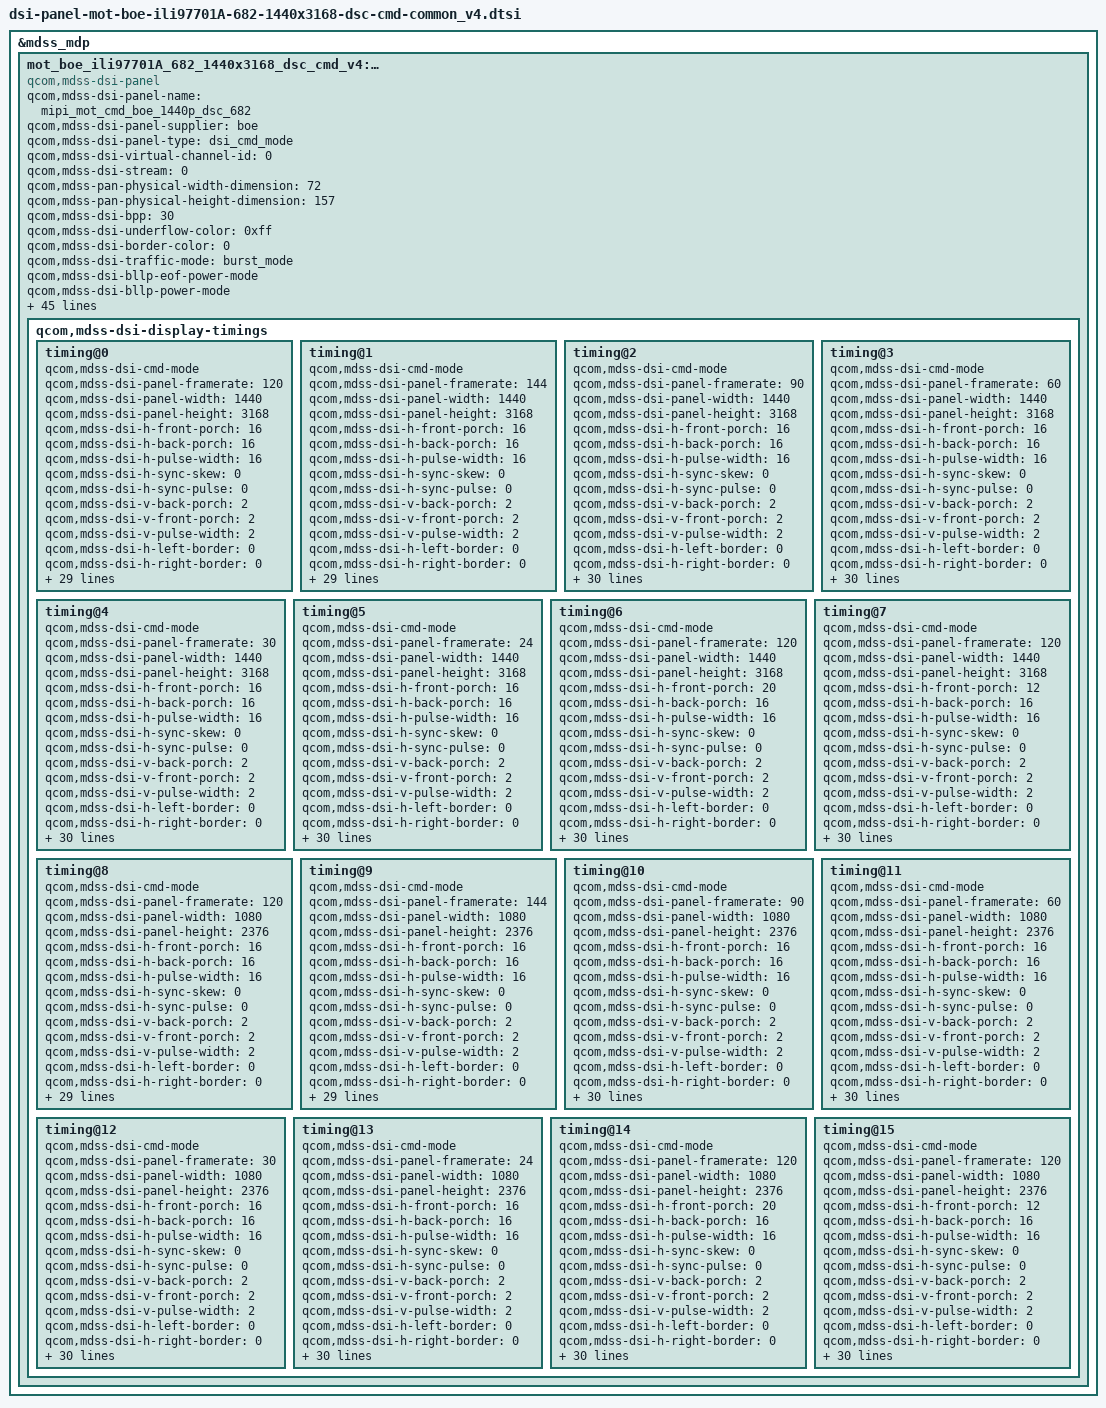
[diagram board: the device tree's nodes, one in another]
/* Copyright (c) 2025-2026, The Linux Foundation. All rights reserved.
 *
 * This program is free software; you can redistribute it and/or modify
 * it under the terms of the GNU General Public License version 2 and
 * only version 2 as published by the Free Software Foundation.
 *
 * This program is distributed in the hope that it will be useful,
 * but WITHOUT ANY WARRANTY; without even the implied warranty of
 * MERCHANTABILITY or FITNESS FOR A PARTICULAR PURPOSE.  See the
 * GNU General Public License for more details.
 */
&mdss_mdp {
mot_boe_ili97701A_682_1440x3168_dsc_cmd_v4: qcom,mdss_dsi_mot_boe_ili97701A_682_1440x3168_dsc_cmd_v4 {
compatible = "qcom,mdss-dsi-panel";
qcom,mdss-dsi-panel-name = "mipi_mot_cmd_boe_1440p_dsc_682";
qcom,mdss-dsi-panel-supplier = "boe";
qcom,mdss-dsi-panel-type = "dsi_cmd_mode";
qcom,mdss-dsi-virtual-channel-id = <0>;
qcom,mdss-dsi-stream = <0>;
qcom,mdss-pan-physical-width-dimension = <72>;
qcom,mdss-pan-physical-height-dimension = <157>;
qcom,mdss-dsi-bpp = <30>;
qcom,mdss-dsi-underflow-color = <0xff>;
qcom,mdss-dsi-border-color = <0>;

qcom,mdss-dsi-traffic-mode = "burst_mode";
qcom,mdss-dsi-bllp-eof-power-mode;
qcom,mdss-dsi-bllp-power-mode;
qcom,mdss-dsi-lane-0-state;
qcom,mdss-dsi-lane-1-state;
qcom,mdss-dsi-lane-2-state;
qcom,mdss-dsi-lane-3-state;

qcom,mdss-dsi-dma-trigger = "trigger_sw";
qcom,mdss-dsi-mdp-trigger = "none";
qcom,mdss-dsi-reset-sequence = <0 3>, <1 1>, <0 1>, <1 20>;
qcom,mdss-dsi-lp11-init;
qcom,mdss-dsi-tx-eot-append;
qcom,mdss-dsi-te-pin-select = <1>;
qcom,mdss-dsi-te-dcs-command = <1>;
qcom,mdss-dsi-te-using-te-pin;

//qcom,bklt-dcs-2bytes-enabled;
qcom,mdss-dsi-bl-min-level = <4>;
qcom,mdss-dsi-bl-max-level = <14056>;
qcom,mdss-dsi-bl-pmic-control-type = "bl_ctrl_dcs";

qcom,mdss-dsi-panel-hdr-enabled;
qcom,mdss-dsi-panel-hdr-color-primaries = <14500 15500 32000
	        17000 15500 30000 8000 3000>;
qcom,mdss-dsi-panel-peak-brightness = <4200000>;

qcom,mdss-dsi-panel-blackness-level = <3230>;

qcom,check_pcd;
qcom,pcd-reg-read-enabled;
qcom,pcd-reg-check-before-read;
qcom,mdss-dsi-panel-pcd-reg-read-length = <1>;
qcom,mdss-dsi-panel-pcd-reg-mask = <0xFF>;
qcom,mdss-dsi-panel-pcd-reg-command = [
		06 01 00 01 00 00 01 C5];
qcom,mdss-dsi-panel-pcd-reg-pass-min = <0x0>;
qcom,mdss-dsi-panel-pcd-reg-pass-max = <0x42>;
qcom,mdss-dsi-panel-pcd-reg-read-delay-ms = <0>; //150ms delay before read pcd reg per IC req
qcom,mdss-dsi-panel-pcd-reg-seq-interval = <30>; //30 seq interval per screen on times
qcom,mdss-dsi-panel-pcd-check-time-interval-in-minutes = <480>; //480 minutes check time interval for pcd reg read

qcom,mdss-dsi-hbm-fod;
qcom,mdss-dsi-hbm-fod-on-command = [
		39 00 00 40 00 00 04 FF 5A A5 00
		39 00 00 00 00 00 02 6E 03
		];

qcom,mdss-dsi-dc-off-command = [
			39 00 00 40 00 00 04 FF 5A A5 08
			39 00 00 40 00 00 02 98 02
			39 00 00 40 00 00 04 FF 5A A5 4F
			39 00 00 40 00 00 02 81 10
			39 00 00 40 00 00 02 88 78
			39 00 00 40 00 00 04 FF 5A A5 23
			39 00 00 40 00 00 02 A9 0E
			39 00 00 40 00 00 02 AA 11
			39 00 00 40 00 00 04 FF 5A A5 24
			39 00 00 40 00 00 02 9D 0E
			39 00 00 40 00 00 02 9E 11
			39 00 00 40 00 00 04 FF 5A A5 23
			39 00 00 40 00 00 02 80 50
			39 00 00 40 00 00 02 A6 FC
			39 00 00 40 00 00 02 A7 00
			39 00 00 40 00 00 04 FF 5A A5 53
			39 00 00 40 00 00 03 95 00 A0
			39 00 00 40 00 00 1f A2 10 10 10 10 48 10 10 10 4B 4B 10 10 10 10 48 10 10 10 4B 4B 10 10 10 10 48 10 10 10 4B 4B
			39 00 00 40 00 00 04 FF 5A A5 00
			39 00 00 40 00 00 02 00 00
			39 00 00 40 00 00 02 00 00
			39 00 00 40 00 00 04 FF 5A A5 53
			39 00 00 40 00 00 02 F0 01
			39 00 00 40 00 00 04 FF 5A A5 00
			39 00 00 40 00 00 02 00 00
			39 00 00 40 00 00 04 FF 5A A5 63
			39 00 00 40 00 00 11 F1 10 10 10 10 10 00 00 00 00 00 00 00 00 00 00 00
			39 00 00 40 00 00 11 F2 00 00 00 00 00 00 00 00 00 00 00 00 00 00 00 00
			39 00 00 40 00 00 11 F3 00 00 00 00 00 20 20 20 20 20 00 00 00 00 00 00
			39 00 00 40 00 00 11 F4 00 00 00 00 00 F0 F0 F0 F0 F0 00 00 00 00 00 00
			39 00 00 40 00 00 04 FF 5A A5 53
			39 00 00 40 00 00 02 F0 00
			39 00 00 40 00 00 04 FF 5A A5 00
			39 00 00 40 00 00 02 00 00
			39 00 00 40 00 00 02 00 00
			39 00 00 40 00 00 04 FF 5A A5 08
			39 00 00 40 00 00 02 98 A6
			39 00 00 40 00 00 04 FF 5A A5 00
			39 00 00 40 00 00 02 00 00
			39 00 00 40 00 00 04 FF 5A A5 4F
			39 00 00 40 00 00 02 8B 78
			39 00 00 40 00 00 04 FF 5A A5 51
			39 00 00 40 00 00 07 A1 44 44 79 7B 22 22
			39 00 00 40 00 00 07 A2 7E 7E 85 85 22 22
			39 00 00 40 00 00 04 FF 5A A5 52
			39 00 00 40 00 00 07 81 46 47 48 4B 00 00
			39 00 00 40 00 00 07 82 4E 4E 50 50 00 00
			39 00 00 40 00 00 04 FF 5A A5 00
			39 00 00 40 00 00 04 FF 5A A5 5A
			39 00 00 40 00 00 04 86 0A 1E 04
			39 00 00 40 00 00 04 8A 12 2E 0F
			39 00 00 40 00 00 04 8F 27 3E 23
			39 00 00 40 00 00 04 94 00 00 00
			39 00 00 40 00 00 04 95 26 24 16
			39 00 00 40 00 00 04 9B 00 00 00
			39 00 00 40 00 00 04 AE 10 2D 07
			39 00 00 40 00 00 04 B3 1C 21 22
			39 00 00 40 00 00 04 B9 24 1C 20
			39 00 00 40 00 00 04 BF 09 00 00
			39 00 00 40 00 00 04 FF 5A A5 5B
			39 00 00 40 00 00 04 DD 39 3A 42
			39 00 00 00 00 00 04 FF 5A A5 00
		];

qcom,mdss-dsi-dc-off-command-state = "dsi_hs_mode";
qcom,mdss-dsi-dc-on-command = [
			39 00 00 40 00 00 04 FF 5A A5 08
			39 00 00 40 00 00 02 98 02
			39 00 00 40 00 00 04 FF 5A A5 4F
			39 00 00 40 00 00 02 81 10
			39 00 00 40 00 00 02 88 78
			39 00 00 40 00 00 04 FF 5A A5 23
			39 00 00 40 00 00 02 A9 8E
			39 00 00 40 00 00 02 AA 11
			39 00 00 40 00 00 04 FF 5A A5 24
			39 00 00 40 00 00 02 9D 8E
			39 00 00 40 00 00 02 9E 11
			39 00 00 40 00 00 04 FF 5A A5 23
			39 00 00 40 00 00 02 80 90
			39 00 00 40 00 00 02 A6 FC
			39 00 00 40 00 00 02 A7 00
			39 00 00 40 00 00 04 FF 5A A5 53
			39 00 00 40 00 00 03 95 44 50
			39 00 00 40 00 00 1f A2 10 10 10 10 48 10 10 74 7B B4 10 10 10 10 48 10 10 74 7B B4 10 10 10 10 48 10 10 74 7B B4
			39 00 00 40 00 00 04 FF 5A A5 00
			39 00 00 40 00 00 02 00 00
			39 00 00 40 00 00 02 00 00
			39 00 00 40 00 00 04 FF 5A A5 53
			39 00 00 40 00 00 02 F0 01
			39 00 00 40 00 00 04 FF 5A A5 00
			39 00 00 40 00 00 02 00 00
			39 00 00 40 00 00 04 FF 5A A5 63
			39 00 00 40 00 00 11 F1 10 10 10 10 10 00 00 00 00 00 00 00 00 00 00 00
			39 00 00 40 00 00 11 F2 00 00 00 00 00 20 20 20 20 20 00 00 00 00 00 00
			39 00 00 40 00 00 11 F3 00 00 00 00 00 00 00 00 00 00 00 00 00 00 00 00
			39 00 00 40 00 00 11 F4 00 00 00 00 00 F0 F0 F0 F0 F0 00 00 00 00 00 00
			39 00 00 40 00 00 04 FF 5A A5 53
			39 00 00 40 00 00 02 F0 00
			39 00 00 40 00 00 04 FF 5A A5 00
			39 00 00 40 00 00 02 00 00
			39 00 00 40 00 00 02 00 00
			39 00 00 40 00 00 04 FF 5A A5 08
			39 00 00 40 00 00 02 98 A6
			39 00 00 40 00 00 04 FF 5A A5 00
			39 00 00 40 00 00 02 00 00
			39 00 00 40 00 00 04 FF 5A A5 4F
			39 00 00 40 00 00 02 8B 78
			39 00 00 40 00 00 04 FF 5A A5 51
			39 00 00 40 00 00 07 A1 44 44 79 79 22 22
			39 00 00 40 00 00 07 A2 78 78 78 78 22 22
			39 00 00 40 00 00 04 FF 5A A5 52
			39 00 00 40 00 00 07 81 46 47 49 48 00 00
			39 00 00 40 00 00 07 82 4A 4A 4B 4B 00 00
			39 00 00 40 00 00 04 FF 5A A5 00
			39 00 00 40 00 00 04 FF 5A A5 5A
			39 00 00 40 00 00 04 86 0A 1E 01
			39 00 00 40 00 00 04 8A 06 38 F4
			39 00 00 40 00 00 04 8F 17 30 F6
			39 00 00 40 00 00 04 94 FC 00 F6
			39 00 00 40 00 00 04 95 33 2A 0D
			39 00 00 40 00 00 04 9B 01 F8 FC
			39 00 00 40 00 00 04 AE 15 2D 07
			39 00 00 40 00 00 04 B3 22 21 22
			39 00 00 40 00 00 04 B9 3A 36 34
			39 00 00 40 00 00 04 BF 00 F8 FE
			39 00 00 40 00 00 04 FF 5A A5 5B
			39 00 00 40 00 00 04 DD 40 44 47
			39 00 00 00 00 00 04 FF 5A A5 00
		];
qcom,mdss-dsi-dc-on-command-state = "dsi_hs_mode";
//qcom,mdss-dsi-nt37705-dc-detect-fps;
//qcom,check_pcd;

qcom,mdss-dsi-display-timings {
	timing@0{
		qcom,mdss-dsi-cmd-mode;
		qcom,mdss-dsi-panel-framerate = <120>;
		qcom,mdss-dsi-panel-width = <1440>;
		qcom,mdss-dsi-panel-height = <3168>;
		qcom,mdss-dsi-h-front-porch = <16>;
		qcom,mdss-dsi-h-back-porch = <16>;
		qcom,mdss-dsi-h-pulse-width = <16>;
		qcom,mdss-dsi-h-sync-skew = <0>;
		qcom,mdss-dsi-h-sync-pulse = <0>;
		qcom,mdss-dsi-v-back-porch = <2>;
		qcom,mdss-dsi-v-front-porch = <2>;
		qcom,mdss-dsi-v-pulse-width = <2>;
		qcom,mdss-dsi-h-left-border = <0>;
		qcom,mdss-dsi-h-right-border = <0>;
		qcom,mdss-dsi-v-top-border = <0>;
		qcom,mdss-dsi-v-bottom-border = <0>;
	        qcom,mdss-dsi-panel-jitter = <0x20 0xa>;
	        qcom,mdss-dsi-timing-switch-command = [
	        	39 00 00 40 00 00 04 FF 5A A5 00 //120hz
			39 00 00 40 00 00 02 60 00
			39 00 00 40 00 00 02 53 20 //dimming disable
			39 00 00 40 00 00 04 FF 5A A5 2D
			39 00 00 40 00 00 02 83 00
			39 00 00 40 00 00 02 F2 00 //TE
			39 00 00 40 00 00 02 CD 01 //dimming disable
			39 00 00 40 00 00 04 FF 5A A5 24
			39 00 00 40 00 00 03 85 31 00 //dimming disable
			39 00 00 40 00 00 03 86 31 00 //dimming disable

			39 00 00 00 00 00 04 FF 5A A5 00

			39 00 00 40 00 00 04 FF 5A A5 00 //scale disable
			39 00 00 40 00 00 02 4B 00
			39 00 00 40 00 00 04 FF 5A A5 04
			39 00 00 40 00 00 02 CF 00
			39 00 00 40 00 00 02 D0 03
			39 00 00 40 00 00 02 D1 00
			39 00 00 40 00 00 02 D2 04
			39 00 00 40 00 00 02 D4 00
			39 00 00 40 00 00 02 D5 C0
			39 00 00 40 00 00 02 D6 00
			39 00 00 40 00 00 02 E0 04
			39 00 00 40 00 00 02 E1 38
			39 00 00 40 00 00 02 E2 09
			39 00 00 40 00 00 02 E3 48
			39 00 00 40 00 00 12 ED 00 00 04 C0 00 00 04 C0 00 33 00 00 00 00 00 00 00

			39 00 00 40 00 00 04 FF 5A A5 07 //10bit 3.75x
			39 00 00 40 00 00 02 8A 01
			39 00 00 40 00 00 03 8B A0 21
			39 00 00 40 00 00 0B 81 00 00 00 00 00 11 00 00 AB 30
                     	39 00 00 40 00 00 0B FE 80 0C 60 05 A0 00 16 02 D0 02
                     	39 00 00 40 00 00 0B FE D0 02 00 02 68 00 20 02 68 00
                     	39 00 00 40 00 00 0B FE 0A 00 0C 04 93 03 78 18 00 10
                     	39 00 00 40 00 00 0B FE F0 07 10 20 00 06 0F 0F 33 0E
                     	39 00 00 40 00 00 0B FE 1C 2A 38 46 54 62 69 70 77 79
                     	39 00 00 40 00 00 0B FE 7B 7D 7E 01 02 22 00 2A 40 2A
                     	39 00 00 40 00 00 0B FE BE 3A FC 3A FA 3A F8 3B 38 3B
                     	39 00 00 40 00 00 0B FE 78 3B B6 4B F6 4C 34 4C 74 5C
                     	39 00 00 40 00 00 0A FE 74 8C F4 00 00 00 00 00 00
			39 00 00 00 00 00 04 FF 5A A5 00
	        ];
		qcom,mdss-dsi-on-command = [
			39 00 00 40 00 00 04 FF 5A A5 07 //10bit 3.75x
			39 00 00 40 00 00 02 8A 01
			39 00 00 40 00 00 03 8B A0 21
			39 00 00 40 00 00 0B 81 00 00 00 00 00 11 00 00 AB 30
                     	39 00 00 40 00 00 0B FE 80 0C 60 05 A0 00 16 02 D0 02
                     	39 00 00 40 00 00 0B FE D0 02 00 02 68 00 20 02 68 00
                     	39 00 00 40 00 00 0B FE 0A 00 0C 04 93 03 78 18 00 10
                     	39 00 00 40 00 00 0B FE F0 07 10 20 00 06 0F 0F 33 0E
                     	39 00 00 40 00 00 0B FE 1C 2A 38 46 54 62 69 70 77 79
                     	39 00 00 40 00 00 0B FE 7B 7D 7E 01 02 22 00 2A 40 2A
                     	39 00 00 40 00 00 0B FE BE 3A FC 3A FA 3A F8 3B 38 3B
                     	39 00 00 40 00 00 0B FE 78 3B B6 4B F6 4C 34 4C 74 5C
                     	39 00 00 40 00 00 0A FE 74 8C F4 00 00 00 00 00 00

			39 00 00 40 00 00 04 FF 5A A5 07
			39 00 00 40 00 00 02 8A 01
			39 00 00 40 00 00 03 8B A0 21
			39 00 00 40 00 00 04 FF 5A A5 31
			39 00 00 40 00 00 02 D0 80
			39 00 00 40 00 00 04 FF 5A A5 08
			39 00 00 40 00 00 02 C8 62
			39 00 00 40 00 00 04 FF 5A A5 21
			39 00 00 40 00 00 02 A4 38
			39 00 00 40 00 00 04 FF 5A A5 23
			39 00 00 40 00 00 02 85 15
			39 00 00 40 00 00 04 FF 5A A5 00
			39 00 00 40 00 00 02 5E 01
			39 00 00 40 00 00 02 60 00
			39 00 00 40 00 00 02 61 0F
			39 00 00 40 00 00 02 6D 01
			39 00 00 40 00 00 02 35 00
			39 00 00 40 00 00 02 53 20
			39 00 00 40 00 00 03 51 00 00
			39 00 00 40 00 00 04 FF 5A A5 00

			39 00 00 40 00 00 04 FF 5A A5 03 //pcd
			39 00 00 40 00 00 02 BD 91
			39 00 00 40 00 00 04 FF 5A A5 00

			39 00 00 40 00 00 04 FF 5A A5 1E //lhbm
			39 00 00 40 00 00 02 C0 10
			39 00 00 40 00 00 04 C1 70 9C C9
			39 00 00 40 00 00 08 C2 FF FF FF 78 E5 7A F0
			39 00 00 40 00 00 27 C5 44 00 00 44 00 00 44 00 00 44 00 00 44 00 00 42 02 EB 21 23 90 10 08 00 00 00 00 00 00 00 00 00 00 00 00 00 00 00
			39 00 00 40 00 00 27 C7 55 FF FF 55 FF FF 54 10 FF 43 80 80 44 00 00 33 90 6B 32 0C AE 20 50 00 00 00 00 00 00 00 00 00 00 00 00 00 00 00
			39 00 00 40 00 00 09 C8 44 00 00 44 00 00 14 00
			39 00 00 40 00 00 02 C9 00
			39 00 00 40 00 00 1a CA EC EC ED ED EE EF F8 FF FC FC F2 FB FF FF FF FF FF FF FF FF FF FF FF FF FF
			39 00 00 40 00 00 1a CB F0 F0 F0 F1 F1 F2 FA FF FF FE EB F0 F2 FF FE FB FF F9 FF FF FF FF FF FF FF
			39 00 00 40 00 00 1a CC EC EC EC ED EE EF F9 FF FF FE E9 ED EF F1 F4 F5 F4 F4 FF FF FF FF FF FF FF
			39 00 00 40 00 00 04 FF 5A A5 24
			39 00 00 40 00 00 02 80 0E
			39 00 00 40 00 00 02 81 11
			39 00 00 40 00 00 02 84 1F
			39 00 00 40 00 00 04 FF 5A A5 00
			39 00 00 40 00 00 02 95 FF
			39 00 00 40 00 00 02 96 0B
			39 00 00 40 00 00 02 97 40
			39 00 00 40 00 00 02 98 02
			39 00 00 40 00 00 02 99 D0

			39 00 00 40 00 00 04 FF 5A A5 00 //120hz
			39 00 00 40 00 00 02 60 00
			39 00 00 40 00 00 02 53 20 //dimming disable
			39 00 00 40 00 00 04 FF 5A A5 2D
			39 00 00 40 00 00 02 83 00
			39 00 00 40 00 00 02 F2 00 //TE
			39 00 00 40 00 00 02 CD 01 //dimming disable
			39 00 00 40 00 00 04 FF 5A A5 24
			39 00 00 40 00 00 03 85 31 00 //dimming disable
			39 00 00 40 00 00 03 86 31 00 //dimming disable

			39 00 00 40 00 00 04 FF 5A A5 08 //esd check
			39 00 00 40 00 00 02 D2 01
			39 00 00 40 00 00 02 D3 00
			39 00 00 40 00 00 02 D4 00
			39 00 00 40 00 00 09 ED FF FF FF FF FF FF FF FF
			39 00 00 40 00 00 09 EE FF FF FF FF FF FF FF FF
			39 00 00 40 00 00 04 FF 5A A5 00

                     	39 00 00 40 00 00 04 FF 5A A5 2D //1hz transition frame
                     	39 00 00 40 00 00 02 97 03
                     	39 00 00 40 00 00 02 B1 03
                     	39 00 00 40 00 00 03 98 03 00
                     	39 00 00 40 00 00 03 99 05 00
                     	39 00 00 40 00 00 03 9A 0B 00
                     	39 00 00 40 00 00 03 9B 17 00
                     	39 00 00 40 00 00 03 A0 00 00
                     	39 00 00 40 00 00 03 A1 01 02

			39 00 00 40 00 00 04 FF 5A A5 08 //esd check fail fix
			39 00 00 40 00 00 02 F5 00
			39 00 00 40 00 00 02 F6 00
			39 00 00 40 00 00 02 F7 00

			39 00 00 40 00 00 04 FF 5A A5 2D //DBV DIMMING for low refreshrate
                     	39 00 00 40 00 00 02 CE 55

			39 00 00 40 00 00 04 FF 5A A5 00 //scale disable
			39 00 00 40 00 00 02 4B 00
			39 00 00 40 00 00 04 FF 5A A5 04
			39 00 00 40 00 00 02 CF 00
			39 00 00 40 00 00 02 D0 03
			39 00 00 40 00 00 02 D1 00
			39 00 00 40 00 00 02 D2 04
			39 00 00 40 00 00 02 D4 00
			39 00 00 40 00 00 02 D5 C0
			39 00 00 40 00 00 02 D6 00
			39 00 00 40 00 00 02 E0 04
			39 00 00 40 00 00 02 E1 38
			39 00 00 40 00 00 02 E2 09
			39 00 00 40 00 00 02 E3 48
			39 00 00 40 00 00 12 ED 00 00 04 C0 00 00 04 C0 00 33 00 00 00 00 00 00 00
			39 00 00 00 00 00 04 FF 5A A5 00

			05 00 00 00 78 00 01 11 //Delay 120ms
			05 00 00 00 14 00 01 29];	/* display on */
		qcom,mdss-dsi-off-command = [
			39 00 00 40 00 00 04 FF 5A A5 00
			05 00 00 00 14 00 01 28		/* display_off */
			05 00 00 00 BE 00 01 10];	/* enter sleep mode */

		qcom,mdss-dsi-on-command-state = "dsi_lp_mode";
		qcom,mdss-dsi-off-command-state = "dsi_lp_mode";
		qcom,mdss-dsi-timing-switch-command-state = "dsi_lp_mode";
		qcom,compression-mode = "dsc";
		/* Why QCOM doesn't use this, even it used 2 encoder
		 * as for that dsi_sw43404_amoled_cmd, for ex */
		/* qcom,mdss-dsc-encoders = <2>; */
		qcom,mdss-dsc-version = <0x11>;
		qcom,mdss-dsc-slice-height = <22>;
		qcom,mdss-dsc-slice-width = <720>;
		qcom,mdss-dsc-slice-per-pkt = <2>;
		qcom,mdss-dsc-bit-per-component = <10>;
		qcom,mdss-dsc-bit-per-pixel = <8>;
		qcom,mdss-dsc-block-prediction-enable;
		qcom,mdss-dsi-pcd-check-enable-command = [
			39 00 00 00 00 00 04 FF 5A A5 03
			];
		qcom,mdss-dsi-pcd-check-enable-command-state = "dsi_hs_mode";
		qcom,mdss-dsi-pcd-check-disable-command = [
			39 00 00 00 00 00 04 FF 5A A5 00
			];
		qcom,mdss-dsi-pcd-check-disable-command-state = "dsi_hs_mode";
	};
	timing@1{
		qcom,mdss-dsi-cmd-mode;
		qcom,mdss-dsi-panel-framerate = <144>;
		qcom,mdss-dsi-panel-width = <1440>;
		qcom,mdss-dsi-panel-height = <3168>;
		qcom,mdss-dsi-h-front-porch = <16>;
		qcom,mdss-dsi-h-back-porch = <16>;
		qcom,mdss-dsi-h-pulse-width = <16>;
		qcom,mdss-dsi-h-sync-skew = <0>;
		qcom,mdss-dsi-h-sync-pulse = <0>;
		qcom,mdss-dsi-v-back-porch = <2>;
		qcom,mdss-dsi-v-front-porch = <2>;
		qcom,mdss-dsi-v-pulse-width = <2>;
		qcom,mdss-dsi-h-left-border = <0>;
		qcom,mdss-dsi-h-right-border = <0>;
		qcom,mdss-dsi-v-top-border = <0>;
		qcom,mdss-dsi-v-bottom-border = <0>;
	        qcom,mdss-dsi-panel-jitter = <0x20 0xa>;
	        qcom,mdss-dsi-timing-switch-command = [
	        	39 00 00 40 00 00 04 FF 5A A5 00 //144hz
			39 00 00 40 00 00 02 60 01
			39 00 00 40 00 00 02 53 20 //dimming disable
			39 00 00 40 00 00 04 FF 5A A5 2D
			39 00 00 40 00 00 02 84 00
			39 00 00 40 00 00 02 CD 01 //dimming disable
			39 00 00 40 00 00 04 FF 5A A5 24
			39 00 00 40 00 00 03 85 31 00 //dimming disable
			39 00 00 40 00 00 03 86 31 00 //dimming disable
			39 00 00 00 00 00 04 FF 5A A5 00

			39 00 00 40 00 00 04 FF 5A A5 00 //scale disable
			39 00 00 40 00 00 02 4B 00
			39 00 00 40 00 00 04 FF 5A A5 04
			39 00 00 40 00 00 02 CF 00
			39 00 00 40 00 00 02 D0 03
			39 00 00 40 00 00 02 D1 00
			39 00 00 40 00 00 02 D2 04
			39 00 00 40 00 00 02 D4 00
			39 00 00 40 00 00 02 D5 C0
			39 00 00 40 00 00 02 D6 00
			39 00 00 40 00 00 02 E0 04
			39 00 00 40 00 00 02 E1 38
			39 00 00 40 00 00 02 E2 09
			39 00 00 40 00 00 02 E3 48
			39 00 00 40 00 00 12 ED 00 00 04 C0 00 00 04 C0 00 33 00 00 00 00 00 00 00

			39 00 00 40 00 00 04 FF 5A A5 07 //10bit 3.75x
			39 00 00 40 00 00 02 8A 01
			39 00 00 40 00 00 03 8B A0 21
			39 00 00 40 00 00 0B 81 00 00 00 00 00 11 00 00 AB 30
                     	39 00 00 40 00 00 0B FE 80 0C 60 05 A0 00 16 02 D0 02
                     	39 00 00 40 00 00 0B FE D0 02 00 02 68 00 20 02 68 00
                     	39 00 00 40 00 00 0B FE 0A 00 0C 04 93 03 78 18 00 10
                     	39 00 00 40 00 00 0B FE F0 07 10 20 00 06 0F 0F 33 0E
                     	39 00 00 40 00 00 0B FE 1C 2A 38 46 54 62 69 70 77 79
                     	39 00 00 40 00 00 0B FE 7B 7D 7E 01 02 22 00 2A 40 2A
                     	39 00 00 40 00 00 0B FE BE 3A FC 3A FA 3A F8 3B 38 3B
                     	39 00 00 40 00 00 0B FE 78 3B B6 4B F6 4C 34 4C 74 5C
                     	39 00 00 40 00 00 0A FE 74 8C F4 00 00 00 00 00 00
			39 00 00 00 00 00 04 FF 5A A5 00
	        ];
		qcom,mdss-dsi-on-command = [
			39 00 00 40 00 00 04 FF 5A A5 07 //10bit 3.75x
			39 00 00 40 00 00 02 8A 01
			39 00 00 40 00 00 03 8B A0 21
			39 00 00 40 00 00 0B 81 00 00 00 00 00 11 00 00 AB 30
                     	39 00 00 40 00 00 0B FE 80 0C 60 05 A0 00 16 02 D0 02
                     	39 00 00 40 00 00 0B FE D0 02 00 02 68 00 20 02 68 00
                     	39 00 00 40 00 00 0B FE 0A 00 0C 04 93 03 78 18 00 10
                     	39 00 00 40 00 00 0B FE F0 07 10 20 00 06 0F 0F 33 0E
                     	39 00 00 40 00 00 0B FE 1C 2A 38 46 54 62 69 70 77 79
                     	39 00 00 40 00 00 0B FE 7B 7D 7E 01 02 22 00 2A 40 2A
                     	39 00 00 40 00 00 0B FE BE 3A FC 3A FA 3A F8 3B 38 3B
                     	39 00 00 40 00 00 0B FE 78 3B B6 4B F6 4C 34 4C 74 5C
                     	39 00 00 40 00 00 0A FE 74 8C F4 00 00 00 00 00 00

			39 00 00 40 00 00 04 FF 5A A5 07
			39 00 00 40 00 00 02 8A 01
			39 00 00 40 00 00 03 8B A0 21
			39 00 00 40 00 00 04 FF 5A A5 31
			39 00 00 40 00 00 02 D0 80
			39 00 00 40 00 00 04 FF 5A A5 08
			39 00 00 40 00 00 02 C8 62
			39 00 00 40 00 00 04 FF 5A A5 21
			39 00 00 40 00 00 02 A4 38
			39 00 00 40 00 00 04 FF 5A A5 23
			39 00 00 40 00 00 02 85 15
			39 00 00 40 00 00 04 FF 5A A5 00
			39 00 00 40 00 00 02 5E 01
			39 00 00 40 00 00 02 60 00
			39 00 00 40 00 00 02 61 0F
			39 00 00 40 00 00 02 6D 01
			39 00 00 40 00 00 02 35 00
			39 00 00 40 00 00 02 53 20
			39 00 00 40 00 00 03 51 00 00
			39 00 00 40 00 00 04 FF 5A A5 00

			39 00 00 40 00 00 04 FF 5A A5 03 //pcd
			39 00 00 40 00 00 02 BD 91
			39 00 00 40 00 00 04 FF 5A A5 00

			39 00 00 40 00 00 04 FF 5A A5 1E //lhbm
			39 00 00 40 00 00 02 C0 10
			39 00 00 40 00 00 04 C1 70 9C C9
			39 00 00 40 00 00 08 C2 FF FF FF 78 E5 7A F0
			39 00 00 40 00 00 27 C5 44 00 00 44 00 00 44 00 00 44 00 00 44 00 00 42 02 EB 21 23 90 10 08 00 00 00 00 00 00 00 00 00 00 00 00 00 00 00
			39 00 00 40 00 00 27 C7 55 FF FF 55 FF FF 54 10 FF 43 80 80 44 00 00 33 90 6B 32 0C AE 20 50 00 00 00 00 00 00 00 00 00 00 00 00 00 00 00
			39 00 00 40 00 00 09 C8 44 00 00 44 00 00 14 00
			39 00 00 40 00 00 02 C9 00
			39 00 00 40 00 00 1a CA EC EC ED ED EE EF F8 FF FC FC F2 FB FF FF FF FF FF FF FF FF FF FF FF FF FF
			39 00 00 40 00 00 1a CB F0 F0 F0 F1 F1 F2 FA FF FF FE EB F0 F2 FF FE FB FF F9 FF FF FF FF FF FF FF
			39 00 00 40 00 00 1a CC EC EC EC ED EE EF F9 FF FF FE E9 ED EF F1 F4 F5 F4 F4 FF FF FF FF FF FF FF
			39 00 00 40 00 00 04 FF 5A A5 24
			39 00 00 40 00 00 02 80 0E
			39 00 00 40 00 00 02 81 11
			39 00 00 40 00 00 02 84 1F
			39 00 00 40 00 00 04 FF 5A A5 00
			39 00 00 40 00 00 02 95 FF
			39 00 00 40 00 00 02 96 0B
			39 00 00 40 00 00 02 97 40
			39 00 00 40 00 00 02 98 02
			39 00 00 40 00 00 02 99 D0

			39 00 00 40 00 00 04 FF 5A A5 00 //144hz
			39 00 00 40 00 00 02 60 01
			39 00 00 40 00 00 02 53 20 //dimming disable
			39 00 00 40 00 00 04 FF 5A A5 2D
			39 00 00 40 00 00 02 84 00
			39 00 00 40 00 00 02 CD 01 //dimming disable
			39 00 00 40 00 00 04 FF 5A A5 24
			39 00 00 40 00 00 03 85 31 00 //dimming disable
			39 00 00 40 00 00 03 86 31 00 //dimming disable

			39 00 00 40 00 00 04 FF 5A A5 08 //esd check
			39 00 00 40 00 00 02 D2 01
			39 00 00 40 00 00 02 D3 00
			39 00 00 40 00 00 02 D4 00
			39 00 00 40 00 00 09 ED FF FF FF FF FF FF FF FF
			39 00 00 40 00 00 09 EE FF FF FF FF FF FF FF FF
			39 00 00 40 00 00 04 FF 5A A5 00

                     	39 00 00 40 00 00 04 FF 5A A5 2D //1hz transition frame
                     	39 00 00 40 00 00 02 97 03
                     	39 00 00 40 00 00 02 B1 03
                     	39 00 00 40 00 00 03 98 03 00
                     	39 00 00 40 00 00 03 99 05 00
                     	39 00 00 40 00 00 03 9A 0B 00
                     	39 00 00 40 00 00 03 9B 17 00
                     	39 00 00 40 00 00 03 A0 00 00
                     	39 00 00 40 00 00 03 A1 01 02

			39 00 00 40 00 00 04 FF 5A A5 08 //esd check fail fix
			39 00 00 40 00 00 02 F5 00
			39 00 00 40 00 00 02 F6 00
			39 00 00 40 00 00 02 F7 00

			39 00 00 40 00 00 04 FF 5A A5 2D //DBV DIMMING for low refreshrate
                     	39 00 00 40 00 00 02 CE 55

			39 00 00 40 00 00 04 FF 5A A5 00 //scale disable
			39 00 00 40 00 00 02 4B 00
			39 00 00 40 00 00 04 FF 5A A5 04
			39 00 00 40 00 00 02 CF 00
			39 00 00 40 00 00 02 D0 03
			39 00 00 40 00 00 02 D1 00
			39 00 00 40 00 00 02 D2 04
			39 00 00 40 00 00 02 D4 00
			39 00 00 40 00 00 02 D5 C0
			39 00 00 40 00 00 02 D6 00
			39 00 00 40 00 00 02 E0 04
			39 00 00 40 00 00 02 E1 38
			39 00 00 40 00 00 02 E2 09
			39 00 00 40 00 00 02 E3 48
			39 00 00 40 00 00 12 ED 00 00 04 C0 00 00 04 C0 00 33 00 00 00 00 00 00 00
			39 00 00 00 00 00 04 FF 5A A5 00

			05 00 00 00 78 00 01 11 //Delay 120ms
			05 00 00 00 14 00 01 29];	/* display on */
		qcom,mdss-dsi-off-command = [
			39 00 00 40 00 00 04 FF 5A A5 00
			05 00 00 00 14 00 01 28		/* display_off */
			05 00 00 00 BE 00 01 10];	/* enter sleep mode */

		qcom,mdss-dsi-on-command-state = "dsi_lp_mode";
		qcom,mdss-dsi-off-command-state = "dsi_lp_mode";
		qcom,mdss-dsi-timing-switch-command-state = "dsi_lp_mode";
		qcom,compression-mode = "dsc";
		/* Why QCOM doesn't use this, even it used 2 encoder
		 * as for that dsi_sw43404_amoled_cmd, for ex */
		/* qcom,mdss-dsc-encoders = <2>; */
		qcom,mdss-dsc-version = <0x11>;
		qcom,mdss-dsc-slice-height = <22>;
		qcom,mdss-dsc-slice-width = <720>;
		qcom,mdss-dsc-slice-per-pkt = <2>;
		qcom,mdss-dsc-bit-per-component = <10>;
		qcom,mdss-dsc-bit-per-pixel = <8>;
		qcom,mdss-dsc-block-prediction-enable;
		qcom,mdss-dsi-pcd-check-enable-command = [
			39 00 00 00 00 00 04 FF 5A A5 03
			];
		qcom,mdss-dsi-pcd-check-enable-command-state = "dsi_hs_mode";
		qcom,mdss-dsi-pcd-check-disable-command = [
			39 00 00 00 00 00 04 FF 5A A5 00
			];
		qcom,mdss-dsi-pcd-check-disable-command-state = "dsi_hs_mode";
	};
	timing@2{
		qcom,mdss-dsi-cmd-mode;
		qcom,mdss-dsi-panel-framerate = <90>;
		qcom,mdss-dsi-panel-width = <1440>;
		qcom,mdss-dsi-panel-height = <3168>;
		qcom,mdss-dsi-h-front-porch = <16>;
		qcom,mdss-dsi-h-back-porch = <16>;
		qcom,mdss-dsi-h-pulse-width = <16>;
		qcom,mdss-dsi-h-sync-skew = <0>;
		qcom,mdss-dsi-h-sync-pulse = <0>;
		qcom,mdss-dsi-v-back-porch = <2>;
		qcom,mdss-dsi-v-front-porch = <2>;
		qcom,mdss-dsi-v-pulse-width = <2>;
		qcom,mdss-dsi-h-left-border = <0>;
		qcom,mdss-dsi-h-right-border = <0>;
		qcom,mdss-dsi-v-top-border = <0>;
		qcom,mdss-dsi-v-bottom-border = <0>;
	        qcom,mdss-dsi-panel-jitter = <0x20 0xa>;
	        qcom,mdss-mdp-transfer-time-us = <7933>;
	        qcom,mdss-dsi-timing-switch-command = [
	        	39 00 00 40 00 00 04 FF 5A A5 00 //90hz
			39 00 00 40 00 00 02 60 02
			39 00 00 40 00 00 02 53 20 //dimming disable
			39 00 00 40 00 00 04 FF 5A A5 2D
			39 00 00 40 00 00 02 85 00
			39 00 00 40 00 00 02 CD 01 //dimming disable
			39 00 00 40 00 00 04 FF 5A A5 24
			39 00 00 40 00 00 03 85 31 00 //dimming disable
			39 00 00 40 00 00 03 86 31 00 //dimming disable
			39 00 00 00 00 00 04 FF 5A A5 00

			39 00 00 40 00 00 04 FF 5A A5 00 //scale disable
			39 00 00 40 00 00 02 4B 00
			39 00 00 40 00 00 04 FF 5A A5 04
			39 00 00 40 00 00 02 CF 00
			39 00 00 40 00 00 02 D0 03
			39 00 00 40 00 00 02 D1 00
			39 00 00 40 00 00 02 D2 04
			39 00 00 40 00 00 02 D4 00
			39 00 00 40 00 00 02 D5 C0
			39 00 00 40 00 00 02 D6 00
			39 00 00 40 00 00 02 E0 04
			39 00 00 40 00 00 02 E1 38
			39 00 00 40 00 00 02 E2 09
			39 00 00 40 00 00 02 E3 48
			39 00 00 40 00 00 12 ED 00 00 04 C0 00 00 04 C0 00 33 00 00 00 00 00 00 00

			39 00 00 40 00 00 04 FF 5A A5 07 //10bit 3.75x
			39 00 00 40 00 00 02 8A 01
			39 00 00 40 00 00 03 8B A0 21
			39 00 00 40 00 00 0B 81 00 00 00 00 00 11 00 00 AB 30
                     	39 00 00 40 00 00 0B FE 80 0C 60 05 A0 00 16 02 D0 02
                     	39 00 00 40 00 00 0B FE D0 02 00 02 68 00 20 02 68 00
                     	39 00 00 40 00 00 0B FE 0A 00 0C 04 93 03 78 18 00 10
                     	39 00 00 40 00 00 0B FE F0 07 10 20 00 06 0F 0F 33 0E
                     	39 00 00 40 00 00 0B FE 1C 2A 38 46 54 62 69 70 77 79
                     	39 00 00 40 00 00 0B FE 7B 7D 7E 01 02 22 00 2A 40 2A
                     	39 00 00 40 00 00 0B FE BE 3A FC 3A FA 3A F8 3B 38 3B
                     	39 00 00 40 00 00 0B FE 78 3B B6 4B F6 4C 34 4C 74 5C
                     	39 00 00 40 00 00 0A FE 74 8C F4 00 00 00 00 00 00
			39 00 00 00 00 00 04 FF 5A A5 00
	        ];
		qcom,mdss-dsi-on-command = [
			39 00 00 40 00 00 04 FF 5A A5 07 //10bit 3.75x
			39 00 00 40 00 00 02 8A 01
			39 00 00 40 00 00 03 8B A0 21
			39 00 00 40 00 00 0B 81 00 00 00 00 00 11 00 00 AB 30
                     	39 00 00 40 00 00 0B FE 80 0C 60 05 A0 00 16 02 D0 02
                     	39 00 00 40 00 00 0B FE D0 02 00 02 68 00 20 02 68 00
                     	39 00 00 40 00 00 0B FE 0A 00 0C 04 93 03 78 18 00 10
                     	39 00 00 40 00 00 0B FE F0 07 10 20 00 06 0F 0F 33 0E
                     	39 00 00 40 00 00 0B FE 1C 2A 38 46 54 62 69 70 77 79
                     	39 00 00 40 00 00 0B FE 7B 7D 7E 01 02 22 00 2A 40 2A
                     	39 00 00 40 00 00 0B FE BE 3A FC 3A FA 3A F8 3B 38 3B
                     	39 00 00 40 00 00 0B FE 78 3B B6 4B F6 4C 34 4C 74 5C
                     	39 00 00 40 00 00 0A FE 74 8C F4 00 00 00 00 00 00

			39 00 00 40 00 00 04 FF 5A A5 07
			39 00 00 40 00 00 02 8A 01
			39 00 00 40 00 00 03 8B A0 21
			39 00 00 40 00 00 04 FF 5A A5 31
			39 00 00 40 00 00 02 D0 80
			39 00 00 40 00 00 04 FF 5A A5 08
			39 00 00 40 00 00 02 C8 62
			39 00 00 40 00 00 04 FF 5A A5 21
			39 00 00 40 00 00 02 A4 38
			39 00 00 40 00 00 04 FF 5A A5 23
			39 00 00 40 00 00 02 85 15
			39 00 00 40 00 00 04 FF 5A A5 00
			39 00 00 40 00 00 02 5E 01
			39 00 00 40 00 00 02 60 00
			39 00 00 40 00 00 02 61 0F
			39 00 00 40 00 00 02 6D 01
			39 00 00 40 00 00 02 35 00
			39 00 00 40 00 00 02 53 20
			39 00 00 40 00 00 03 51 00 00
			39 00 00 40 00 00 04 FF 5A A5 00

			39 00 00 40 00 00 04 FF 5A A5 03 //pcd
			39 00 00 40 00 00 02 BD 91
			39 00 00 40 00 00 04 FF 5A A5 00

			39 00 00 40 00 00 04 FF 5A A5 1E //lhbm
			39 00 00 40 00 00 02 C0 10
			39 00 00 40 00 00 04 C1 70 9C C9
			39 00 00 40 00 00 08 C2 FF FF FF 78 E5 7A F0
			39 00 00 40 00 00 27 C5 44 00 00 44 00 00 44 00 00 44 00 00 44 00 00 42 02 EB 21 23 90 10 08 00 00 00 00 00 00 00 00 00 00 00 00 00 00 00
			39 00 00 40 00 00 27 C7 55 FF FF 55 FF FF 54 10 FF 43 80 80 44 00 00 33 90 6B 32 0C AE 20 50 00 00 00 00 00 00 00 00 00 00 00 00 00 00 00
			39 00 00 40 00 00 09 C8 44 00 00 44 00 00 14 00
			39 00 00 40 00 00 02 C9 00
			39 00 00 40 00 00 1a CA EC EC ED ED EE EF F8 FF FC FC F2 FB FF FF FF FF FF FF FF FF FF FF FF FF FF
			39 00 00 40 00 00 1a CB F0 F0 F0 F1 F1 F2 FA FF FF FE EB F0 F2 FF FE FB FF F9 FF FF FF FF FF FF FF
			39 00 00 40 00 00 1a CC EC EC EC ED EE EF F9 FF FF FE E9 ED EF F1 F4 F5 F4 F4 FF FF FF FF FF FF FF
			39 00 00 40 00 00 04 FF 5A A5 24
			39 00 00 40 00 00 02 80 0E
			39 00 00 40 00 00 02 81 11
			39 00 00 40 00 00 02 84 1F
			39 00 00 40 00 00 04 FF 5A A5 00
			39 00 00 40 00 00 02 95 FF
			39 00 00 40 00 00 02 96 0B
			39 00 00 40 00 00 02 97 40
			39 00 00 40 00 00 02 98 02
			39 00 00 40 00 00 02 99 D0

			39 00 00 40 00 00 04 FF 5A A5 00 //90hz
			39 00 00 40 00 00 02 60 02
			39 00 00 40 00 00 02 53 20 //dimming disable
			39 00 00 40 00 00 04 FF 5A A5 2D
			39 00 00 40 00 00 02 85 00
			39 00 00 40 00 00 02 CD 01 //dimming disable
			39 00 00 40 00 00 04 FF 5A A5 24
			39 00 00 40 00 00 03 85 31 00 //dimming disable
			39 00 00 40 00 00 03 86 31 00 //dimming disable

			39 00 00 40 00 00 04 FF 5A A5 08 //esd check
			39 00 00 40 00 00 02 D2 01
			39 00 00 40 00 00 02 D3 00
			39 00 00 40 00 00 02 D4 00
			39 00 00 40 00 00 09 ED FF FF FF FF FF FF FF FF
			39 00 00 40 00 00 09 EE FF FF FF FF FF FF FF FF
			39 00 00 40 00 00 04 FF 5A A5 00

                     	39 00 00 40 00 00 04 FF 5A A5 2D //1hz transition frame
                     	39 00 00 40 00 00 02 97 03
                     	39 00 00 40 00 00 02 B1 03
                     	39 00 00 40 00 00 03 98 03 00
                     	39 00 00 40 00 00 03 99 05 00
                     	39 00 00 40 00 00 03 9A 0B 00
                     	39 00 00 40 00 00 03 9B 17 00
                     	39 00 00 40 00 00 03 A0 00 00
                     	39 00 00 40 00 00 03 A1 01 02

			39 00 00 40 00 00 04 FF 5A A5 08 //esd check fail fix
			39 00 00 40 00 00 02 F5 00
			39 00 00 40 00 00 02 F6 00
			39 00 00 40 00 00 02 F7 00

			39 00 00 40 00 00 04 FF 5A A5 2D //DBV DIMMING for low refreshrate
                     	39 00 00 40 00 00 02 CE 55

			39 00 00 40 00 00 04 FF 5A A5 00 //scale disable
			39 00 00 40 00 00 02 4B 00
			39 00 00 40 00 00 04 FF 5A A5 04
			39 00 00 40 00 00 02 CF 00
			39 00 00 40 00 00 02 D0 03
			39 00 00 40 00 00 02 D1 00
			39 00 00 40 00 00 02 D2 04
			39 00 00 40 00 00 02 D4 00
			39 00 00 40 00 00 02 D5 C0
			39 00 00 40 00 00 02 D6 00
			39 00 00 40 00 00 02 E0 04
			39 00 00 40 00 00 02 E1 38
			39 00 00 40 00 00 02 E2 09
			39 00 00 40 00 00 02 E3 48
			39 00 00 40 00 00 12 ED 00 00 04 C0 00 00 04 C0 00 33 00 00 00 00 00 00 00
			39 00 00 00 00 00 04 FF 5A A5 00

			05 00 00 00 78 00 01 11 //Delay 120ms
			05 00 00 00 14 00 01 29];	/* display on */
		qcom,mdss-dsi-off-command = [
			39 00 00 40 00 00 04 FF 5A A5 00
			05 00 00 00 14 00 01 28		/* display_off */
			05 00 00 00 BE 00 01 10];	/* enter sleep mode */

		qcom,mdss-dsi-on-command-state = "dsi_lp_mode";
		qcom,mdss-dsi-off-command-state = "dsi_lp_mode";
		qcom,mdss-dsi-timing-switch-command-state = "dsi_lp_mode";
		qcom,compression-mode = "dsc";
		/* Why QCOM doesn't use this, even it used 2 encoder
		 * as for that dsi_sw43404_amoled_cmd, for ex */
		/* qcom,mdss-dsc-encoders = <2>; */
		qcom,mdss-dsc-version = <0x11>;
		qcom,mdss-dsc-slice-height = <22>;
		qcom,mdss-dsc-slice-width = <720>;
		qcom,mdss-dsc-slice-per-pkt = <2>;
		qcom,mdss-dsc-bit-per-component = <10>;
		qcom,mdss-dsc-bit-per-pixel = <8>;
		qcom,mdss-dsc-block-prediction-enable;
		qcom,mdss-dsi-pcd-check-enable-command = [
			39 00 00 00 00 00 04 FF 5A A5 03
			];
		qcom,mdss-dsi-pcd-check-enable-command-state = "dsi_hs_mode";
		qcom,mdss-dsi-pcd-check-disable-command = [
			39 00 00 00 00 00 04 FF 5A A5 00
			];
		qcom,mdss-dsi-pcd-check-disable-command-state = "dsi_hs_mode";
	};
	timing@3{
		qcom,mdss-dsi-cmd-mode;
		qcom,mdss-dsi-panel-framerate = <60>;
		qcom,mdss-dsi-panel-width = <1440>;
		qcom,mdss-dsi-panel-height = <3168>;
		qcom,mdss-dsi-h-front-porch = <16>;
		qcom,mdss-dsi-h-back-porch = <16>;
		qcom,mdss-dsi-h-pulse-width = <16>;
		qcom,mdss-dsi-h-sync-skew = <0>;
		qcom,mdss-dsi-h-sync-pulse = <0>;
		qcom,mdss-dsi-v-back-porch = <2>;
		qcom,mdss-dsi-v-front-porch = <2>;
		qcom,mdss-dsi-v-pulse-width = <2>;
		qcom,mdss-dsi-h-left-border = <0>;
		qcom,mdss-dsi-h-right-border = <0>;
		qcom,mdss-dsi-v-top-border = <0>;
		qcom,mdss-dsi-v-bottom-border = <0>;
	        qcom,mdss-dsi-panel-jitter = <0x20 0xa>;
	        qcom,mdss-mdp-transfer-time-us = <7933>;
	        qcom,mdss-dsi-timing-switch-command = [
	        	39 00 00 40 00 00 04 FF 5A A5 00 //60hz
			39 00 00 40 00 00 02 60 00
			39 00 00 40 00 00 02 53 20 //dimming disable
			39 00 00 40 00 00 04 FF 5A A5 2D
			39 00 00 40 00 00 02 83 01
			39 00 00 40 00 00 02 F2 01 //TE
			39 00 00 40 00 00 02 CD 01 //dimming disable
			39 00 00 40 00 00 04 FF 5A A5 24
			39 00 00 40 00 00 03 85 31 00 //dimming disable
			39 00 00 40 00 00 03 86 31 00 //dimming disable
			39 00 00 00 00 00 04 FF 5A A5 00

			39 00 00 40 00 00 04 FF 5A A5 00 //scale disable
			39 00 00 40 00 00 02 4B 00
			39 00 00 40 00 00 04 FF 5A A5 04
			39 00 00 40 00 00 02 CF 00
			39 00 00 40 00 00 02 D0 03
			39 00 00 40 00 00 02 D1 00
			39 00 00 40 00 00 02 D2 04
			39 00 00 40 00 00 02 D4 00
			39 00 00 40 00 00 02 D5 C0
			39 00 00 40 00 00 02 D6 00
			39 00 00 40 00 00 02 E0 04
			39 00 00 40 00 00 02 E1 38
			39 00 00 40 00 00 02 E2 09
			39 00 00 40 00 00 02 E3 48
			39 00 00 40 00 00 12 ED 00 00 04 C0 00 00 04 C0 00 33 00 00 00 00 00 00 00

			39 00 00 40 00 00 04 FF 5A A5 07 //10bit 3.75x
			39 00 00 40 00 00 02 8A 01
			39 00 00 40 00 00 03 8B A0 21
			39 00 00 40 00 00 0B 81 00 00 00 00 00 11 00 00 AB 30
                     	39 00 00 40 00 00 0B FE 80 0C 60 05 A0 00 16 02 D0 02
                     	39 00 00 40 00 00 0B FE D0 02 00 02 68 00 20 02 68 00
                     	39 00 00 40 00 00 0B FE 0A 00 0C 04 93 03 78 18 00 10
                     	39 00 00 40 00 00 0B FE F0 07 10 20 00 06 0F 0F 33 0E
                     	39 00 00 40 00 00 0B FE 1C 2A 38 46 54 62 69 70 77 79
                     	39 00 00 40 00 00 0B FE 7B 7D 7E 01 02 22 00 2A 40 2A
                     	39 00 00 40 00 00 0B FE BE 3A FC 3A FA 3A F8 3B 38 3B
                     	39 00 00 40 00 00 0B FE 78 3B B6 4B F6 4C 34 4C 74 5C
                     	39 00 00 40 00 00 0A FE 74 8C F4 00 00 00 00 00 00
			39 00 00 00 00 00 04 FF 5A A5 00
	        ];
		qcom,mdss-dsi-on-command = [
			39 00 00 40 00 00 04 FF 5A A5 07 //10bit 3.75x
			39 00 00 40 00 00 02 8A 01
			39 00 00 40 00 00 03 8B A0 21
			39 00 00 40 00 00 0B 81 00 00 00 00 00 11 00 00 AB 30
                     	39 00 00 40 00 00 0B FE 80 0C 60 05 A0 00 16 02 D0 02
                     	39 00 00 40 00 00 0B FE D0 02 00 02 68 00 20 02 68 00
                     	39 00 00 40 00 00 0B FE 0A 00 0C 04 93 03 78 18 00 10
                     	39 00 00 40 00 00 0B FE F0 07 10 20 00 06 0F 0F 33 0E
                     	39 00 00 40 00 00 0B FE 1C 2A 38 46 54 62 69 70 77 79
                     	39 00 00 40 00 00 0B FE 7B 7D 7E 01 02 22 00 2A 40 2A
                     	39 00 00 40 00 00 0B FE BE 3A FC 3A FA 3A F8 3B 38 3B
                     	39 00 00 40 00 00 0B FE 78 3B B6 4B F6 4C 34 4C 74 5C
                     	39 00 00 40 00 00 0A FE 74 8C F4 00 00 00 00 00 00

			39 00 00 40 00 00 04 FF 5A A5 07
			39 00 00 40 00 00 02 8A 01
			39 00 00 40 00 00 03 8B A0 21
			39 00 00 40 00 00 04 FF 5A A5 31
			39 00 00 40 00 00 02 D0 80
			39 00 00 40 00 00 04 FF 5A A5 08
			39 00 00 40 00 00 02 C8 62
			39 00 00 40 00 00 04 FF 5A A5 21
			39 00 00 40 00 00 02 A4 38
			39 00 00 40 00 00 04 FF 5A A5 23
			39 00 00 40 00 00 02 85 15
			39 00 00 40 00 00 04 FF 5A A5 00
			39 00 00 40 00 00 02 5E 01
			39 00 00 40 00 00 02 60 00
			39 00 00 40 00 00 02 61 0F
			39 00 00 40 00 00 02 6D 01
			39 00 00 40 00 00 02 35 00
			39 00 00 40 00 00 02 53 20
			39 00 00 40 00 00 03 51 00 00
			39 00 00 40 00 00 04 FF 5A A5 00

			39 00 00 40 00 00 04 FF 5A A5 03 //pcd
			39 00 00 40 00 00 02 BD 91
			39 00 00 40 00 00 04 FF 5A A5 00

			39 00 00 40 00 00 04 FF 5A A5 1E //lhbm
			39 00 00 40 00 00 02 C0 10
			39 00 00 40 00 00 04 C1 70 9C C9
			39 00 00 40 00 00 08 C2 FF FF FF 78 E5 7A F0
			39 00 00 40 00 00 27 C5 44 00 00 44 00 00 44 00 00 44 00 00 44 00 00 42 02 EB 21 23 90 10 08 00 00 00 00 00 00 00 00 00 00 00 00 00 00 00
			39 00 00 40 00 00 27 C7 55 FF FF 55 FF FF 54 10 FF 43 80 80 44 00 00 33 90 6B 32 0C AE 20 50 00 00 00 00 00 00 00 00 00 00 00 00 00 00 00
			39 00 00 40 00 00 09 C8 44 00 00 44 00 00 14 00
			39 00 00 40 00 00 02 C9 00
			39 00 00 40 00 00 1a CA EC EC ED ED EE EF F8 FF FC FC F2 FB FF FF FF FF FF FF FF FF FF FF FF FF FF
			39 00 00 40 00 00 1a CB F0 F0 F0 F1 F1 F2 FA FF FF FE EB F0 F2 FF FE FB FF F9 FF FF FF FF FF FF FF
			39 00 00 40 00 00 1a CC EC EC EC ED EE EF F9 FF FF FE E9 ED EF F1 F4 F5 F4 F4 FF FF FF FF FF FF FF
			39 00 00 40 00 00 04 FF 5A A5 24
			39 00 00 40 00 00 02 80 0E
			39 00 00 40 00 00 02 81 11
			39 00 00 40 00 00 02 84 1F
			39 00 00 40 00 00 04 FF 5A A5 00
			39 00 00 40 00 00 02 95 FF
			39 00 00 40 00 00 02 96 0B
			39 00 00 40 00 00 02 97 40
			39 00 00 40 00 00 02 98 02
			39 00 00 40 00 00 02 99 D0

			39 00 00 40 00 00 04 FF 5A A5 00 //60hz
			39 00 00 40 00 00 02 60 00
			39 00 00 40 00 00 02 53 20 //dimming disable
			39 00 00 40 00 00 04 FF 5A A5 2D
			39 00 00 40 00 00 02 83 01
			39 00 00 40 00 00 02 F2 01 //TE
			39 00 00 40 00 00 02 CD 01 //dimming disable
			39 00 00 40 00 00 04 FF 5A A5 24
			39 00 00 40 00 00 03 85 31 00 //dimming disable
			39 00 00 40 00 00 03 86 31 00 //dimming disable

			39 00 00 40 00 00 04 FF 5A A5 08 //esd check
			39 00 00 40 00 00 02 D2 01
			39 00 00 40 00 00 02 D3 00
			39 00 00 40 00 00 02 D4 00
			39 00 00 40 00 00 09 ED FF FF FF FF FF FF FF FF
			39 00 00 40 00 00 09 EE FF FF FF FF FF FF FF FF
			39 00 00 40 00 00 04 FF 5A A5 00

                     	39 00 00 40 00 00 04 FF 5A A5 2D //1hz transition frame
                     	39 00 00 40 00 00 02 97 03
                     	39 00 00 40 00 00 02 B1 03
                     	39 00 00 40 00 00 03 98 03 00
                     	39 00 00 40 00 00 03 99 05 00
                     	39 00 00 40 00 00 03 9A 0B 00
                     	39 00 00 40 00 00 03 9B 17 00
                     	39 00 00 40 00 00 03 A0 00 00
                     	39 00 00 40 00 00 03 A1 01 02

			39 00 00 40 00 00 04 FF 5A A5 08 //esd check fail fix
			39 00 00 40 00 00 02 F5 00
			39 00 00 40 00 00 02 F6 00
			39 00 00 40 00 00 02 F7 00

			39 00 00 40 00 00 04 FF 5A A5 2D //DBV DIMMING for low refreshrate
                     	39 00 00 40 00 00 02 CE 55

			39 00 00 40 00 00 04 FF 5A A5 00 //scale disable
			39 00 00 40 00 00 02 4B 00
			39 00 00 40 00 00 04 FF 5A A5 04
			39 00 00 40 00 00 02 CF 00
			39 00 00 40 00 00 02 D0 03
			39 00 00 40 00 00 02 D1 00
			39 00 00 40 00 00 02 D2 04
			39 00 00 40 00 00 02 D4 00
			39 00 00 40 00 00 02 D5 C0
			39 00 00 40 00 00 02 D6 00
			39 00 00 40 00 00 02 E0 04
			39 00 00 40 00 00 02 E1 38
			39 00 00 40 00 00 02 E2 09
			39 00 00 40 00 00 02 E3 48
			39 00 00 40 00 00 12 ED 00 00 04 C0 00 00 04 C0 00 33 00 00 00 00 00 00 00
			39 00 00 00 00 00 04 FF 5A A5 00

			05 00 00 00 78 00 01 11 //Delay 120ms
			05 00 00 00 14 00 01 29];	/* display on */
		qcom,mdss-dsi-off-command = [
			39 00 00 40 00 00 04 FF 5A A5 00
			05 00 00 00 14 00 01 28		/* display_off */
			05 00 00 00 BE 00 01 10];	/* enter sleep mode */

		qcom,mdss-dsi-on-command-state = "dsi_lp_mode";
		qcom,mdss-dsi-off-command-state = "dsi_lp_mode";
		qcom,mdss-dsi-timing-switch-command-state = "dsi_lp_mode";
		qcom,compression-mode = "dsc";
		/* Why QCOM doesn't use this, even it used 2 encoder
		 * as for that dsi_sw43404_amoled_cmd, for ex */
		/* qcom,mdss-dsc-encoders = <2>; */
		qcom,mdss-dsc-version = <0x11>;
		qcom,mdss-dsc-slice-height = <22>;
		qcom,mdss-dsc-slice-width = <720>;
		qcom,mdss-dsc-slice-per-pkt = <2>;
		qcom,mdss-dsc-bit-per-component = <10>;
		qcom,mdss-dsc-bit-per-pixel = <8>;
		qcom,mdss-dsc-block-prediction-enable;
		qcom,mdss-dsi-pcd-check-enable-command = [
			39 00 00 00 00 00 04 FF 5A A5 03
			];
		qcom,mdss-dsi-pcd-check-enable-command-state = "dsi_hs_mode";
		qcom,mdss-dsi-pcd-check-disable-command = [
			39 00 00 00 00 00 04 FF 5A A5 00
			];
		qcom,mdss-dsi-pcd-check-disable-command-state = "dsi_hs_mode";
	};
	timing@4{
		qcom,mdss-dsi-cmd-mode;
		qcom,mdss-dsi-panel-framerate = <30>;
		qcom,mdss-dsi-panel-width = <1440>;
		qcom,mdss-dsi-panel-height = <3168>;
		qcom,mdss-dsi-h-front-porch = <16>;
		qcom,mdss-dsi-h-back-porch = <16>;
		qcom,mdss-dsi-h-pulse-width = <16>;
		qcom,mdss-dsi-h-sync-skew = <0>;
		qcom,mdss-dsi-h-sync-pulse = <0>;
		qcom,mdss-dsi-v-back-porch = <2>;
		qcom,mdss-dsi-v-front-porch = <2>;
		qcom,mdss-dsi-v-pulse-width = <2>;
		qcom,mdss-dsi-h-left-border = <0>;
		qcom,mdss-dsi-h-right-border = <0>;
		qcom,mdss-dsi-v-top-border = <0>;
		qcom,mdss-dsi-v-bottom-border = <0>;
	        qcom,mdss-dsi-panel-jitter = <0x20 0xa>;
	        qcom,mdss-mdp-transfer-time-us = <7933>;
	        qcom,mdss-dsi-timing-switch-command = [
	        	39 00 00 40 00 00 04 FF 5A A5 00 //30hz
			39 00 00 40 00 00 02 60 00
			39 00 00 40 00 00 02 53 28 //dimming enable
			39 00 00 40 00 00 04 FF 5A A5 2D
			39 00 00 40 00 00 02 83 03
			39 00 00 40 00 00 02 F2 03 //TE
			39 00 00 40 00 00 02 CD 21 //dimming enable
			39 00 00 40 00 00 04 FF 5A A5 24
			39 00 00 40 00 00 03 85 31 80 //dimming enable
			39 00 00 40 00 00 03 86 31 80 //dimming enable
			39 00 00 00 00 00 04 FF 5A A5 00

			39 00 00 40 00 00 04 FF 5A A5 00 //scale disable
			39 00 00 40 00 00 02 4B 00
			39 00 00 40 00 00 04 FF 5A A5 04
			39 00 00 40 00 00 02 CF 00
			39 00 00 40 00 00 02 D0 03
			39 00 00 40 00 00 02 D1 00
			39 00 00 40 00 00 02 D2 04
			39 00 00 40 00 00 02 D4 00
			39 00 00 40 00 00 02 D5 C0
			39 00 00 40 00 00 02 D6 00
			39 00 00 40 00 00 02 E0 04
			39 00 00 40 00 00 02 E1 38
			39 00 00 40 00 00 02 E2 09
			39 00 00 40 00 00 02 E3 48
			39 00 00 40 00 00 12 ED 00 00 04 C0 00 00 04 C0 00 33 00 00 00 00 00 00 00

			39 00 00 40 00 00 04 FF 5A A5 07 //10bit 3.75x
			39 00 00 40 00 00 02 8A 01
			39 00 00 40 00 00 03 8B A0 21
			39 00 00 40 00 00 0B 81 00 00 00 00 00 11 00 00 AB 30
                     	39 00 00 40 00 00 0B FE 80 0C 60 05 A0 00 16 02 D0 02
                     	39 00 00 40 00 00 0B FE D0 02 00 02 68 00 20 02 68 00
                     	39 00 00 40 00 00 0B FE 0A 00 0C 04 93 03 78 18 00 10
                     	39 00 00 40 00 00 0B FE F0 07 10 20 00 06 0F 0F 33 0E
                     	39 00 00 40 00 00 0B FE 1C 2A 38 46 54 62 69 70 77 79
                     	39 00 00 40 00 00 0B FE 7B 7D 7E 01 02 22 00 2A 40 2A
                     	39 00 00 40 00 00 0B FE BE 3A FC 3A FA 3A F8 3B 38 3B
                     	39 00 00 40 00 00 0B FE 78 3B B6 4B F6 4C 34 4C 74 5C
                     	39 00 00 40 00 00 0A FE 74 8C F4 00 00 00 00 00 00
			39 00 00 00 00 00 04 FF 5A A5 00
	        ];
		qcom,mdss-dsi-on-command = [
			39 00 00 40 00 00 04 FF 5A A5 07 //10bit 3.75x
			39 00 00 40 00 00 02 8A 01
			39 00 00 40 00 00 03 8B A0 21
			39 00 00 40 00 00 0B 81 00 00 00 00 00 11 00 00 AB 30
                     	39 00 00 40 00 00 0B FE 80 0C 60 05 A0 00 16 02 D0 02
                     	39 00 00 40 00 00 0B FE D0 02 00 02 68 00 20 02 68 00
                     	39 00 00 40 00 00 0B FE 0A 00 0C 04 93 03 78 18 00 10
                     	39 00 00 40 00 00 0B FE F0 07 10 20 00 06 0F 0F 33 0E
                     	39 00 00 40 00 00 0B FE 1C 2A 38 46 54 62 69 70 77 79
                     	39 00 00 40 00 00 0B FE 7B 7D 7E 01 02 22 00 2A 40 2A
                     	39 00 00 40 00 00 0B FE BE 3A FC 3A FA 3A F8 3B 38 3B
                     	39 00 00 40 00 00 0B FE 78 3B B6 4B F6 4C 34 4C 74 5C
                     	39 00 00 40 00 00 0A FE 74 8C F4 00 00 00 00 00 00

			39 00 00 40 00 00 04 FF 5A A5 07
			39 00 00 40 00 00 02 8A 01
			39 00 00 40 00 00 03 8B A0 21
			39 00 00 40 00 00 04 FF 5A A5 31
			39 00 00 40 00 00 02 D0 80
			39 00 00 40 00 00 04 FF 5A A5 08
			39 00 00 40 00 00 02 C8 62
			39 00 00 40 00 00 04 FF 5A A5 21
			39 00 00 40 00 00 02 A4 38
			39 00 00 40 00 00 04 FF 5A A5 23
			39 00 00 40 00 00 02 85 15
			39 00 00 40 00 00 04 FF 5A A5 00
			39 00 00 40 00 00 02 5E 01
			39 00 00 40 00 00 02 60 00
			39 00 00 40 00 00 02 61 0F
			39 00 00 40 00 00 02 6D 01
			39 00 00 40 00 00 02 35 00
			39 00 00 40 00 00 02 53 20
			39 00 00 40 00 00 03 51 00 00
			39 00 00 40 00 00 04 FF 5A A5 00

			39 00 00 40 00 00 04 FF 5A A5 03 //pcd
			39 00 00 40 00 00 02 BD 91
			39 00 00 40 00 00 04 FF 5A A5 00

			39 00 00 40 00 00 04 FF 5A A5 1E //lhbm
			39 00 00 40 00 00 02 C0 10
			39 00 00 40 00 00 04 C1 70 9C C9
			39 00 00 40 00 00 08 C2 FF FF FF 78 E5 7A F0
			39 00 00 40 00 00 27 C5 44 00 00 44 00 00 44 00 00 44 00 00 44 00 00 42 02 EB 21 23 90 10 08 00 00 00 00 00 00 00 00 00 00 00 00 00 00 00
			39 00 00 40 00 00 27 C7 55 FF FF 55 FF FF 54 10 FF 43 80 80 44 00 00 33 90 6B 32 0C AE 20 50 00 00 00 00 00 00 00 00 00 00 00 00 00 00 00
			39 00 00 40 00 00 09 C8 44 00 00 44 00 00 14 00
			39 00 00 40 00 00 02 C9 00
			39 00 00 40 00 00 1a CA EC EC ED ED EE EF F8 FF FC FC F2 FB FF FF FF FF FF FF FF FF FF FF FF FF FF
			39 00 00 40 00 00 1a CB F0 F0 F0 F1 F1 F2 FA FF FF FE EB F0 F2 FF FE FB FF F9 FF FF FF FF FF FF FF
			39 00 00 40 00 00 1a CC EC EC EC ED EE EF F9 FF FF FE E9 ED EF F1 F4 F5 F4 F4 FF FF FF FF FF FF FF
			39 00 00 40 00 00 04 FF 5A A5 24
			39 00 00 40 00 00 02 80 0E
			39 00 00 40 00 00 02 81 11
			39 00 00 40 00 00 02 84 1F
			39 00 00 40 00 00 04 FF 5A A5 00
			39 00 00 40 00 00 02 95 FF
			39 00 00 40 00 00 02 96 0B
			39 00 00 40 00 00 02 97 40
			39 00 00 40 00 00 02 98 02
			39 00 00 40 00 00 02 99 D0

			39 00 00 40 00 00 04 FF 5A A5 00 //30hz
			39 00 00 40 00 00 02 60 00
			39 00 00 40 00 00 02 53 28 //dimming enable
			39 00 00 40 00 00 04 FF 5A A5 2D
			39 00 00 40 00 00 02 83 03
			39 00 00 40 00 00 02 F2 03 //TE
			39 00 00 40 00 00 02 CD 21 //dimming enable
			39 00 00 40 00 00 04 FF 5A A5 24
			39 00 00 40 00 00 03 85 31 80 //dimming enable
			39 00 00 40 00 00 03 86 31 80 //dimming enable

			39 00 00 40 00 00 04 FF 5A A5 08 //esd check
			39 00 00 40 00 00 02 D2 01
			39 00 00 40 00 00 02 D3 00
			39 00 00 40 00 00 02 D4 00
			39 00 00 40 00 00 09 ED FF FF FF FF FF FF FF FF
			39 00 00 40 00 00 09 EE FF FF FF FF FF FF FF FF
			39 00 00 40 00 00 04 FF 5A A5 00

                     	39 00 00 40 00 00 04 FF 5A A5 2D //1hz transition frame
                     	39 00 00 40 00 00 02 97 03
                     	39 00 00 40 00 00 02 B1 03
                     	39 00 00 40 00 00 03 98 03 00
                     	39 00 00 40 00 00 03 99 05 00
                     	39 00 00 40 00 00 03 9A 0B 00
                     	39 00 00 40 00 00 03 9B 17 00
                     	39 00 00 40 00 00 03 A0 00 00
                     	39 00 00 40 00 00 03 A1 01 02

			39 00 00 40 00 00 04 FF 5A A5 08 //esd check fail fix
			39 00 00 40 00 00 02 F5 00
			39 00 00 40 00 00 02 F6 00
			39 00 00 40 00 00 02 F7 00

			39 00 00 40 00 00 04 FF 5A A5 2D //DBV DIMMING for low refreshrate
                     	39 00 00 40 00 00 02 CE 55

			39 00 00 40 00 00 04 FF 5A A5 00 //scale disable
			39 00 00 40 00 00 02 4B 00
			39 00 00 40 00 00 04 FF 5A A5 04
			39 00 00 40 00 00 02 CF 00
			39 00 00 40 00 00 02 D0 03
			39 00 00 40 00 00 02 D1 00
			39 00 00 40 00 00 02 D2 04
			39 00 00 40 00 00 02 D4 00
			39 00 00 40 00 00 02 D5 C0
			39 00 00 40 00 00 02 D6 00
			39 00 00 40 00 00 02 E0 04
			39 00 00 40 00 00 02 E1 38
			39 00 00 40 00 00 02 E2 09
			39 00 00 40 00 00 02 E3 48
			39 00 00 40 00 00 12 ED 00 00 04 C0 00 00 04 C0 00 33 00 00 00 00 00 00 00
			39 00 00 00 00 00 04 FF 5A A5 00

			05 00 00 00 78 00 01 11 //Delay 120ms
			05 00 00 00 14 00 01 29];	/* display on */
		qcom,mdss-dsi-off-command = [
			39 00 00 40 00 00 04 FF 5A A5 00
			05 00 00 00 14 00 01 28		/* display_off */
			05 00 00 00 BE 00 01 10];	/* enter sleep mode */

		qcom,mdss-dsi-on-command-state = "dsi_lp_mode";
		qcom,mdss-dsi-off-command-state = "dsi_lp_mode";
		qcom,mdss-dsi-timing-switch-command-state = "dsi_lp_mode";
		qcom,compression-mode = "dsc";
		/* Why QCOM doesn't use this, even it used 2 encoder
		 * as for that dsi_sw43404_amoled_cmd, for ex */
		/* qcom,mdss-dsc-encoders = <2>; */
		qcom,mdss-dsc-version = <0x11>;
		qcom,mdss-dsc-slice-height = <22>;
		qcom,mdss-dsc-slice-width = <720>;
		qcom,mdss-dsc-slice-per-pkt = <2>;
		qcom,mdss-dsc-bit-per-component = <10>;
		qcom,mdss-dsc-bit-per-pixel = <8>;
		qcom,mdss-dsc-block-prediction-enable;
		qcom,mdss-dsi-pcd-check-enable-command = [
			39 00 00 00 00 00 04 FF 5A A5 03
			];
		qcom,mdss-dsi-pcd-check-enable-command-state = "dsi_hs_mode";
		qcom,mdss-dsi-pcd-check-disable-command = [
			39 00 00 00 00 00 04 FF 5A A5 00
			];
		qcom,mdss-dsi-pcd-check-disable-command-state = "dsi_hs_mode";
	};
	timing@5{
		qcom,mdss-dsi-cmd-mode;
		qcom,mdss-dsi-panel-framerate = <24>;
		qcom,mdss-dsi-panel-width = <1440>;
		qcom,mdss-dsi-panel-height = <3168>;
		qcom,mdss-dsi-h-front-porch = <16>;
		qcom,mdss-dsi-h-back-porch = <16>;
		qcom,mdss-dsi-h-pulse-width = <16>;
		qcom,mdss-dsi-h-sync-skew = <0>;
		qcom,mdss-dsi-h-sync-pulse = <0>;
		qcom,mdss-dsi-v-back-porch = <2>;
		qcom,mdss-dsi-v-front-porch = <2>;
		qcom,mdss-dsi-v-pulse-width = <2>;
		qcom,mdss-dsi-h-left-border = <0>;
		qcom,mdss-dsi-h-right-border = <0>;
		qcom,mdss-dsi-v-top-border = <0>;
		qcom,mdss-dsi-v-bottom-border = <0>;
	        qcom,mdss-dsi-panel-jitter = <0x20 0xa>;
	        qcom,mdss-mdp-transfer-time-us = <7933>;
	        qcom,mdss-dsi-timing-switch-command = [
	        	39 00 00 40 00 00 04 FF 5A A5 00 //24hz
			39 00 00 40 00 00 02 60 00
			39 00 00 40 00 00 02 53 28 //dimming enable
			39 00 00 40 00 00 04 FF 5A A5 2D
			39 00 00 40 00 00 02 83 04
			39 00 00 40 00 00 02 F2 04 //TE
			39 00 00 40 00 00 02 CD 21 //dimming enable
			39 00 00 40 00 00 04 FF 5A A5 24
			39 00 00 40 00 00 03 85 31 80 //dimming enable
			39 00 00 40 00 00 03 86 31 80 //dimming enable
			39 00 00 00 00 00 04 FF 5A A5 00

			39 00 00 40 00 00 04 FF 5A A5 00 //scale disable
			39 00 00 40 00 00 02 4B 00
			39 00 00 40 00 00 04 FF 5A A5 04
			39 00 00 40 00 00 02 CF 00
			39 00 00 40 00 00 02 D0 03
			39 00 00 40 00 00 02 D1 00
			39 00 00 40 00 00 02 D2 04
			39 00 00 40 00 00 02 D4 00
			39 00 00 40 00 00 02 D5 C0
			39 00 00 40 00 00 02 D6 00
			39 00 00 40 00 00 02 E0 04
			39 00 00 40 00 00 02 E1 38
			39 00 00 40 00 00 02 E2 09
			39 00 00 40 00 00 02 E3 48
			39 00 00 40 00 00 12 ED 00 00 04 C0 00 00 04 C0 00 33 00 00 00 00 00 00 00

			39 00 00 40 00 00 04 FF 5A A5 07 //10bit 3.75x
			39 00 00 40 00 00 02 8A 01
			39 00 00 40 00 00 03 8B A0 21
			39 00 00 40 00 00 0B 81 00 00 00 00 00 11 00 00 AB 30
                     	39 00 00 40 00 00 0B FE 80 0C 60 05 A0 00 16 02 D0 02
                     	39 00 00 40 00 00 0B FE D0 02 00 02 68 00 20 02 68 00
                     	39 00 00 40 00 00 0B FE 0A 00 0C 04 93 03 78 18 00 10
                     	39 00 00 40 00 00 0B FE F0 07 10 20 00 06 0F 0F 33 0E
                     	39 00 00 40 00 00 0B FE 1C 2A 38 46 54 62 69 70 77 79
                     	39 00 00 40 00 00 0B FE 7B 7D 7E 01 02 22 00 2A 40 2A
                     	39 00 00 40 00 00 0B FE BE 3A FC 3A FA 3A F8 3B 38 3B
                     	39 00 00 40 00 00 0B FE 78 3B B6 4B F6 4C 34 4C 74 5C
                     	39 00 00 40 00 00 0A FE 74 8C F4 00 00 00 00 00 00
			39 00 00 00 00 00 04 FF 5A A5 00
	        ];
		qcom,mdss-dsi-on-command = [
			39 00 00 40 00 00 04 FF 5A A5 07 //10bit 3.75x
			39 00 00 40 00 00 02 8A 01
			39 00 00 40 00 00 03 8B A0 21
			39 00 00 40 00 00 0B 81 00 00 00 00 00 11 00 00 AB 30
                     	39 00 00 40 00 00 0B FE 80 0C 60 05 A0 00 16 02 D0 02
                     	39 00 00 40 00 00 0B FE D0 02 00 02 68 00 20 02 68 00
                     	39 00 00 40 00 00 0B FE 0A 00 0C 04 93 03 78 18 00 10
                     	39 00 00 40 00 00 0B FE F0 07 10 20 00 06 0F 0F 33 0E
                     	39 00 00 40 00 00 0B FE 1C 2A 38 46 54 62 69 70 77 79
                     	39 00 00 40 00 00 0B FE 7B 7D 7E 01 02 22 00 2A 40 2A
                     	39 00 00 40 00 00 0B FE BE 3A FC 3A FA 3A F8 3B 38 3B
                     	39 00 00 40 00 00 0B FE 78 3B B6 4B F6 4C 34 4C 74 5C
                     	39 00 00 40 00 00 0A FE 74 8C F4 00 00 00 00 00 00

			39 00 00 40 00 00 04 FF 5A A5 07
			39 00 00 40 00 00 02 8A 01
			39 00 00 40 00 00 03 8B A0 21
			39 00 00 40 00 00 04 FF 5A A5 31
			39 00 00 40 00 00 02 D0 80
			39 00 00 40 00 00 04 FF 5A A5 08
			39 00 00 40 00 00 02 C8 62
			39 00 00 40 00 00 04 FF 5A A5 21
			39 00 00 40 00 00 02 A4 38
			39 00 00 40 00 00 04 FF 5A A5 23
			39 00 00 40 00 00 02 85 15
			39 00 00 40 00 00 04 FF 5A A5 00
			39 00 00 40 00 00 02 5E 01
			39 00 00 40 00 00 02 60 00
			39 00 00 40 00 00 02 61 0F
			39 00 00 40 00 00 02 6D 01
			39 00 00 40 00 00 02 35 00
			39 00 00 40 00 00 02 53 20
			39 00 00 40 00 00 03 51 00 00
			39 00 00 40 00 00 04 FF 5A A5 00

			39 00 00 40 00 00 04 FF 5A A5 03 //pcd
			39 00 00 40 00 00 02 BD 91
			39 00 00 40 00 00 04 FF 5A A5 00

			39 00 00 40 00 00 04 FF 5A A5 1E //lhbm
			39 00 00 40 00 00 02 C0 10
			39 00 00 40 00 00 04 C1 70 9C C9
			39 00 00 40 00 00 08 C2 FF FF FF 78 E5 7A F0
			39 00 00 40 00 00 27 C5 44 00 00 44 00 00 44 00 00 44 00 00 44 00 00 42 02 EB 21 23 90 10 08 00 00 00 00 00 00 00 00 00 00 00 00 00 00 00
			39 00 00 40 00 00 27 C7 55 FF FF 55 FF FF 54 10 FF 43 80 80 44 00 00 33 90 6B 32 0C AE 20 50 00 00 00 00 00 00 00 00 00 00 00 00 00 00 00
			39 00 00 40 00 00 09 C8 44 00 00 44 00 00 14 00
			39 00 00 40 00 00 02 C9 00
			39 00 00 40 00 00 1a CA EC EC ED ED EE EF F8 FF FC FC F2 FB FF FF FF FF FF FF FF FF FF FF FF FF FF
			39 00 00 40 00 00 1a CB F0 F0 F0 F1 F1 F2 FA FF FF FE EB F0 F2 FF FE FB FF F9 FF FF FF FF FF FF FF
			39 00 00 40 00 00 1a CC EC EC EC ED EE EF F9 FF FF FE E9 ED EF F1 F4 F5 F4 F4 FF FF FF FF FF FF FF
			39 00 00 40 00 00 04 FF 5A A5 24
			39 00 00 40 00 00 02 80 0E
			39 00 00 40 00 00 02 81 11
			39 00 00 40 00 00 02 84 1F
			39 00 00 40 00 00 04 FF 5A A5 00
			39 00 00 40 00 00 02 95 FF
			39 00 00 40 00 00 02 96 0B
			39 00 00 40 00 00 02 97 40
			39 00 00 40 00 00 02 98 02
			39 00 00 40 00 00 02 99 D0

			39 00 00 40 00 00 04 FF 5A A5 00 //24hz
			39 00 00 40 00 00 02 60 00
			39 00 00 40 00 00 02 53 28 //dimming enable
			39 00 00 40 00 00 04 FF 5A A5 2D
			39 00 00 40 00 00 02 83 04
			39 00 00 40 00 00 02 F2 04 //TE
			39 00 00 40 00 00 02 CD 21 //dimming enable
			39 00 00 40 00 00 04 FF 5A A5 24
			39 00 00 40 00 00 03 85 31 80 //dimming enable
			39 00 00 40 00 00 03 86 31 80 //dimming enable

			39 00 00 40 00 00 04 FF 5A A5 08 //esd check
			39 00 00 40 00 00 02 D2 01
			39 00 00 40 00 00 02 D3 00
			39 00 00 40 00 00 02 D4 00
			39 00 00 40 00 00 09 ED FF FF FF FF FF FF FF FF
			39 00 00 40 00 00 09 EE FF FF FF FF FF FF FF FF
			39 00 00 40 00 00 04 FF 5A A5 00

                     	39 00 00 40 00 00 04 FF 5A A5 2D //1hz transition frame
                     	39 00 00 40 00 00 02 97 03
                     	39 00 00 40 00 00 02 B1 03
                     	39 00 00 40 00 00 03 98 03 00
                     	39 00 00 40 00 00 03 99 05 00
                     	39 00 00 40 00 00 03 9A 0B 00
                     	39 00 00 40 00 00 03 9B 17 00
                     	39 00 00 40 00 00 03 A0 00 00
                     	39 00 00 40 00 00 03 A1 01 02

			39 00 00 40 00 00 04 FF 5A A5 08 //esd check fail fix
			39 00 00 40 00 00 02 F5 00
			39 00 00 40 00 00 02 F6 00
			39 00 00 40 00 00 02 F7 00

			39 00 00 40 00 00 04 FF 5A A5 2D //DBV DIMMING for low refreshrate
                     	39 00 00 40 00 00 02 CE 55

			39 00 00 40 00 00 04 FF 5A A5 00 //scale disable
			39 00 00 40 00 00 02 4B 00
			39 00 00 40 00 00 04 FF 5A A5 04
			39 00 00 40 00 00 02 CF 00
			39 00 00 40 00 00 02 D0 03
			39 00 00 40 00 00 02 D1 00
			39 00 00 40 00 00 02 D2 04
			39 00 00 40 00 00 02 D4 00
			39 00 00 40 00 00 02 D5 C0
			39 00 00 40 00 00 02 D6 00
			39 00 00 40 00 00 02 E0 04
			39 00 00 40 00 00 02 E1 38
			39 00 00 40 00 00 02 E2 09
			39 00 00 40 00 00 02 E3 48
			39 00 00 40 00 00 12 ED 00 00 04 C0 00 00 04 C0 00 33 00 00 00 00 00 00 00
			39 00 00 00 00 00 04 FF 5A A5 00

			05 00 00 00 78 00 01 11 //Delay 120ms
			05 00 00 00 14 00 01 29];	/* display on */
		qcom,mdss-dsi-off-command = [
			39 00 00 40 00 00 04 FF 5A A5 00
			05 00 00 00 14 00 01 28		/* display_off */
			05 00 00 00 BE 00 01 10];	/* enter sleep mode */

		qcom,mdss-dsi-on-command-state = "dsi_lp_mode";
		qcom,mdss-dsi-off-command-state = "dsi_lp_mode";
		qcom,mdss-dsi-timing-switch-command-state = "dsi_lp_mode";
		qcom,compression-mode = "dsc";
		/* Why QCOM doesn't use this, even it used 2 encoder
		 * as for that dsi_sw43404_amoled_cmd, for ex */
		/* qcom,mdss-dsc-encoders = <2>; */
		qcom,mdss-dsc-version = <0x11>;
		qcom,mdss-dsc-slice-height = <22>;
		qcom,mdss-dsc-slice-width = <720>;
		qcom,mdss-dsc-slice-per-pkt = <2>;
		qcom,mdss-dsc-bit-per-component = <10>;
		qcom,mdss-dsc-bit-per-pixel = <8>;
		qcom,mdss-dsc-block-prediction-enable;
		qcom,mdss-dsi-pcd-check-enable-command = [
			39 00 00 00 00 00 04 FF 5A A5 03
			];
		qcom,mdss-dsi-pcd-check-enable-command-state = "dsi_hs_mode";
		qcom,mdss-dsi-pcd-check-disable-command = [
			39 00 00 00 00 00 04 FF 5A A5 00
			];
		qcom,mdss-dsi-pcd-check-disable-command-state = "dsi_hs_mode";
	};
	timing@6{
		qcom,mdss-dsi-cmd-mode;
		qcom,mdss-dsi-panel-framerate = <120>; //actually 10hz
		qcom,mdss-dsi-panel-width = <1440>;
		qcom,mdss-dsi-panel-height = <3168>;
		qcom,mdss-dsi-h-front-porch = <20>;
		qcom,mdss-dsi-h-back-porch = <16>;
		qcom,mdss-dsi-h-pulse-width = <16>;
		qcom,mdss-dsi-h-sync-skew = <0>;
		qcom,mdss-dsi-h-sync-pulse = <0>;
		qcom,mdss-dsi-v-back-porch = <2>;
		qcom,mdss-dsi-v-front-porch = <2>;
		qcom,mdss-dsi-v-pulse-width = <2>;
		qcom,mdss-dsi-h-left-border = <0>;
		qcom,mdss-dsi-h-right-border = <0>;
		qcom,mdss-dsi-v-top-border = <0>;
		qcom,mdss-dsi-v-bottom-border = <0>;
	        qcom,mdss-dsi-panel-jitter = <0x20 0xa>;
	        qcom,mdss-mdp-transfer-time-us = <7933>;
	        qcom,mdss-dsi-timing-switch-command = [
	        	39 00 00 40 00 00 04 FF 5A A5 00 //10hz
			39 00 00 40 00 00 02 60 00
			39 00 00 40 00 00 02 53 20 //dimming disable
			39 00 00 40 00 00 04 FF 5A A5 2D
			39 00 00 40 00 00 02 83 0B
			39 00 00 40 00 00 02 F2 00 //TE
			39 00 00 40 00 00 02 CD 01 //dimming disable
			39 00 00 40 00 00 04 FF 5A A5 24
			39 00 00 40 00 00 03 85 31 00 //dimming disable
			39 00 00 40 00 00 03 86 31 00 //dimming disable
			39 00 00 00 00 00 04 FF 5A A5 00

			39 00 00 40 00 00 04 FF 5A A5 00 //scale disable
			39 00 00 40 00 00 02 4B 00
			39 00 00 40 00 00 04 FF 5A A5 04
			39 00 00 40 00 00 02 CF 00
			39 00 00 40 00 00 02 D0 03
			39 00 00 40 00 00 02 D1 00
			39 00 00 40 00 00 02 D2 04
			39 00 00 40 00 00 02 D4 00
			39 00 00 40 00 00 02 D5 C0
			39 00 00 40 00 00 02 D6 00
			39 00 00 40 00 00 02 E0 04
			39 00 00 40 00 00 02 E1 38
			39 00 00 40 00 00 02 E2 09
			39 00 00 40 00 00 02 E3 48
			39 00 00 40 00 00 12 ED 00 00 04 C0 00 00 04 C0 00 33 00 00 00 00 00 00 00

			39 00 00 40 00 00 04 FF 5A A5 07 //10bit 3.75x
			39 00 00 40 00 00 02 8A 01
			39 00 00 40 00 00 03 8B A0 21
			39 00 00 40 00 00 0B 81 00 00 00 00 00 11 00 00 AB 30
                     	39 00 00 40 00 00 0B FE 80 0C 60 05 A0 00 16 02 D0 02
                     	39 00 00 40 00 00 0B FE D0 02 00 02 68 00 20 02 68 00
                     	39 00 00 40 00 00 0B FE 0A 00 0C 04 93 03 78 18 00 10
                     	39 00 00 40 00 00 0B FE F0 07 10 20 00 06 0F 0F 33 0E
                     	39 00 00 40 00 00 0B FE 1C 2A 38 46 54 62 69 70 77 79
                     	39 00 00 40 00 00 0B FE 7B 7D 7E 01 02 22 00 2A 40 2A
                     	39 00 00 40 00 00 0B FE BE 3A FC 3A FA 3A F8 3B 38 3B
                     	39 00 00 40 00 00 0B FE 78 3B B6 4B F6 4C 34 4C 74 5C
                     	39 00 00 40 00 00 0A FE 74 8C F4 00 00 00 00 00 00
			39 00 00 00 00 00 04 FF 5A A5 00
	        ];
		qcom,mdss-dsi-on-command = [
			39 00 00 40 00 00 04 FF 5A A5 07 //10bit 3.75x
			39 00 00 40 00 00 02 8A 01
			39 00 00 40 00 00 03 8B A0 21
			39 00 00 40 00 00 0B 81 00 00 00 00 00 11 00 00 AB 30
                     	39 00 00 40 00 00 0B FE 80 0C 60 05 A0 00 16 02 D0 02
                     	39 00 00 40 00 00 0B FE D0 02 00 02 68 00 20 02 68 00
                     	39 00 00 40 00 00 0B FE 0A 00 0C 04 93 03 78 18 00 10
                     	39 00 00 40 00 00 0B FE F0 07 10 20 00 06 0F 0F 33 0E
                     	39 00 00 40 00 00 0B FE 1C 2A 38 46 54 62 69 70 77 79
                     	39 00 00 40 00 00 0B FE 7B 7D 7E 01 02 22 00 2A 40 2A
                     	39 00 00 40 00 00 0B FE BE 3A FC 3A FA 3A F8 3B 38 3B
                     	39 00 00 40 00 00 0B FE 78 3B B6 4B F6 4C 34 4C 74 5C
                     	39 00 00 40 00 00 0A FE 74 8C F4 00 00 00 00 00 00

			39 00 00 40 00 00 04 FF 5A A5 07
			39 00 00 40 00 00 02 8A 01
			39 00 00 40 00 00 03 8B A0 21
			39 00 00 40 00 00 04 FF 5A A5 31
			39 00 00 40 00 00 02 D0 80
			39 00 00 40 00 00 04 FF 5A A5 08
			39 00 00 40 00 00 02 C8 62
			39 00 00 40 00 00 04 FF 5A A5 21
			39 00 00 40 00 00 02 A4 38
			39 00 00 40 00 00 04 FF 5A A5 23
			39 00 00 40 00 00 02 85 15
			39 00 00 40 00 00 04 FF 5A A5 00
			39 00 00 40 00 00 02 5E 01
			39 00 00 40 00 00 02 60 00
			39 00 00 40 00 00 02 61 0F
			39 00 00 40 00 00 02 6D 01
			39 00 00 40 00 00 02 35 00
			39 00 00 40 00 00 02 53 20
			39 00 00 40 00 00 03 51 00 00
			39 00 00 40 00 00 04 FF 5A A5 00

			39 00 00 40 00 00 04 FF 5A A5 03 //pcd
			39 00 00 40 00 00 02 BD 91
			39 00 00 40 00 00 04 FF 5A A5 00

			39 00 00 40 00 00 04 FF 5A A5 1E //lhbm
			39 00 00 40 00 00 02 C0 10
			39 00 00 40 00 00 04 C1 70 9C C9
			39 00 00 40 00 00 08 C2 FF FF FF 78 E5 7A F0
			39 00 00 40 00 00 27 C5 44 00 00 44 00 00 44 00 00 44 00 00 44 00 00 42 02 EB 21 23 90 10 08 00 00 00 00 00 00 00 00 00 00 00 00 00 00 00
			39 00 00 40 00 00 27 C7 55 FF FF 55 FF FF 54 10 FF 43 80 80 44 00 00 33 90 6B 32 0C AE 20 50 00 00 00 00 00 00 00 00 00 00 00 00 00 00 00
			39 00 00 40 00 00 09 C8 44 00 00 44 00 00 14 00
			39 00 00 40 00 00 02 C9 00
			39 00 00 40 00 00 1a CA EC EC ED ED EE EF F8 FF FC FC F2 FB FF FF FF FF FF FF FF FF FF FF FF FF FF
			39 00 00 40 00 00 1a CB F0 F0 F0 F1 F1 F2 FA FF FF FE EB F0 F2 FF FE FB FF F9 FF FF FF FF FF FF FF
			39 00 00 40 00 00 1a CC EC EC EC ED EE EF F9 FF FF FE E9 ED EF F1 F4 F5 F4 F4 FF FF FF FF FF FF FF
			39 00 00 40 00 00 04 FF 5A A5 24
			39 00 00 40 00 00 02 80 0E
			39 00 00 40 00 00 02 81 11
			39 00 00 40 00 00 02 84 1F
			39 00 00 40 00 00 04 FF 5A A5 00
			39 00 00 40 00 00 02 95 FF
			39 00 00 40 00 00 02 96 0B
			39 00 00 40 00 00 02 97 40
			39 00 00 40 00 00 02 98 02
			39 00 00 40 00 00 02 99 D0

			39 00 00 40 00 00 04 FF 5A A5 00 //10hz
			39 00 00 40 00 00 02 60 00
			39 00 00 40 00 00 02 53 20 //dimming disable
			39 00 00 40 00 00 04 FF 5A A5 2D
			39 00 00 40 00 00 02 83 0B
			39 00 00 40 00 00 02 F2 00 //TE
			39 00 00 40 00 00 02 CD 01 //dimming disable
			39 00 00 40 00 00 04 FF 5A A5 24
			39 00 00 40 00 00 03 85 31 00 //dimming disable
			39 00 00 40 00 00 03 86 31 00 //dimming disable

			39 00 00 40 00 00 04 FF 5A A5 08 //esd check
			39 00 00 40 00 00 02 D2 01
			39 00 00 40 00 00 02 D3 00
			39 00 00 40 00 00 02 D4 00
			39 00 00 40 00 00 09 ED FF FF FF FF FF FF FF FF
			39 00 00 40 00 00 09 EE FF FF FF FF FF FF FF FF
			39 00 00 40 00 00 04 FF 5A A5 00

                     	39 00 00 40 00 00 04 FF 5A A5 2D //1hz transition frame
                     	39 00 00 40 00 00 02 97 03
                     	39 00 00 40 00 00 02 B1 03
                     	39 00 00 40 00 00 03 98 03 00
                     	39 00 00 40 00 00 03 99 05 00
                     	39 00 00 40 00 00 03 9A 0B 00
                     	39 00 00 40 00 00 03 9B 17 00
                     	39 00 00 40 00 00 03 A0 00 00
                     	39 00 00 40 00 00 03 A1 01 02

			39 00 00 40 00 00 04 FF 5A A5 08 //esd check fail fix
			39 00 00 40 00 00 02 F5 00
			39 00 00 40 00 00 02 F6 00
			39 00 00 40 00 00 02 F7 00

			39 00 00 40 00 00 04 FF 5A A5 2D //DBV DIMMING for low refreshrate
                     	39 00 00 40 00 00 02 CE 55

			39 00 00 40 00 00 04 FF 5A A5 00 //scale disable
			39 00 00 40 00 00 02 4B 00
			39 00 00 40 00 00 04 FF 5A A5 04
			39 00 00 40 00 00 02 CF 00
			39 00 00 40 00 00 02 D0 03
			39 00 00 40 00 00 02 D1 00
			39 00 00 40 00 00 02 D2 04
			39 00 00 40 00 00 02 D4 00
			39 00 00 40 00 00 02 D5 C0
			39 00 00 40 00 00 02 D6 00
			39 00 00 40 00 00 02 E0 04
			39 00 00 40 00 00 02 E1 38
			39 00 00 40 00 00 02 E2 09
			39 00 00 40 00 00 02 E3 48
			39 00 00 40 00 00 12 ED 00 00 04 C0 00 00 04 C0 00 33 00 00 00 00 00 00 00
			39 00 00 00 00 00 04 FF 5A A5 00

			05 00 00 00 78 00 01 11 //Delay 120ms
			05 00 00 00 14 00 01 29];	/* display on */
		qcom,mdss-dsi-off-command = [
			39 00 00 40 00 00 04 FF 5A A5 00
			05 00 00 00 14 00 01 28		/* display_off */
			05 00 00 00 BE 00 01 10];	/* enter sleep mode */

		qcom,mdss-dsi-on-command-state = "dsi_lp_mode";
		qcom,mdss-dsi-off-command-state = "dsi_lp_mode";
		qcom,mdss-dsi-timing-switch-command-state = "dsi_lp_mode";
		qcom,compression-mode = "dsc";
		/* Why QCOM doesn't use this, even it used 2 encoder
		 * as for that dsi_sw43404_amoled_cmd, for ex */
		/* qcom,mdss-dsc-encoders = <2>; */
		qcom,mdss-dsc-version = <0x11>;
		qcom,mdss-dsc-slice-height = <22>;
		qcom,mdss-dsc-slice-width = <720>;
		qcom,mdss-dsc-slice-per-pkt = <2>;
		qcom,mdss-dsc-bit-per-component = <10>;
		qcom,mdss-dsc-bit-per-pixel = <8>;
		qcom,mdss-dsc-block-prediction-enable;
		qcom,mdss-dsi-pcd-check-enable-command = [
			39 00 00 00 00 00 04 FF 5A A5 03
			];
		qcom,mdss-dsi-pcd-check-enable-command-state = "dsi_hs_mode";
		qcom,mdss-dsi-pcd-check-disable-command = [
			39 00 00 00 00 00 04 FF 5A A5 00
			];
		qcom,mdss-dsi-pcd-check-disable-command-state = "dsi_hs_mode";
	};
	timing@7{
		qcom,mdss-dsi-cmd-mode;
		qcom,mdss-dsi-panel-framerate = <120>; //actually 1hz
		qcom,mdss-dsi-panel-width = <1440>;
		qcom,mdss-dsi-panel-height = <3168>;
		qcom,mdss-dsi-h-front-porch = <12>;
		qcom,mdss-dsi-h-back-porch = <16>;
		qcom,mdss-dsi-h-pulse-width = <16>;
		qcom,mdss-dsi-h-sync-skew = <0>;
		qcom,mdss-dsi-h-sync-pulse = <0>;
		qcom,mdss-dsi-v-back-porch = <2>;
		qcom,mdss-dsi-v-front-porch = <2>;
		qcom,mdss-dsi-v-pulse-width = <2>;
		qcom,mdss-dsi-h-left-border = <0>;
		qcom,mdss-dsi-h-right-border = <0>;
		qcom,mdss-dsi-v-top-border = <0>;
		qcom,mdss-dsi-v-bottom-border = <0>;
	        qcom,mdss-dsi-panel-jitter = <0x20 0xa>;
	        qcom,mdss-mdp-transfer-time-us = <7933>;
	        qcom,mdss-dsi-timing-switch-command = [
	        	39 00 00 40 00 00 04 FF 5A A5 00 //1hz
			39 00 00 40 00 00 02 60 00
			39 00 00 40 00 00 02 53 20 //dimming disable
			39 00 00 40 00 00 04 FF 5A A5 2D
			39 00 00 40 00 00 02 83 77
			39 00 00 40 00 00 02 F2 00 //TE
			39 00 00 40 00 00 02 CD 01 //dimming disable
			39 00 00 40 00 00 04 FF 5A A5 24
			39 00 00 40 00 00 03 85 31 00 //dimming disable
			39 00 00 40 00 00 03 86 31 00 //dimming disable
			39 00 00 00 00 00 04 FF 5A A5 00

			39 00 00 40 00 00 04 FF 5A A5 00 //scale disable
			39 00 00 40 00 00 02 4B 00
			39 00 00 40 00 00 04 FF 5A A5 04
			39 00 00 40 00 00 02 CF 00
			39 00 00 40 00 00 02 D0 03
			39 00 00 40 00 00 02 D1 00
			39 00 00 40 00 00 02 D2 04
			39 00 00 40 00 00 02 D4 00
			39 00 00 40 00 00 02 D5 C0
			39 00 00 40 00 00 02 D6 00
			39 00 00 40 00 00 02 E0 04
			39 00 00 40 00 00 02 E1 38
			39 00 00 40 00 00 02 E2 09
			39 00 00 40 00 00 02 E3 48
			39 00 00 40 00 00 12 ED 00 00 04 C0 00 00 04 C0 00 33 00 00 00 00 00 00 00

			39 00 00 40 00 00 04 FF 5A A5 07 //10bit 3.75x
			39 00 00 40 00 00 02 8A 01
			39 00 00 40 00 00 03 8B A0 21
			39 00 00 40 00 00 0B 81 00 00 00 00 00 11 00 00 AB 30
                     	39 00 00 40 00 00 0B FE 80 0C 60 05 A0 00 16 02 D0 02
                     	39 00 00 40 00 00 0B FE D0 02 00 02 68 00 20 02 68 00
                     	39 00 00 40 00 00 0B FE 0A 00 0C 04 93 03 78 18 00 10
                     	39 00 00 40 00 00 0B FE F0 07 10 20 00 06 0F 0F 33 0E
                     	39 00 00 40 00 00 0B FE 1C 2A 38 46 54 62 69 70 77 79
                     	39 00 00 40 00 00 0B FE 7B 7D 7E 01 02 22 00 2A 40 2A
                     	39 00 00 40 00 00 0B FE BE 3A FC 3A FA 3A F8 3B 38 3B
                     	39 00 00 40 00 00 0B FE 78 3B B6 4B F6 4C 34 4C 74 5C
                     	39 00 00 40 00 00 0A FE 74 8C F4 00 00 00 00 00 00
			39 00 00 00 00 00 04 FF 5A A5 00
	        ];
		qcom,mdss-dsi-on-command = [
			39 00 00 40 00 00 04 FF 5A A5 07 //10bit 3.75x
			39 00 00 40 00 00 02 8A 01
			39 00 00 40 00 00 03 8B A0 21
			39 00 00 40 00 00 0B 81 00 00 00 00 00 11 00 00 AB 30
                     	39 00 00 40 00 00 0B FE 80 0C 60 05 A0 00 16 02 D0 02
                     	39 00 00 40 00 00 0B FE D0 02 00 02 68 00 20 02 68 00
                     	39 00 00 40 00 00 0B FE 0A 00 0C 04 93 03 78 18 00 10
                     	39 00 00 40 00 00 0B FE F0 07 10 20 00 06 0F 0F 33 0E
                     	39 00 00 40 00 00 0B FE 1C 2A 38 46 54 62 69 70 77 79
                     	39 00 00 40 00 00 0B FE 7B 7D 7E 01 02 22 00 2A 40 2A
                     	39 00 00 40 00 00 0B FE BE 3A FC 3A FA 3A F8 3B 38 3B
                     	39 00 00 40 00 00 0B FE 78 3B B6 4B F6 4C 34 4C 74 5C
                     	39 00 00 40 00 00 0A FE 74 8C F4 00 00 00 00 00 00

			39 00 00 40 00 00 04 FF 5A A5 07
			39 00 00 40 00 00 02 8A 01
			39 00 00 40 00 00 03 8B A0 21
			39 00 00 40 00 00 04 FF 5A A5 31
			39 00 00 40 00 00 02 D0 80
			39 00 00 40 00 00 04 FF 5A A5 08
			39 00 00 40 00 00 02 C8 62
			39 00 00 40 00 00 04 FF 5A A5 21
			39 00 00 40 00 00 02 A4 38
			39 00 00 40 00 00 04 FF 5A A5 23
			39 00 00 40 00 00 02 85 15
			39 00 00 40 00 00 04 FF 5A A5 00
			39 00 00 40 00 00 02 5E 01
			39 00 00 40 00 00 02 60 00
			39 00 00 40 00 00 02 61 0F
			39 00 00 40 00 00 02 6D 01
			39 00 00 40 00 00 02 35 00
			39 00 00 40 00 00 02 53 20
			39 00 00 40 00 00 03 51 00 00
			39 00 00 40 00 00 04 FF 5A A5 00

			39 00 00 40 00 00 04 FF 5A A5 03 //pcd
			39 00 00 40 00 00 02 BD 91
			39 00 00 40 00 00 04 FF 5A A5 00

			39 00 00 40 00 00 04 FF 5A A5 1E //lhbm
			39 00 00 40 00 00 02 C0 10
			39 00 00 40 00 00 04 C1 70 9C C9
			39 00 00 40 00 00 08 C2 FF FF FF 78 E5 7A F0
			39 00 00 40 00 00 27 C5 44 00 00 44 00 00 44 00 00 44 00 00 44 00 00 42 02 EB 21 23 90 10 08 00 00 00 00 00 00 00 00 00 00 00 00 00 00 00
			39 00 00 40 00 00 27 C7 55 FF FF 55 FF FF 54 10 FF 43 80 80 44 00 00 33 90 6B 32 0C AE 20 50 00 00 00 00 00 00 00 00 00 00 00 00 00 00 00
			39 00 00 40 00 00 09 C8 44 00 00 44 00 00 14 00
			39 00 00 40 00 00 02 C9 00
			39 00 00 40 00 00 1a CA EC EC ED ED EE EF F8 FF FC FC F2 FB FF FF FF FF FF FF FF FF FF FF FF FF FF
			39 00 00 40 00 00 1a CB F0 F0 F0 F1 F1 F2 FA FF FF FE EB F0 F2 FF FE FB FF F9 FF FF FF FF FF FF FF
			39 00 00 40 00 00 1a CC EC EC EC ED EE EF F9 FF FF FE E9 ED EF F1 F4 F5 F4 F4 FF FF FF FF FF FF FF
			39 00 00 40 00 00 04 FF 5A A5 24
			39 00 00 40 00 00 02 80 0E
			39 00 00 40 00 00 02 81 11
			39 00 00 40 00 00 02 84 1F
			39 00 00 40 00 00 04 FF 5A A5 00
			39 00 00 40 00 00 02 95 FF
			39 00 00 40 00 00 02 96 0B
			39 00 00 40 00 00 02 97 40
			39 00 00 40 00 00 02 98 02
			39 00 00 40 00 00 02 99 D0

			39 00 00 40 00 00 04 FF 5A A5 00 //1hz
			39 00 00 40 00 00 02 60 00
			39 00 00 40 00 00 02 53 20 //dimming disable
			39 00 00 40 00 00 04 FF 5A A5 2D
			39 00 00 40 00 00 02 83 77
			39 00 00 40 00 00 02 F2 00 //TE
			39 00 00 40 00 00 02 CD 01 //dimming disable
			39 00 00 40 00 00 04 FF 5A A5 24
			39 00 00 40 00 00 03 85 31 00 //dimming disable
			39 00 00 40 00 00 03 86 31 00 //dimming disable

			39 00 00 40 00 00 04 FF 5A A5 08 //esd check
			39 00 00 40 00 00 02 D2 01
			39 00 00 40 00 00 02 D3 00
			39 00 00 40 00 00 02 D4 00
			39 00 00 40 00 00 09 ED FF FF FF FF FF FF FF FF
			39 00 00 40 00 00 09 EE FF FF FF FF FF FF FF FF
			39 00 00 40 00 00 04 FF 5A A5 00

                     	39 00 00 40 00 00 04 FF 5A A5 2D //1hz transition frame
                     	39 00 00 40 00 00 02 97 03
                     	39 00 00 40 00 00 02 B1 03
                     	39 00 00 40 00 00 03 98 03 00
                     	39 00 00 40 00 00 03 99 05 00
                     	39 00 00 40 00 00 03 9A 0B 00
                     	39 00 00 40 00 00 03 9B 17 00
                     	39 00 00 40 00 00 03 A0 00 00
                     	39 00 00 40 00 00 03 A1 01 02

			39 00 00 40 00 00 04 FF 5A A5 08 //esd check fail fix
			39 00 00 40 00 00 02 F5 00
			39 00 00 40 00 00 02 F6 00
			39 00 00 40 00 00 02 F7 00

			39 00 00 40 00 00 04 FF 5A A5 2D //DBV DIMMING for low refreshrate
                     	39 00 00 40 00 00 02 CE 55

			39 00 00 40 00 00 04 FF 5A A5 00 //scale disable
			39 00 00 40 00 00 02 4B 00
			39 00 00 40 00 00 04 FF 5A A5 04
			39 00 00 40 00 00 02 CF 00
			39 00 00 40 00 00 02 D0 03
			39 00 00 40 00 00 02 D1 00
			39 00 00 40 00 00 02 D2 04
			39 00 00 40 00 00 02 D4 00
			39 00 00 40 00 00 02 D5 C0
			39 00 00 40 00 00 02 D6 00
			39 00 00 40 00 00 02 E0 04
			39 00 00 40 00 00 02 E1 38
			39 00 00 40 00 00 02 E2 09
			39 00 00 40 00 00 02 E3 48
			39 00 00 40 00 00 12 ED 00 00 04 C0 00 00 04 C0 00 33 00 00 00 00 00 00 00
			39 00 00 00 00 00 04 FF 5A A5 00

			05 00 00 00 78 00 01 11 //Delay 120ms
			05 00 00 00 14 00 01 29];	/* display on */
		qcom,mdss-dsi-off-command = [
			39 00 00 40 00 00 04 FF 5A A5 00
			05 00 00 00 14 00 01 28		/* display_off */
			05 00 00 00 BE 00 01 10];	/* enter sleep mode */

		qcom,mdss-dsi-on-command-state = "dsi_lp_mode";
		qcom,mdss-dsi-off-command-state = "dsi_lp_mode";
		qcom,mdss-dsi-timing-switch-command-state = "dsi_lp_mode";
		qcom,compression-mode = "dsc";
		/* Why QCOM doesn't use this, even it used 2 encoder
		 * as for that dsi_sw43404_amoled_cmd, for ex */
		/* qcom,mdss-dsc-encoders = <2>; */
		qcom,mdss-dsc-version = <0x11>;
		qcom,mdss-dsc-slice-height = <22>;
		qcom,mdss-dsc-slice-width = <720>;
		qcom,mdss-dsc-slice-per-pkt = <2>;
		qcom,mdss-dsc-bit-per-component = <10>;
		qcom,mdss-dsc-bit-per-pixel = <8>;
		qcom,mdss-dsc-block-prediction-enable;
		qcom,mdss-dsi-pcd-check-enable-command = [
			39 00 00 00 00 00 04 FF 5A A5 03
			];
		qcom,mdss-dsi-pcd-check-enable-command-state = "dsi_hs_mode";
		qcom,mdss-dsi-pcd-check-disable-command = [
			39 00 00 00 00 00 04 FF 5A A5 00
			];
		qcom,mdss-dsi-pcd-check-disable-command-state = "dsi_hs_mode";
	};
	timing@8{
		qcom,mdss-dsi-cmd-mode;
		qcom,mdss-dsi-panel-framerate = <120>;
		qcom,mdss-dsi-panel-width = <1080>;
		qcom,mdss-dsi-panel-height = <2376>;
		qcom,mdss-dsi-h-front-porch = <16>;
		qcom,mdss-dsi-h-back-porch = <16>;
		qcom,mdss-dsi-h-pulse-width = <16>;
		qcom,mdss-dsi-h-sync-skew = <0>;
		qcom,mdss-dsi-h-sync-pulse = <0>;
		qcom,mdss-dsi-v-back-porch = <2>;
		qcom,mdss-dsi-v-front-porch = <2>;
		qcom,mdss-dsi-v-pulse-width = <2>;
		qcom,mdss-dsi-h-left-border = <0>;
		qcom,mdss-dsi-h-right-border = <0>;
		qcom,mdss-dsi-v-top-border = <0>;
		qcom,mdss-dsi-v-bottom-border = <0>;
	        qcom,mdss-dsi-panel-jitter = <0x20 0xa>;
	        qcom,mdss-dsi-timing-switch-command = [
	        	39 00 00 40 00 00 04 FF 5A A5 00 //120hz
			39 00 00 40 00 00 02 60 00
			39 00 00 40 00 00 02 53 20 //dimming disable
			39 00 00 40 00 00 04 FF 5A A5 2D
			39 00 00 40 00 00 02 83 00
			39 00 00 40 00 00 02 F2 00 //TE
			39 00 00 40 00 00 02 CD 01 //dimming disable
			39 00 00 40 00 00 04 FF 5A A5 24
			39 00 00 40 00 00 03 85 31 00 //dimming disable
			39 00 00 40 00 00 03 86 31 00 //dimming disable
			39 00 00 00 00 00 04 FF 5A A5 00

			39 00 00 40 00 00 04 FF 5A A5 00 //scale enable
			39 00 00 40 00 00 02 4B 01
			39 00 00 40 00 00 04 FF 5A A5 04
			39 00 00 40 00 00 02 CF 00
			39 00 00 40 00 00 02 D0 03
			39 00 00 40 00 00 02 D1 00
			39 00 00 40 00 00 02 D2 04
			39 00 00 40 00 00 02 D4 00
			39 00 00 40 00 00 02 D5 C0
			39 00 00 40 00 00 02 D6 00
			39 00 00 40 00 00 02 E0 04
			39 00 00 40 00 00 02 E1 38
			39 00 00 40 00 00 02 E2 09
			39 00 00 40 00 00 02 E3 48
			39 00 00 40 00 00 12 ED 00 00 04 C0 00 00 04 C0 00 33 00 00 00 00 00 00 00

			39 00 00 40 00 00 04 FF 5A A5 07 //10bit 3.75x
			39 00 00 40 00 00 02 8A 01
			39 00 00 40 00 00 03 8B A0 21
			39 00 00 40 00 00 0B 81 00 00 00 00 00 11 00 00 AB 30
                     	39 00 00 40 00 00 0B FE 80 09 48 04 38 00 12 02 1C 02
                     	39 00 00 40 00 00 0B FE 1C 02 00 02 0E 00 20 01 B6 00
                     	39 00 00 40 00 00 0B FE 07 00 0C 05 A6 05 A7 18 00 10
                     	39 00 00 40 00 00 0B FE F0 07 10 20 00 06 0F 0F 33 0E
                     	39 00 00 40 00 00 0B FE 1C 2A 38 46 54 62 69 70 77 79
                     	39 00 00 40 00 00 0B FE 7B 7D 7E 01 02 22 00 2A 40 2A
                     	39 00 00 40 00 00 0B FE BE 3A FC 3A FA 3A F8 3B 38 3B
                     	39 00 00 40 00 00 0B FE 78 3B B6 4B F6 4C 34 4C 74 5C
                     	39 00 00 40 00 00 0A FE 74 8C F4 00 00 00 00 00 00
			39 00 00 00 00 00 04 FF 5A A5 00
	        ];
		qcom,mdss-dsi-on-command = [
			39 00 00 40 00 00 04 FF 5A A5 07 //10bit 3.75x
			39 00 00 40 00 00 02 8A 01
			39 00 00 40 00 00 03 8B A0 21
			39 00 00 40 00 00 0B 81 00 00 00 00 00 11 00 00 AB 30
                     	39 00 00 40 00 00 0B FE 80 09 48 04 38 00 12 02 1C 02
                     	39 00 00 40 00 00 0B FE 1C 02 00 02 0E 00 20 01 B6 00
                     	39 00 00 40 00 00 0B FE 07 00 0C 05 A6 05 A7 18 00 10
                     	39 00 00 40 00 00 0B FE F0 07 10 20 00 06 0F 0F 33 0E
                     	39 00 00 40 00 00 0B FE 1C 2A 38 46 54 62 69 70 77 79
                     	39 00 00 40 00 00 0B FE 7B 7D 7E 01 02 22 00 2A 40 2A
                     	39 00 00 40 00 00 0B FE BE 3A FC 3A FA 3A F8 3B 38 3B
                     	39 00 00 40 00 00 0B FE 78 3B B6 4B F6 4C 34 4C 74 5C
                     	39 00 00 40 00 00 0A FE 74 8C F4 00 00 00 00 00 00

			39 00 00 40 00 00 04 FF 5A A5 07
			39 00 00 40 00 00 02 8A 01
			39 00 00 40 00 00 03 8B A0 21
			39 00 00 40 00 00 04 FF 5A A5 31
			39 00 00 40 00 00 02 D0 80
			39 00 00 40 00 00 04 FF 5A A5 08
			39 00 00 40 00 00 02 C8 62
			39 00 00 40 00 00 04 FF 5A A5 21
			39 00 00 40 00 00 02 A4 38
			39 00 00 40 00 00 04 FF 5A A5 23
			39 00 00 40 00 00 02 85 15
			39 00 00 40 00 00 04 FF 5A A5 00
			39 00 00 40 00 00 02 5E 01
			39 00 00 40 00 00 02 60 00
			39 00 00 40 00 00 02 61 0F
			39 00 00 40 00 00 02 6D 01
			39 00 00 40 00 00 02 35 00
			39 00 00 40 00 00 02 53 20
			39 00 00 40 00 00 03 51 00 00
			39 00 00 40 00 00 04 FF 5A A5 00

			39 00 00 40 00 00 04 FF 5A A5 03 //pcd
			39 00 00 40 00 00 02 BD 91
			39 00 00 40 00 00 04 FF 5A A5 00

			39 00 00 40 00 00 04 FF 5A A5 1E //lhbm
			39 00 00 40 00 00 02 C0 10
			39 00 00 40 00 00 04 C1 70 9C C9
			39 00 00 40 00 00 08 C2 FF FF FF 78 E5 7A F0
			39 00 00 40 00 00 27 C5 44 00 00 44 00 00 44 00 00 44 00 00 44 00 00 42 02 EB 21 23 90 10 08 00 00 00 00 00 00 00 00 00 00 00 00 00 00 00
			39 00 00 40 00 00 27 C7 55 FF FF 55 FF FF 54 10 FF 43 80 80 44 00 00 33 90 6B 32 0C AE 20 50 00 00 00 00 00 00 00 00 00 00 00 00 00 00 00
			39 00 00 40 00 00 09 C8 44 00 00 44 00 00 14 00
			39 00 00 40 00 00 02 C9 00
			39 00 00 40 00 00 1a CA EC EC ED ED EE EF F8 FF FC FC F2 FB FF FF FF FF FF FF FF FF FF FF FF FF FF
			39 00 00 40 00 00 1a CB F0 F0 F0 F1 F1 F2 FA FF FF FE EB F0 F2 FF FE FB FF F9 FF FF FF FF FF FF FF
			39 00 00 40 00 00 1a CC EC EC EC ED EE EF F9 FF FF FE E9 ED EF F1 F4 F5 F4 F4 FF FF FF FF FF FF FF
			39 00 00 40 00 00 04 FF 5A A5 24
			39 00 00 40 00 00 02 80 0E
			39 00 00 40 00 00 02 81 11
			39 00 00 40 00 00 02 84 1F
			39 00 00 40 00 00 04 FF 5A A5 00
			39 00 00 40 00 00 02 95 FF
			39 00 00 40 00 00 02 96 0B
			39 00 00 40 00 00 02 97 40
			39 00 00 40 00 00 02 98 02
			39 00 00 40 00 00 02 99 D0

			39 00 00 40 00 00 04 FF 5A A5 00 //120hz
			39 00 00 40 00 00 02 60 00
			39 00 00 40 00 00 02 53 20 //dimming disable
			39 00 00 40 00 00 04 FF 5A A5 2D
			39 00 00 40 00 00 02 83 00
			39 00 00 40 00 00 02 F2 00 //TE
			39 00 00 40 00 00 02 CD 01 //dimming disable
			39 00 00 40 00 00 04 FF 5A A5 24
			39 00 00 40 00 00 03 85 31 00 //dimming disable
			39 00 00 40 00 00 03 86 31 00 //dimming disable

			39 00 00 40 00 00 04 FF 5A A5 08 //esd check
			39 00 00 40 00 00 02 D2 01
			39 00 00 40 00 00 02 D3 00
			39 00 00 40 00 00 02 D4 00
			39 00 00 40 00 00 09 ED FF FF FF FF FF FF FF FF
			39 00 00 40 00 00 09 EE FF FF FF FF FF FF FF FF
			39 00 00 40 00 00 04 FF 5A A5 00

			39 00 00 40 00 00 04 FF 5A A5 2D //1hz transition frame
                     	39 00 00 40 00 00 02 97 03
                     	39 00 00 40 00 00 02 B1 03
                     	39 00 00 40 00 00 03 98 03 00
                     	39 00 00 40 00 00 03 99 05 00
                     	39 00 00 40 00 00 03 9A 0B 00
                     	39 00 00 40 00 00 03 9B 17 00
                     	39 00 00 40 00 00 03 A0 00 00
                     	39 00 00 40 00 00 03 A1 01 02

			39 00 00 40 00 00 04 FF 5A A5 08 //esd check fail fix
			39 00 00 40 00 00 02 F5 00
			39 00 00 40 00 00 02 F6 00
			39 00 00 40 00 00 02 F7 00

			39 00 00 40 00 00 04 FF 5A A5 2D //DBV DIMMING for low refreshrate
                     	39 00 00 40 00 00 02 CE 55

			39 00 00 40 00 00 04 FF 5A A5 00 //scale enable
			39 00 00 40 00 00 02 4B 01
			39 00 00 40 00 00 04 FF 5A A5 04
			39 00 00 40 00 00 02 CF 00
			39 00 00 40 00 00 02 D0 03
			39 00 00 40 00 00 02 D1 00
			39 00 00 40 00 00 02 D2 04
			39 00 00 40 00 00 02 D4 00
			39 00 00 40 00 00 02 D5 C0
			39 00 00 40 00 00 02 D6 00
			39 00 00 40 00 00 02 E0 04
			39 00 00 40 00 00 02 E1 38
			39 00 00 40 00 00 02 E2 09
			39 00 00 40 00 00 02 E3 48
			39 00 00 40 00 00 12 ED 00 00 04 C0 00 00 04 C0 00 33 00 00 00 00 00 00 00
			39 00 00 00 00 00 04 FF 5A A5 00

			05 00 00 00 78 00 01 11 //Delay 120ms
			05 00 00 00 14 00 01 29];	/* display on */
		qcom,mdss-dsi-off-command = [
			39 00 00 40 00 00 04 FF 5A A5 00
			05 00 00 00 14 00 01 28		/* display_off */
			05 00 00 00 78 00 01 10];	/* enter sleep mode */

		qcom,mdss-dsi-on-command-state = "dsi_lp_mode";
		qcom,mdss-dsi-off-command-state = "dsi_lp_mode";
		qcom,mdss-dsi-timing-switch-command-state = "dsi_lp_mode";
		qcom,compression-mode = "dsc";
		/* Why QCOM doesn't use this, even it used 2 encoder
		 * as for that dsi_sw43404_amoled_cmd, for ex */
		/* qcom,mdss-dsc-encoders = <2>; */
		qcom,mdss-dsc-version = <0x11>;
		qcom,mdss-dsc-slice-height = <18>;
		qcom,mdss-dsc-slice-width = <540>;
		qcom,mdss-dsc-slice-per-pkt = <2>;
		qcom,mdss-dsc-bit-per-component = <10>;
		qcom,mdss-dsc-bit-per-pixel = <8>;
		qcom,mdss-dsc-block-prediction-enable;
		qcom,mdss-dsi-pcd-check-enable-command = [
			39 00 00 00 00 00 04 FF 5A A5 03
			];
		qcom,mdss-dsi-pcd-check-enable-command-state = "dsi_hs_mode";
		qcom,mdss-dsi-pcd-check-disable-command = [
			39 00 00 00 00 00 04 FF 5A A5 00
			];
		qcom,mdss-dsi-pcd-check-disable-command-state = "dsi_hs_mode";
	};
	timing@9{
		qcom,mdss-dsi-cmd-mode;
		qcom,mdss-dsi-panel-framerate = <144>;
		qcom,mdss-dsi-panel-width = <1080>;
		qcom,mdss-dsi-panel-height = <2376>;
		qcom,mdss-dsi-h-front-porch = <16>;
		qcom,mdss-dsi-h-back-porch = <16>;
		qcom,mdss-dsi-h-pulse-width = <16>;
		qcom,mdss-dsi-h-sync-skew = <0>;
		qcom,mdss-dsi-h-sync-pulse = <0>;
		qcom,mdss-dsi-v-back-porch = <2>;
		qcom,mdss-dsi-v-front-porch = <2>;
		qcom,mdss-dsi-v-pulse-width = <2>;
		qcom,mdss-dsi-h-left-border = <0>;
		qcom,mdss-dsi-h-right-border = <0>;
		qcom,mdss-dsi-v-top-border = <0>;
		qcom,mdss-dsi-v-bottom-border = <0>;
	        qcom,mdss-dsi-panel-jitter = <0x20 0xa>;
	        qcom,mdss-dsi-timing-switch-command = [
	        	39 00 00 40 00 00 04 FF 5A A5 00 //144hz
			39 00 00 40 00 00 02 60 01
			39 00 00 40 00 00 02 53 20 //dimming disable
			39 00 00 40 00 00 04 FF 5A A5 2D
			39 00 00 40 00 00 02 84 00
			39 00 00 40 00 00 02 CD 01 //dimming disable
			39 00 00 40 00 00 04 FF 5A A5 24
			39 00 00 40 00 00 03 85 31 00 //dimming disable
			39 00 00 40 00 00 03 86 31 00 //dimming disable
			39 00 00 00 00 00 04 FF 5A A5 00

			39 00 00 40 00 00 04 FF 5A A5 00 //scale enable
			39 00 00 40 00 00 02 4B 01
			39 00 00 40 00 00 04 FF 5A A5 04
			39 00 00 40 00 00 02 CF 00
			39 00 00 40 00 00 02 D0 03
			39 00 00 40 00 00 02 D1 00
			39 00 00 40 00 00 02 D2 04
			39 00 00 40 00 00 02 D4 00
			39 00 00 40 00 00 02 D5 C0
			39 00 00 40 00 00 02 D6 00
			39 00 00 40 00 00 02 E0 04
			39 00 00 40 00 00 02 E1 38
			39 00 00 40 00 00 02 E2 09
			39 00 00 40 00 00 02 E3 48
			39 00 00 40 00 00 12 ED 00 00 04 C0 00 00 04 C0 00 33 00 00 00 00 00 00 00

			39 00 00 40 00 00 04 FF 5A A5 07 //10bit 3.75x
			39 00 00 40 00 00 02 8A 01
			39 00 00 40 00 00 03 8B A0 21
			39 00 00 40 00 00 0B 81 00 00 00 00 00 11 00 00 AB 30
                     	39 00 00 40 00 00 0B FE 80 09 48 04 38 00 12 02 1C 02
                     	39 00 00 40 00 00 0B FE 1C 02 00 02 0E 00 20 01 B6 00
                     	39 00 00 40 00 00 0B FE 07 00 0C 05 A6 05 A7 18 00 10
                     	39 00 00 40 00 00 0B FE F0 07 10 20 00 06 0F 0F 33 0E
                     	39 00 00 40 00 00 0B FE 1C 2A 38 46 54 62 69 70 77 79
                     	39 00 00 40 00 00 0B FE 7B 7D 7E 01 02 22 00 2A 40 2A
                     	39 00 00 40 00 00 0B FE BE 3A FC 3A FA 3A F8 3B 38 3B
                     	39 00 00 40 00 00 0B FE 78 3B B6 4B F6 4C 34 4C 74 5C
                     	39 00 00 40 00 00 0A FE 74 8C F4 00 00 00 00 00 00
			39 00 00 00 00 00 04 FF 5A A5 00
	        ];
		qcom,mdss-dsi-on-command = [
			39 00 00 40 00 00 04 FF 5A A5 07 //10bit 3.75x
			39 00 00 40 00 00 02 8A 01
			39 00 00 40 00 00 03 8B A0 21
			39 00 00 40 00 00 0B 81 00 00 00 00 00 11 00 00 AB 30
                     	39 00 00 40 00 00 0B FE 80 09 48 04 38 00 12 02 1C 02
                     	39 00 00 40 00 00 0B FE 1C 02 00 02 0E 00 20 01 B6 00
                     	39 00 00 40 00 00 0B FE 07 00 0C 05 A6 05 A7 18 00 10
                     	39 00 00 40 00 00 0B FE F0 07 10 20 00 06 0F 0F 33 0E
                     	39 00 00 40 00 00 0B FE 1C 2A 38 46 54 62 69 70 77 79
                     	39 00 00 40 00 00 0B FE 7B 7D 7E 01 02 22 00 2A 40 2A
                     	39 00 00 40 00 00 0B FE BE 3A FC 3A FA 3A F8 3B 38 3B
                     	39 00 00 40 00 00 0B FE 78 3B B6 4B F6 4C 34 4C 74 5C
                     	39 00 00 40 00 00 0A FE 74 8C F4 00 00 00 00 00 00

			39 00 00 40 00 00 04 FF 5A A5 07
			39 00 00 40 00 00 02 8A 01
			39 00 00 40 00 00 03 8B A0 21
			39 00 00 40 00 00 04 FF 5A A5 31
			39 00 00 40 00 00 02 D0 80
			39 00 00 40 00 00 04 FF 5A A5 08
			39 00 00 40 00 00 02 C8 62
			39 00 00 40 00 00 04 FF 5A A5 21
			39 00 00 40 00 00 02 A4 38
			39 00 00 40 00 00 04 FF 5A A5 23
			39 00 00 40 00 00 02 85 15
			39 00 00 40 00 00 04 FF 5A A5 00
			39 00 00 40 00 00 02 5E 01
			39 00 00 40 00 00 02 60 00
			39 00 00 40 00 00 02 61 0F
			39 00 00 40 00 00 02 6D 01
			39 00 00 40 00 00 02 35 00
			39 00 00 40 00 00 02 53 20
			39 00 00 40 00 00 03 51 00 00
			39 00 00 40 00 00 04 FF 5A A5 00

			39 00 00 40 00 00 04 FF 5A A5 03 //pcd
			39 00 00 40 00 00 02 BD 91
			39 00 00 40 00 00 04 FF 5A A5 00

			39 00 00 40 00 00 04 FF 5A A5 1E //lhbm
			39 00 00 40 00 00 02 C0 10
			39 00 00 40 00 00 04 C1 70 9C C9
			39 00 00 40 00 00 08 C2 FF FF FF 78 E5 7A F0
			39 00 00 40 00 00 27 C5 44 00 00 44 00 00 44 00 00 44 00 00 44 00 00 42 02 EB 21 23 90 10 08 00 00 00 00 00 00 00 00 00 00 00 00 00 00 00
			39 00 00 40 00 00 27 C7 55 FF FF 55 FF FF 54 10 FF 43 80 80 44 00 00 33 90 6B 32 0C AE 20 50 00 00 00 00 00 00 00 00 00 00 00 00 00 00 00
			39 00 00 40 00 00 09 C8 44 00 00 44 00 00 14 00
			39 00 00 40 00 00 02 C9 00
			39 00 00 40 00 00 1a CA EC EC ED ED EE EF F8 FF FC FC F2 FB FF FF FF FF FF FF FF FF FF FF FF FF FF
			39 00 00 40 00 00 1a CB F0 F0 F0 F1 F1 F2 FA FF FF FE EB F0 F2 FF FE FB FF F9 FF FF FF FF FF FF FF
			39 00 00 40 00 00 1a CC EC EC EC ED EE EF F9 FF FF FE E9 ED EF F1 F4 F5 F4 F4 FF FF FF FF FF FF FF
			39 00 00 40 00 00 04 FF 5A A5 24
			39 00 00 40 00 00 02 80 0E
			39 00 00 40 00 00 02 81 11
			39 00 00 40 00 00 02 84 1F
			39 00 00 40 00 00 04 FF 5A A5 00
			39 00 00 40 00 00 02 95 FF
			39 00 00 40 00 00 02 96 0B
			39 00 00 40 00 00 02 97 40
			39 00 00 40 00 00 02 98 02
			39 00 00 40 00 00 02 99 D0

			39 00 00 40 00 00 04 FF 5A A5 00 //144hz
			39 00 00 40 00 00 02 60 01
			39 00 00 40 00 00 02 53 20 //dimming disable
			39 00 00 40 00 00 04 FF 5A A5 2D
			39 00 00 40 00 00 02 84 00
			39 00 00 40 00 00 02 CD 01 //dimming disable
			39 00 00 40 00 00 04 FF 5A A5 24
			39 00 00 40 00 00 03 85 31 00 //dimming disable
			39 00 00 40 00 00 03 86 31 00 //dimming disable

			39 00 00 40 00 00 04 FF 5A A5 08 //esd check
			39 00 00 40 00 00 02 D2 01
			39 00 00 40 00 00 02 D3 00
			39 00 00 40 00 00 02 D4 00
			39 00 00 40 00 00 09 ED FF FF FF FF FF FF FF FF
			39 00 00 40 00 00 09 EE FF FF FF FF FF FF FF FF
			39 00 00 40 00 00 04 FF 5A A5 00

			39 00 00 40 00 00 04 FF 5A A5 2D //1hz transition frame
                     	39 00 00 40 00 00 02 97 03
                     	39 00 00 40 00 00 02 B1 03
                     	39 00 00 40 00 00 03 98 03 00
                     	39 00 00 40 00 00 03 99 05 00
                     	39 00 00 40 00 00 03 9A 0B 00
                     	39 00 00 40 00 00 03 9B 17 00
                     	39 00 00 40 00 00 03 A0 00 00
                     	39 00 00 40 00 00 03 A1 01 02

			39 00 00 40 00 00 04 FF 5A A5 08 //esd check fail fix
			39 00 00 40 00 00 02 F5 00
			39 00 00 40 00 00 02 F6 00
			39 00 00 40 00 00 02 F7 00

			39 00 00 40 00 00 04 FF 5A A5 2D //DBV DIMMING for low refreshrate
                     	39 00 00 40 00 00 02 CE 55

			39 00 00 40 00 00 04 FF 5A A5 00 //scale enable
			39 00 00 40 00 00 02 4B 01
			39 00 00 40 00 00 04 FF 5A A5 04
			39 00 00 40 00 00 02 CF 00
			39 00 00 40 00 00 02 D0 03
			39 00 00 40 00 00 02 D1 00
			39 00 00 40 00 00 02 D2 04
			39 00 00 40 00 00 02 D4 00
			39 00 00 40 00 00 02 D5 C0
			39 00 00 40 00 00 02 D6 00
			39 00 00 40 00 00 02 E0 04
			39 00 00 40 00 00 02 E1 38
			39 00 00 40 00 00 02 E2 09
			39 00 00 40 00 00 02 E3 48
			39 00 00 40 00 00 12 ED 00 00 04 C0 00 00 04 C0 00 33 00 00 00 00 00 00 00
			39 00 00 00 00 00 04 FF 5A A5 00

			05 00 00 00 78 00 01 11 //Delay 120ms
			05 00 00 00 14 00 01 29];	/* display on */
		qcom,mdss-dsi-off-command = [
			39 00 00 40 00 00 04 FF 5A A5 00
			05 00 00 00 14 00 01 28		/* display_off */
			05 00 00 00 78 00 01 10];	/* enter sleep mode */

		qcom,mdss-dsi-on-command-state = "dsi_lp_mode";
		qcom,mdss-dsi-off-command-state = "dsi_lp_mode";
		qcom,mdss-dsi-timing-switch-command-state = "dsi_lp_mode";
		qcom,compression-mode = "dsc";
		/* Why QCOM doesn't use this, even it used 2 encoder
		 * as for that dsi_sw43404_amoled_cmd, for ex */
		/* qcom,mdss-dsc-encoders = <2>; */
		qcom,mdss-dsc-version = <0x11>;
		qcom,mdss-dsc-slice-height = <18>;
		qcom,mdss-dsc-slice-width = <540>;
		qcom,mdss-dsc-slice-per-pkt = <2>;
		qcom,mdss-dsc-bit-per-component = <10>;
		qcom,mdss-dsc-bit-per-pixel = <8>;
		qcom,mdss-dsc-block-prediction-enable;
		qcom,mdss-dsi-pcd-check-enable-command = [
			39 00 00 00 00 00 04 FF 5A A5 03
			];
		qcom,mdss-dsi-pcd-check-enable-command-state = "dsi_hs_mode";
		qcom,mdss-dsi-pcd-check-disable-command = [
			39 00 00 00 00 00 04 FF 5A A5 00
			];
		qcom,mdss-dsi-pcd-check-disable-command-state = "dsi_hs_mode";
	};
	timing@10{
		qcom,mdss-dsi-cmd-mode;
		qcom,mdss-dsi-panel-framerate = <90>;
		qcom,mdss-dsi-panel-width = <1080>;
		qcom,mdss-dsi-panel-height = <2376>;
		qcom,mdss-dsi-h-front-porch = <16>;
		qcom,mdss-dsi-h-back-porch = <16>;
		qcom,mdss-dsi-h-pulse-width = <16>;
		qcom,mdss-dsi-h-sync-skew = <0>;
		qcom,mdss-dsi-h-sync-pulse = <0>;
		qcom,mdss-dsi-v-back-porch = <2>;
		qcom,mdss-dsi-v-front-porch = <2>;
		qcom,mdss-dsi-v-pulse-width = <2>;
		qcom,mdss-dsi-h-left-border = <0>;
		qcom,mdss-dsi-h-right-border = <0>;
		qcom,mdss-dsi-v-top-border = <0>;
		qcom,mdss-dsi-v-bottom-border = <0>;
	        qcom,mdss-dsi-panel-jitter = <0x20 0xa>;
	        qcom,mdss-mdp-transfer-time-us = <7933>;
	        qcom,mdss-dsi-timing-switch-command = [
	        	39 00 00 40 00 00 04 FF 5A A5 00 //90hz
			39 00 00 40 00 00 02 60 02
			39 00 00 40 00 00 02 53 20 //dimming disable
			39 00 00 40 00 00 04 FF 5A A5 2D
			39 00 00 40 00 00 02 85 00
			39 00 00 40 00 00 02 CD 01 //dimming disable
			39 00 00 40 00 00 04 FF 5A A5 24
			39 00 00 40 00 00 03 85 31 00 //dimming disable
			39 00 00 40 00 00 03 86 31 00 //dimming disable
			39 00 00 00 00 00 04 FF 5A A5 00

			39 00 00 40 00 00 04 FF 5A A5 00 //scale enable
			39 00 00 40 00 00 02 4B 01
			39 00 00 40 00 00 04 FF 5A A5 04
			39 00 00 40 00 00 02 CF 00
			39 00 00 40 00 00 02 D0 03
			39 00 00 40 00 00 02 D1 00
			39 00 00 40 00 00 02 D2 04
			39 00 00 40 00 00 02 D4 00
			39 00 00 40 00 00 02 D5 C0
			39 00 00 40 00 00 02 D6 00
			39 00 00 40 00 00 02 E0 04
			39 00 00 40 00 00 02 E1 38
			39 00 00 40 00 00 02 E2 09
			39 00 00 40 00 00 02 E3 48
			39 00 00 40 00 00 12 ED 00 00 04 C0 00 00 04 C0 00 33 00 00 00 00 00 00 00

			39 00 00 40 00 00 04 FF 5A A5 07 //10bit 3.75x
			39 00 00 40 00 00 02 8A 01
			39 00 00 40 00 00 03 8B A0 21
			39 00 00 40 00 00 0B 81 00 00 00 00 00 11 00 00 AB 30
                     	39 00 00 40 00 00 0B FE 80 09 48 04 38 00 12 02 1C 02
                     	39 00 00 40 00 00 0B FE 1C 02 00 02 0E 00 20 01 B6 00
                     	39 00 00 40 00 00 0B FE 07 00 0C 05 A6 05 A7 18 00 10
                     	39 00 00 40 00 00 0B FE F0 07 10 20 00 06 0F 0F 33 0E
                     	39 00 00 40 00 00 0B FE 1C 2A 38 46 54 62 69 70 77 79
                     	39 00 00 40 00 00 0B FE 7B 7D 7E 01 02 22 00 2A 40 2A
                     	39 00 00 40 00 00 0B FE BE 3A FC 3A FA 3A F8 3B 38 3B
                     	39 00 00 40 00 00 0B FE 78 3B B6 4B F6 4C 34 4C 74 5C
                     	39 00 00 40 00 00 0A FE 74 8C F4 00 00 00 00 00 00
			39 00 00 00 00 00 04 FF 5A A5 00
	        ];
		qcom,mdss-dsi-on-command = [
			39 00 00 40 00 00 04 FF 5A A5 07 //10bit 3.75x
			39 00 00 40 00 00 02 8A 01
			39 00 00 40 00 00 03 8B A0 21
			39 00 00 40 00 00 0B 81 00 00 00 00 00 11 00 00 AB 30
                     	39 00 00 40 00 00 0B FE 80 09 48 04 38 00 12 02 1C 02
                     	39 00 00 40 00 00 0B FE 1C 02 00 02 0E 00 20 01 B6 00
                     	39 00 00 40 00 00 0B FE 07 00 0C 05 A6 05 A7 18 00 10
                     	39 00 00 40 00 00 0B FE F0 07 10 20 00 06 0F 0F 33 0E
                     	39 00 00 40 00 00 0B FE 1C 2A 38 46 54 62 69 70 77 79
                     	39 00 00 40 00 00 0B FE 7B 7D 7E 01 02 22 00 2A 40 2A
                     	39 00 00 40 00 00 0B FE BE 3A FC 3A FA 3A F8 3B 38 3B
                     	39 00 00 40 00 00 0B FE 78 3B B6 4B F6 4C 34 4C 74 5C
                     	39 00 00 40 00 00 0A FE 74 8C F4 00 00 00 00 00 00

			39 00 00 40 00 00 04 FF 5A A5 07
			39 00 00 40 00 00 02 8A 01
			39 00 00 40 00 00 03 8B A0 21
			39 00 00 40 00 00 04 FF 5A A5 31
			39 00 00 40 00 00 02 D0 80
			39 00 00 40 00 00 04 FF 5A A5 08
			39 00 00 40 00 00 02 C8 62
			39 00 00 40 00 00 04 FF 5A A5 21
			39 00 00 40 00 00 02 A4 38
			39 00 00 40 00 00 04 FF 5A A5 23
			39 00 00 40 00 00 02 85 15
			39 00 00 40 00 00 04 FF 5A A5 00
			39 00 00 40 00 00 02 5E 01
			39 00 00 40 00 00 02 60 00
			39 00 00 40 00 00 02 61 0F
			39 00 00 40 00 00 02 6D 01
			39 00 00 40 00 00 02 35 00
			39 00 00 40 00 00 02 53 20
			39 00 00 40 00 00 03 51 00 00
			39 00 00 40 00 00 04 FF 5A A5 00

			39 00 00 40 00 00 04 FF 5A A5 03 //pcd
			39 00 00 40 00 00 02 BD 91
			39 00 00 40 00 00 04 FF 5A A5 00

			39 00 00 40 00 00 04 FF 5A A5 1E //lhbm
			39 00 00 40 00 00 02 C0 10
			39 00 00 40 00 00 04 C1 70 9C C9
			39 00 00 40 00 00 08 C2 FF FF FF 78 E5 7A F0
			39 00 00 40 00 00 27 C5 44 00 00 44 00 00 44 00 00 44 00 00 44 00 00 42 02 EB 21 23 90 10 08 00 00 00 00 00 00 00 00 00 00 00 00 00 00 00
			39 00 00 40 00 00 27 C7 55 FF FF 55 FF FF 54 10 FF 43 80 80 44 00 00 33 90 6B 32 0C AE 20 50 00 00 00 00 00 00 00 00 00 00 00 00 00 00 00
			39 00 00 40 00 00 09 C8 44 00 00 44 00 00 14 00
			39 00 00 40 00 00 02 C9 00
			39 00 00 40 00 00 1a CA EC EC ED ED EE EF F8 FF FC FC F2 FB FF FF FF FF FF FF FF FF FF FF FF FF FF
			39 00 00 40 00 00 1a CB F0 F0 F0 F1 F1 F2 FA FF FF FE EB F0 F2 FF FE FB FF F9 FF FF FF FF FF FF FF
			39 00 00 40 00 00 1a CC EC EC EC ED EE EF F9 FF FF FE E9 ED EF F1 F4 F5 F4 F4 FF FF FF FF FF FF FF
			39 00 00 40 00 00 04 FF 5A A5 24
			39 00 00 40 00 00 02 80 0E
			39 00 00 40 00 00 02 81 11
			39 00 00 40 00 00 02 84 1F
			39 00 00 40 00 00 04 FF 5A A5 00
			39 00 00 40 00 00 02 95 FF
			39 00 00 40 00 00 02 96 0B
			39 00 00 40 00 00 02 97 40
			39 00 00 40 00 00 02 98 02
			39 00 00 40 00 00 02 99 D0

			39 00 00 40 00 00 04 FF 5A A5 00 //90hz
			39 00 00 40 00 00 02 60 02
			39 00 00 40 00 00 02 53 20 //dimming disable
			39 00 00 40 00 00 04 FF 5A A5 2D
			39 00 00 40 00 00 02 85 00
			39 00 00 40 00 00 02 CD 01 //dimming disable
			39 00 00 40 00 00 04 FF 5A A5 24
			39 00 00 40 00 00 03 85 31 00 //dimming disable
			39 00 00 40 00 00 03 86 31 00 //dimming disable

			39 00 00 40 00 00 04 FF 5A A5 08 //esd check
			39 00 00 40 00 00 02 D2 01
			39 00 00 40 00 00 02 D3 00
			39 00 00 40 00 00 02 D4 00
			39 00 00 40 00 00 09 ED FF FF FF FF FF FF FF FF
			39 00 00 40 00 00 09 EE FF FF FF FF FF FF FF FF
			39 00 00 40 00 00 04 FF 5A A5 00

			39 00 00 40 00 00 04 FF 5A A5 2D //1hz transition frame
                     	39 00 00 40 00 00 02 97 03
                     	39 00 00 40 00 00 02 B1 03
                     	39 00 00 40 00 00 03 98 03 00
                     	39 00 00 40 00 00 03 99 05 00
                     	39 00 00 40 00 00 03 9A 0B 00
                     	39 00 00 40 00 00 03 9B 17 00
                     	39 00 00 40 00 00 03 A0 00 00
                     	39 00 00 40 00 00 03 A1 01 02

			39 00 00 40 00 00 04 FF 5A A5 08 //esd check fail fix
			39 00 00 40 00 00 02 F5 00
			39 00 00 40 00 00 02 F6 00
			39 00 00 40 00 00 02 F7 00

			39 00 00 40 00 00 04 FF 5A A5 2D //DBV DIMMING for low refreshrate
                     	39 00 00 40 00 00 02 CE 55

			39 00 00 40 00 00 04 FF 5A A5 00 //scale enable
			39 00 00 40 00 00 02 4B 01
			39 00 00 40 00 00 04 FF 5A A5 04
			39 00 00 40 00 00 02 CF 00
			39 00 00 40 00 00 02 D0 03
			39 00 00 40 00 00 02 D1 00
			39 00 00 40 00 00 02 D2 04
			39 00 00 40 00 00 02 D4 00
			39 00 00 40 00 00 02 D5 C0
			39 00 00 40 00 00 02 D6 00
			39 00 00 40 00 00 02 E0 04
			39 00 00 40 00 00 02 E1 38
			39 00 00 40 00 00 02 E2 09
			39 00 00 40 00 00 02 E3 48
			39 00 00 40 00 00 12 ED 00 00 04 C0 00 00 04 C0 00 33 00 00 00 00 00 00 00
			39 00 00 00 00 00 04 FF 5A A5 00

			05 00 00 00 78 00 01 11 //Delay 120ms
			05 00 00 00 14 00 01 29];	/* display on */
		qcom,mdss-dsi-off-command = [
			39 00 00 40 00 00 04 FF 5A A5 00
			05 00 00 00 14 00 01 28		/* display_off */
			05 00 00 00 78 00 01 10];	/* enter sleep mode */

		qcom,mdss-dsi-on-command-state = "dsi_lp_mode";
		qcom,mdss-dsi-off-command-state = "dsi_lp_mode";
		qcom,mdss-dsi-timing-switch-command-state = "dsi_lp_mode";
		qcom,compression-mode = "dsc";
		/* Why QCOM doesn't use this, even it used 2 encoder
		 * as for that dsi_sw43404_amoled_cmd, for ex */
		/* qcom,mdss-dsc-encoders = <2>; */
		qcom,mdss-dsc-version = <0x11>;
		qcom,mdss-dsc-slice-height = <18>;
		qcom,mdss-dsc-slice-width = <540>;
		qcom,mdss-dsc-slice-per-pkt = <2>;
		qcom,mdss-dsc-bit-per-component = <10>;
		qcom,mdss-dsc-bit-per-pixel = <8>;
		qcom,mdss-dsc-block-prediction-enable;
		qcom,mdss-dsi-pcd-check-enable-command = [
			39 00 00 00 00 00 04 FF 5A A5 03
			];
		qcom,mdss-dsi-pcd-check-enable-command-state = "dsi_hs_mode";
		qcom,mdss-dsi-pcd-check-disable-command = [
			39 00 00 00 00 00 04 FF 5A A5 00
			];
		qcom,mdss-dsi-pcd-check-disable-command-state = "dsi_hs_mode";
	};
	timing@11{
		qcom,mdss-dsi-cmd-mode;
		qcom,mdss-dsi-panel-framerate = <60>;
		qcom,mdss-dsi-panel-width = <1080>;
		qcom,mdss-dsi-panel-height = <2376>;
		qcom,mdss-dsi-h-front-porch = <16>;
		qcom,mdss-dsi-h-back-porch = <16>;
		qcom,mdss-dsi-h-pulse-width = <16>;
		qcom,mdss-dsi-h-sync-skew = <0>;
		qcom,mdss-dsi-h-sync-pulse = <0>;
		qcom,mdss-dsi-v-back-porch = <2>;
		qcom,mdss-dsi-v-front-porch = <2>;
		qcom,mdss-dsi-v-pulse-width = <2>;
		qcom,mdss-dsi-h-left-border = <0>;
		qcom,mdss-dsi-h-right-border = <0>;
		qcom,mdss-dsi-v-top-border = <0>;
		qcom,mdss-dsi-v-bottom-border = <0>;
	        qcom,mdss-dsi-panel-jitter = <0x20 0xa>;
	        qcom,mdss-mdp-transfer-time-us = <7933>;
	        qcom,mdss-dsi-timing-switch-command = [
	        	39 00 00 40 00 00 04 FF 5A A5 00 //60hz
			39 00 00 40 00 00 02 60 00
			39 00 00 40 00 00 02 53 20 //dimming disable
			39 00 00 40 00 00 04 FF 5A A5 2D
			39 00 00 40 00 00 02 83 01
			39 00 00 40 00 00 02 F2 01 //TE
			39 00 00 40 00 00 02 CD 01 //dimming disable
			39 00 00 40 00 00 04 FF 5A A5 24
			39 00 00 40 00 00 03 85 31 00 //dimming disable
			39 00 00 40 00 00 03 86 31 00 //dimming disable
			39 00 00 00 00 00 04 FF 5A A5 00

			39 00 00 40 00 00 04 FF 5A A5 00 //scale enable
			39 00 00 40 00 00 02 4B 01
			39 00 00 40 00 00 04 FF 5A A5 04
			39 00 00 40 00 00 02 CF 00
			39 00 00 40 00 00 02 D0 03
			39 00 00 40 00 00 02 D1 00
			39 00 00 40 00 00 02 D2 04
			39 00 00 40 00 00 02 D4 00
			39 00 00 40 00 00 02 D5 C0
			39 00 00 40 00 00 02 D6 00
			39 00 00 40 00 00 02 E0 04
			39 00 00 40 00 00 02 E1 38
			39 00 00 40 00 00 02 E2 09
			39 00 00 40 00 00 02 E3 48
			39 00 00 40 00 00 12 ED 00 00 04 C0 00 00 04 C0 00 33 00 00 00 00 00 00 00

			39 00 00 40 00 00 04 FF 5A A5 07 //10bit 3.75x
			39 00 00 40 00 00 02 8A 01
			39 00 00 40 00 00 03 8B A0 21
			39 00 00 40 00 00 0B 81 00 00 00 00 00 11 00 00 AB 30
                     	39 00 00 40 00 00 0B FE 80 09 48 04 38 00 12 02 1C 02
                     	39 00 00 40 00 00 0B FE 1C 02 00 02 0E 00 20 01 B6 00
                     	39 00 00 40 00 00 0B FE 07 00 0C 05 A6 05 A7 18 00 10
                     	39 00 00 40 00 00 0B FE F0 07 10 20 00 06 0F 0F 33 0E
                     	39 00 00 40 00 00 0B FE 1C 2A 38 46 54 62 69 70 77 79
                     	39 00 00 40 00 00 0B FE 7B 7D 7E 01 02 22 00 2A 40 2A
                     	39 00 00 40 00 00 0B FE BE 3A FC 3A FA 3A F8 3B 38 3B
                     	39 00 00 40 00 00 0B FE 78 3B B6 4B F6 4C 34 4C 74 5C
                     	39 00 00 40 00 00 0A FE 74 8C F4 00 00 00 00 00 00
			39 00 00 00 00 00 04 FF 5A A5 00
	        ];
		qcom,mdss-dsi-on-command = [
			39 00 00 40 00 00 04 FF 5A A5 07 //10bit 3.75x
			39 00 00 40 00 00 02 8A 01
			39 00 00 40 00 00 03 8B A0 21
			39 00 00 40 00 00 0B 81 00 00 00 00 00 11 00 00 AB 30
                     	39 00 00 40 00 00 0B FE 80 09 48 04 38 00 12 02 1C 02
                     	39 00 00 40 00 00 0B FE 1C 02 00 02 0E 00 20 01 B6 00
                     	39 00 00 40 00 00 0B FE 07 00 0C 05 A6 05 A7 18 00 10
                     	39 00 00 40 00 00 0B FE F0 07 10 20 00 06 0F 0F 33 0E
                     	39 00 00 40 00 00 0B FE 1C 2A 38 46 54 62 69 70 77 79
                     	39 00 00 40 00 00 0B FE 7B 7D 7E 01 02 22 00 2A 40 2A
                     	39 00 00 40 00 00 0B FE BE 3A FC 3A FA 3A F8 3B 38 3B
                     	39 00 00 40 00 00 0B FE 78 3B B6 4B F6 4C 34 4C 74 5C
                     	39 00 00 40 00 00 0A FE 74 8C F4 00 00 00 00 00 00

			39 00 00 40 00 00 04 FF 5A A5 07
			39 00 00 40 00 00 02 8A 01
			39 00 00 40 00 00 03 8B A0 21
			39 00 00 40 00 00 04 FF 5A A5 31
			39 00 00 40 00 00 02 D0 80
			39 00 00 40 00 00 04 FF 5A A5 08
			39 00 00 40 00 00 02 C8 62
			39 00 00 40 00 00 04 FF 5A A5 21
			39 00 00 40 00 00 02 A4 38
			39 00 00 40 00 00 04 FF 5A A5 23
			39 00 00 40 00 00 02 85 15
			39 00 00 40 00 00 04 FF 5A A5 00
			39 00 00 40 00 00 02 5E 01
			39 00 00 40 00 00 02 60 00
			39 00 00 40 00 00 02 61 0F
			39 00 00 40 00 00 02 6D 01
			39 00 00 40 00 00 02 35 00
			39 00 00 40 00 00 02 53 20
			39 00 00 40 00 00 03 51 00 00
			39 00 00 40 00 00 04 FF 5A A5 00

			39 00 00 40 00 00 04 FF 5A A5 03 //pcd
			39 00 00 40 00 00 02 BD 91
			39 00 00 40 00 00 04 FF 5A A5 00

			39 00 00 40 00 00 04 FF 5A A5 1E //lhbm
			39 00 00 40 00 00 02 C0 10
			39 00 00 40 00 00 04 C1 70 9C C9
			39 00 00 40 00 00 08 C2 FF FF FF 78 E5 7A F0
			39 00 00 40 00 00 27 C5 44 00 00 44 00 00 44 00 00 44 00 00 44 00 00 42 02 EB 21 23 90 10 08 00 00 00 00 00 00 00 00 00 00 00 00 00 00 00
			39 00 00 40 00 00 27 C7 55 FF FF 55 FF FF 54 10 FF 43 80 80 44 00 00 33 90 6B 32 0C AE 20 50 00 00 00 00 00 00 00 00 00 00 00 00 00 00 00
			39 00 00 40 00 00 09 C8 44 00 00 44 00 00 14 00
			39 00 00 40 00 00 02 C9 00
			39 00 00 40 00 00 1a CA EC EC ED ED EE EF F8 FF FC FC F2 FB FF FF FF FF FF FF FF FF FF FF FF FF FF
			39 00 00 40 00 00 1a CB F0 F0 F0 F1 F1 F2 FA FF FF FE EB F0 F2 FF FE FB FF F9 FF FF FF FF FF FF FF
			39 00 00 40 00 00 1a CC EC EC EC ED EE EF F9 FF FF FE E9 ED EF F1 F4 F5 F4 F4 FF FF FF FF FF FF FF
			39 00 00 40 00 00 04 FF 5A A5 24
			39 00 00 40 00 00 02 80 0E
			39 00 00 40 00 00 02 81 11
			39 00 00 40 00 00 02 84 1F
			39 00 00 40 00 00 04 FF 5A A5 00
			39 00 00 40 00 00 02 95 FF
			39 00 00 40 00 00 02 96 0B
			39 00 00 40 00 00 02 97 40
			39 00 00 40 00 00 02 98 02
			39 00 00 40 00 00 02 99 D0

			39 00 00 40 00 00 04 FF 5A A5 00 //60hz
			39 00 00 40 00 00 02 60 00
			39 00 00 40 00 00 02 53 20 //dimming disable
			39 00 00 40 00 00 04 FF 5A A5 2D
			39 00 00 40 00 00 02 83 01
			39 00 00 40 00 00 02 F2 01 //TE
			39 00 00 40 00 00 02 CD 01 //dimming disable
			39 00 00 40 00 00 04 FF 5A A5 24
			39 00 00 40 00 00 03 85 31 00 //dimming disable
			39 00 00 40 00 00 03 86 31 00 //dimming disable

			39 00 00 40 00 00 04 FF 5A A5 08 //esd check
			39 00 00 40 00 00 02 D2 01
			39 00 00 40 00 00 02 D3 00
			39 00 00 40 00 00 02 D4 00
			39 00 00 40 00 00 09 ED FF FF FF FF FF FF FF FF
			39 00 00 40 00 00 09 EE FF FF FF FF FF FF FF FF
			39 00 00 40 00 00 04 FF 5A A5 00

			39 00 00 40 00 00 04 FF 5A A5 2D //1hz transition frame
                     	39 00 00 40 00 00 02 97 03
                     	39 00 00 40 00 00 02 B1 03
                     	39 00 00 40 00 00 03 98 03 00
                     	39 00 00 40 00 00 03 99 05 00
                     	39 00 00 40 00 00 03 9A 0B 00
                     	39 00 00 40 00 00 03 9B 17 00
                     	39 00 00 40 00 00 03 A0 00 00
                     	39 00 00 40 00 00 03 A1 01 02

			39 00 00 40 00 00 04 FF 5A A5 08 //esd check fail fix
			39 00 00 40 00 00 02 F5 00
			39 00 00 40 00 00 02 F6 00
			39 00 00 40 00 00 02 F7 00

			39 00 00 40 00 00 04 FF 5A A5 2D //DBV DIMMING for low refreshrate
                     	39 00 00 40 00 00 02 CE 55

			39 00 00 40 00 00 04 FF 5A A5 00 //scale enable
			39 00 00 40 00 00 02 4B 01
			39 00 00 40 00 00 04 FF 5A A5 04
			39 00 00 40 00 00 02 CF 00
			39 00 00 40 00 00 02 D0 03
			39 00 00 40 00 00 02 D1 00
			39 00 00 40 00 00 02 D2 04
			39 00 00 40 00 00 02 D4 00
			39 00 00 40 00 00 02 D5 C0
			39 00 00 40 00 00 02 D6 00
			39 00 00 40 00 00 02 E0 04
			39 00 00 40 00 00 02 E1 38
			39 00 00 40 00 00 02 E2 09
			39 00 00 40 00 00 02 E3 48
			39 00 00 40 00 00 12 ED 00 00 04 C0 00 00 04 C0 00 33 00 00 00 00 00 00 00
			39 00 00 00 00 00 04 FF 5A A5 00

			05 00 00 00 78 00 01 11 //Delay 120ms
			05 00 00 00 14 00 01 29];	/* display on */
		qcom,mdss-dsi-off-command = [
			39 00 00 40 00 00 04 FF 5A A5 00
			05 00 00 00 14 00 01 28		/* display_off */
			05 00 00 00 78 00 01 10];	/* enter sleep mode */

		qcom,mdss-dsi-on-command-state = "dsi_lp_mode";
		qcom,mdss-dsi-off-command-state = "dsi_lp_mode";
		qcom,mdss-dsi-timing-switch-command-state = "dsi_lp_mode";
		qcom,compression-mode = "dsc";
		/* Why QCOM doesn't use this, even it used 2 encoder
		 * as for that dsi_sw43404_amoled_cmd, for ex */
		/* qcom,mdss-dsc-encoders = <2>; */
		qcom,mdss-dsc-version = <0x11>;
		qcom,mdss-dsc-slice-height = <18>;
		qcom,mdss-dsc-slice-width = <540>;
		qcom,mdss-dsc-slice-per-pkt = <2>;
		qcom,mdss-dsc-bit-per-component = <10>;
		qcom,mdss-dsc-bit-per-pixel = <8>;
		qcom,mdss-dsc-block-prediction-enable;
		qcom,mdss-dsi-pcd-check-enable-command = [
			39 00 00 00 00 00 04 FF 5A A5 03
			];
		qcom,mdss-dsi-pcd-check-enable-command-state = "dsi_hs_mode";
		qcom,mdss-dsi-pcd-check-disable-command = [
			39 00 00 00 00 00 04 FF 5A A5 00
			];
		qcom,mdss-dsi-pcd-check-disable-command-state = "dsi_hs_mode";
	};
	timing@12{
		qcom,mdss-dsi-cmd-mode;
		qcom,mdss-dsi-panel-framerate = <30>;
		qcom,mdss-dsi-panel-width = <1080>;
		qcom,mdss-dsi-panel-height = <2376>;
		qcom,mdss-dsi-h-front-porch = <16>;
		qcom,mdss-dsi-h-back-porch = <16>;
		qcom,mdss-dsi-h-pulse-width = <16>;
		qcom,mdss-dsi-h-sync-skew = <0>;
		qcom,mdss-dsi-h-sync-pulse = <0>;
		qcom,mdss-dsi-v-back-porch = <2>;
		qcom,mdss-dsi-v-front-porch = <2>;
		qcom,mdss-dsi-v-pulse-width = <2>;
		qcom,mdss-dsi-h-left-border = <0>;
		qcom,mdss-dsi-h-right-border = <0>;
		qcom,mdss-dsi-v-top-border = <0>;
		qcom,mdss-dsi-v-bottom-border = <0>;
	        qcom,mdss-dsi-panel-jitter = <0x20 0xa>;
	        qcom,mdss-mdp-transfer-time-us = <7933>;
	        qcom,mdss-dsi-timing-switch-command = [
	        	39 00 00 40 00 00 04 FF 5A A5 00 //30hz
			39 00 00 40 00 00 02 60 00
			39 00 00 40 00 00 02 53 28 //dimming enable
			39 00 00 40 00 00 04 FF 5A A5 2D
			39 00 00 40 00 00 02 83 03
			39 00 00 40 00 00 02 F2 03 //TE
			39 00 00 40 00 00 02 CD 21 //dimming enable
			39 00 00 40 00 00 04 FF 5A A5 24
			39 00 00 40 00 00 03 85 31 80 //dimming enable
			39 00 00 40 00 00 03 86 31 80 //dimming enable
			39 00 00 00 00 00 04 FF 5A A5 00

			39 00 00 40 00 00 04 FF 5A A5 00 //scale enable
			39 00 00 40 00 00 02 4B 01
			39 00 00 40 00 00 04 FF 5A A5 04
			39 00 00 40 00 00 02 CF 00
			39 00 00 40 00 00 02 D0 03
			39 00 00 40 00 00 02 D1 00
			39 00 00 40 00 00 02 D2 04
			39 00 00 40 00 00 02 D4 00
			39 00 00 40 00 00 02 D5 C0
			39 00 00 40 00 00 02 D6 00
			39 00 00 40 00 00 02 E0 04
			39 00 00 40 00 00 02 E1 38
			39 00 00 40 00 00 02 E2 09
			39 00 00 40 00 00 02 E3 48
			39 00 00 40 00 00 12 ED 00 00 04 C0 00 00 04 C0 00 33 00 00 00 00 00 00 00

			39 00 00 40 00 00 04 FF 5A A5 07 //10bit 3.75x
			39 00 00 40 00 00 02 8A 01
			39 00 00 40 00 00 03 8B A0 21
			39 00 00 40 00 00 0B 81 00 00 00 00 00 11 00 00 AB 30
                     	39 00 00 40 00 00 0B FE 80 09 48 04 38 00 12 02 1C 02
                     	39 00 00 40 00 00 0B FE 1C 02 00 02 0E 00 20 01 B6 00
                     	39 00 00 40 00 00 0B FE 07 00 0C 05 A6 05 A7 18 00 10
                     	39 00 00 40 00 00 0B FE F0 07 10 20 00 06 0F 0F 33 0E
                     	39 00 00 40 00 00 0B FE 1C 2A 38 46 54 62 69 70 77 79
                     	39 00 00 40 00 00 0B FE 7B 7D 7E 01 02 22 00 2A 40 2A
                     	39 00 00 40 00 00 0B FE BE 3A FC 3A FA 3A F8 3B 38 3B
                     	39 00 00 40 00 00 0B FE 78 3B B6 4B F6 4C 34 4C 74 5C
                     	39 00 00 40 00 00 0A FE 74 8C F4 00 00 00 00 00 00
			39 00 00 00 00 00 04 FF 5A A5 00
	        ];
		qcom,mdss-dsi-on-command = [
			39 00 00 40 00 00 04 FF 5A A5 07 //10bit 3.75x
			39 00 00 40 00 00 02 8A 01
			39 00 00 40 00 00 03 8B A0 21
			39 00 00 40 00 00 0B 81 00 00 00 00 00 11 00 00 AB 30
                     	39 00 00 40 00 00 0B FE 80 09 48 04 38 00 12 02 1C 02
                     	39 00 00 40 00 00 0B FE 1C 02 00 02 0E 00 20 01 B6 00
                     	39 00 00 40 00 00 0B FE 07 00 0C 05 A6 05 A7 18 00 10
                     	39 00 00 40 00 00 0B FE F0 07 10 20 00 06 0F 0F 33 0E
                     	39 00 00 40 00 00 0B FE 1C 2A 38 46 54 62 69 70 77 79
                     	39 00 00 40 00 00 0B FE 7B 7D 7E 01 02 22 00 2A 40 2A
                     	39 00 00 40 00 00 0B FE BE 3A FC 3A FA 3A F8 3B 38 3B
                     	39 00 00 40 00 00 0B FE 78 3B B6 4B F6 4C 34 4C 74 5C
                     	39 00 00 40 00 00 0A FE 74 8C F4 00 00 00 00 00 00

			39 00 00 40 00 00 04 FF 5A A5 07
			39 00 00 40 00 00 02 8A 01
			39 00 00 40 00 00 03 8B A0 21
			39 00 00 40 00 00 04 FF 5A A5 31
			39 00 00 40 00 00 02 D0 80
			39 00 00 40 00 00 04 FF 5A A5 08
			39 00 00 40 00 00 02 C8 62
			39 00 00 40 00 00 04 FF 5A A5 21
			39 00 00 40 00 00 02 A4 38
			39 00 00 40 00 00 04 FF 5A A5 23
			39 00 00 40 00 00 02 85 15
			39 00 00 40 00 00 04 FF 5A A5 00
			39 00 00 40 00 00 02 5E 01
			39 00 00 40 00 00 02 60 00
			39 00 00 40 00 00 02 61 0F
			39 00 00 40 00 00 02 6D 01
			39 00 00 40 00 00 02 35 00
			39 00 00 40 00 00 02 53 20
			39 00 00 40 00 00 03 51 00 00
			39 00 00 40 00 00 04 FF 5A A5 00

			39 00 00 40 00 00 04 FF 5A A5 03 //pcd
			39 00 00 40 00 00 02 BD 91
			39 00 00 40 00 00 04 FF 5A A5 00

			39 00 00 40 00 00 04 FF 5A A5 1E //lhbm
			39 00 00 40 00 00 02 C0 10
			39 00 00 40 00 00 04 C1 70 9C C9
			39 00 00 40 00 00 08 C2 FF FF FF 78 E5 7A F0
			39 00 00 40 00 00 27 C5 44 00 00 44 00 00 44 00 00 44 00 00 44 00 00 42 02 EB 21 23 90 10 08 00 00 00 00 00 00 00 00 00 00 00 00 00 00 00
			39 00 00 40 00 00 27 C7 55 FF FF 55 FF FF 54 10 FF 43 80 80 44 00 00 33 90 6B 32 0C AE 20 50 00 00 00 00 00 00 00 00 00 00 00 00 00 00 00
			39 00 00 40 00 00 09 C8 44 00 00 44 00 00 14 00
			39 00 00 40 00 00 02 C9 00
			39 00 00 40 00 00 1a CA EC EC ED ED EE EF F8 FF FC FC F2 FB FF FF FF FF FF FF FF FF FF FF FF FF FF
			39 00 00 40 00 00 1a CB F0 F0 F0 F1 F1 F2 FA FF FF FE EB F0 F2 FF FE FB FF F9 FF FF FF FF FF FF FF
			39 00 00 40 00 00 1a CC EC EC EC ED EE EF F9 FF FF FE E9 ED EF F1 F4 F5 F4 F4 FF FF FF FF FF FF FF
			39 00 00 40 00 00 04 FF 5A A5 24
			39 00 00 40 00 00 02 80 0E
			39 00 00 40 00 00 02 81 11
			39 00 00 40 00 00 02 84 1F
			39 00 00 40 00 00 04 FF 5A A5 00
			39 00 00 40 00 00 02 95 FF
			39 00 00 40 00 00 02 96 0B
			39 00 00 40 00 00 02 97 40
			39 00 00 40 00 00 02 98 02
			39 00 00 40 00 00 02 99 D0

			39 00 00 40 00 00 04 FF 5A A5 00 //30hz
			39 00 00 40 00 00 02 60 00
			39 00 00 40 00 00 02 53 28 //dimming enable
			39 00 00 40 00 00 04 FF 5A A5 2D
			39 00 00 40 00 00 02 83 03
			39 00 00 40 00 00 02 F2 03 //TE
			39 00 00 40 00 00 02 CD 21 //dimming enable
			39 00 00 40 00 00 04 FF 5A A5 24
			39 00 00 40 00 00 03 85 31 80 //dimming enable
			39 00 00 40 00 00 03 86 31 80 //dimming enable

			39 00 00 40 00 00 04 FF 5A A5 08 //esd check
			39 00 00 40 00 00 02 D2 01
			39 00 00 40 00 00 02 D3 00
			39 00 00 40 00 00 02 D4 00
			39 00 00 40 00 00 09 ED FF FF FF FF FF FF FF FF
			39 00 00 40 00 00 09 EE FF FF FF FF FF FF FF FF
			39 00 00 40 00 00 04 FF 5A A5 00

			39 00 00 40 00 00 04 FF 5A A5 2D //1hz transition frame
                     	39 00 00 40 00 00 02 97 03
                     	39 00 00 40 00 00 02 B1 03
                     	39 00 00 40 00 00 03 98 03 00
                     	39 00 00 40 00 00 03 99 05 00
                     	39 00 00 40 00 00 03 9A 0B 00
                     	39 00 00 40 00 00 03 9B 17 00
                     	39 00 00 40 00 00 03 A0 00 00
                     	39 00 00 40 00 00 03 A1 01 02

			39 00 00 40 00 00 04 FF 5A A5 08 //esd check fail fix
			39 00 00 40 00 00 02 F5 00
			39 00 00 40 00 00 02 F6 00
			39 00 00 40 00 00 02 F7 00

			39 00 00 40 00 00 04 FF 5A A5 2D //DBV DIMMING for low refreshrate
                     	39 00 00 40 00 00 02 CE 55

			39 00 00 40 00 00 04 FF 5A A5 00 //scale enable
			39 00 00 40 00 00 02 4B 01
			39 00 00 40 00 00 04 FF 5A A5 04
			39 00 00 40 00 00 02 CF 00
			39 00 00 40 00 00 02 D0 03
			39 00 00 40 00 00 02 D1 00
			39 00 00 40 00 00 02 D2 04
			39 00 00 40 00 00 02 D4 00
			39 00 00 40 00 00 02 D5 C0
			39 00 00 40 00 00 02 D6 00
			39 00 00 40 00 00 02 E0 04
			39 00 00 40 00 00 02 E1 38
			39 00 00 40 00 00 02 E2 09
			39 00 00 40 00 00 02 E3 48
			39 00 00 40 00 00 12 ED 00 00 04 C0 00 00 04 C0 00 33 00 00 00 00 00 00 00
			39 00 00 00 00 00 04 FF 5A A5 00

			05 00 00 00 78 00 01 11 //Delay 120ms
			05 00 00 00 14 00 01 29];	/* display on */
		qcom,mdss-dsi-off-command = [
			39 00 00 40 00 00 04 FF 5A A5 00
			05 00 00 00 14 00 01 28		/* display_off */
			05 00 00 00 78 00 01 10];	/* enter sleep mode */

		qcom,mdss-dsi-on-command-state = "dsi_lp_mode";
		qcom,mdss-dsi-off-command-state = "dsi_lp_mode";
		qcom,mdss-dsi-timing-switch-command-state = "dsi_lp_mode";
		qcom,compression-mode = "dsc";
		/* Why QCOM doesn't use this, even it used 2 encoder
		 * as for that dsi_sw43404_amoled_cmd, for ex */
		/* qcom,mdss-dsc-encoders = <2>; */
		qcom,mdss-dsc-version = <0x11>;
		qcom,mdss-dsc-slice-height = <18>;
		qcom,mdss-dsc-slice-width = <540>;
		qcom,mdss-dsc-slice-per-pkt = <2>;
		qcom,mdss-dsc-bit-per-component = <10>;
		qcom,mdss-dsc-bit-per-pixel = <8>;
		qcom,mdss-dsc-block-prediction-enable;
		qcom,mdss-dsi-pcd-check-enable-command = [
			39 00 00 00 00 00 04 FF 5A A5 03
			];
		qcom,mdss-dsi-pcd-check-enable-command-state = "dsi_hs_mode";
		qcom,mdss-dsi-pcd-check-disable-command = [
			39 00 00 00 00 00 04 FF 5A A5 00
			];
		qcom,mdss-dsi-pcd-check-disable-command-state = "dsi_hs_mode";
	};
	timing@13{
		qcom,mdss-dsi-cmd-mode;
		qcom,mdss-dsi-panel-framerate = <24>;
		qcom,mdss-dsi-panel-width = <1080>;
		qcom,mdss-dsi-panel-height = <2376>;
		qcom,mdss-dsi-h-front-porch = <16>;
		qcom,mdss-dsi-h-back-porch = <16>;
		qcom,mdss-dsi-h-pulse-width = <16>;
		qcom,mdss-dsi-h-sync-skew = <0>;
		qcom,mdss-dsi-h-sync-pulse = <0>;
		qcom,mdss-dsi-v-back-porch = <2>;
		qcom,mdss-dsi-v-front-porch = <2>;
		qcom,mdss-dsi-v-pulse-width = <2>;
		qcom,mdss-dsi-h-left-border = <0>;
		qcom,mdss-dsi-h-right-border = <0>;
		qcom,mdss-dsi-v-top-border = <0>;
		qcom,mdss-dsi-v-bottom-border = <0>;
	        qcom,mdss-dsi-panel-jitter = <0x20 0xa>;
	        qcom,mdss-mdp-transfer-time-us = <7933>;
	        qcom,mdss-dsi-timing-switch-command = [
	        	39 00 00 40 00 00 04 FF 5A A5 00 //24hz
			39 00 00 40 00 00 02 60 00
			39 00 00 40 00 00 02 53 28 //dimming enable
			39 00 00 40 00 00 04 FF 5A A5 2D
			39 00 00 40 00 00 02 83 04
			39 00 00 40 00 00 02 F2 04 //TE
			39 00 00 40 00 00 02 CD 21 //dimming enable
			39 00 00 40 00 00 04 FF 5A A5 24
			39 00 00 40 00 00 03 85 31 80 //dimming enable
			39 00 00 40 00 00 03 86 31 80 //dimming enable
			39 00 00 00 00 00 04 FF 5A A5 00

			39 00 00 40 00 00 04 FF 5A A5 00 //scale enable
			39 00 00 40 00 00 02 4B 01
			39 00 00 40 00 00 04 FF 5A A5 04
			39 00 00 40 00 00 02 CF 00
			39 00 00 40 00 00 02 D0 03
			39 00 00 40 00 00 02 D1 00
			39 00 00 40 00 00 02 D2 04
			39 00 00 40 00 00 02 D4 00
			39 00 00 40 00 00 02 D5 C0
			39 00 00 40 00 00 02 D6 00
			39 00 00 40 00 00 02 E0 04
			39 00 00 40 00 00 02 E1 38
			39 00 00 40 00 00 02 E2 09
			39 00 00 40 00 00 02 E3 48
			39 00 00 40 00 00 12 ED 00 00 04 C0 00 00 04 C0 00 33 00 00 00 00 00 00 00

			39 00 00 40 00 00 04 FF 5A A5 07 //10bit 3.75x
			39 00 00 40 00 00 02 8A 01
			39 00 00 40 00 00 03 8B A0 21
			39 00 00 40 00 00 0B 81 00 00 00 00 00 11 00 00 AB 30
                     	39 00 00 40 00 00 0B FE 80 09 48 04 38 00 12 02 1C 02
                     	39 00 00 40 00 00 0B FE 1C 02 00 02 0E 00 20 01 B6 00
                     	39 00 00 40 00 00 0B FE 07 00 0C 05 A6 05 A7 18 00 10
                     	39 00 00 40 00 00 0B FE F0 07 10 20 00 06 0F 0F 33 0E
                     	39 00 00 40 00 00 0B FE 1C 2A 38 46 54 62 69 70 77 79
                     	39 00 00 40 00 00 0B FE 7B 7D 7E 01 02 22 00 2A 40 2A
                     	39 00 00 40 00 00 0B FE BE 3A FC 3A FA 3A F8 3B 38 3B
                     	39 00 00 40 00 00 0B FE 78 3B B6 4B F6 4C 34 4C 74 5C
                     	39 00 00 40 00 00 0A FE 74 8C F4 00 00 00 00 00 00
			39 00 00 00 00 00 04 FF 5A A5 00
	        ];
		qcom,mdss-dsi-on-command = [
			39 00 00 40 00 00 04 FF 5A A5 07 //10bit 3.75x
			39 00 00 40 00 00 02 8A 01
			39 00 00 40 00 00 03 8B A0 21
			39 00 00 40 00 00 0B 81 00 00 00 00 00 11 00 00 AB 30
                     	39 00 00 40 00 00 0B FE 80 09 48 04 38 00 12 02 1C 02
                     	39 00 00 40 00 00 0B FE 1C 02 00 02 0E 00 20 01 B6 00
                     	39 00 00 40 00 00 0B FE 07 00 0C 05 A6 05 A7 18 00 10
                     	39 00 00 40 00 00 0B FE F0 07 10 20 00 06 0F 0F 33 0E
                     	39 00 00 40 00 00 0B FE 1C 2A 38 46 54 62 69 70 77 79
                     	39 00 00 40 00 00 0B FE 7B 7D 7E 01 02 22 00 2A 40 2A
                     	39 00 00 40 00 00 0B FE BE 3A FC 3A FA 3A F8 3B 38 3B
                     	39 00 00 40 00 00 0B FE 78 3B B6 4B F6 4C 34 4C 74 5C
                     	39 00 00 40 00 00 0A FE 74 8C F4 00 00 00 00 00 00

			39 00 00 40 00 00 04 FF 5A A5 07
			39 00 00 40 00 00 02 8A 01
			39 00 00 40 00 00 03 8B A0 21
			39 00 00 40 00 00 04 FF 5A A5 31
			39 00 00 40 00 00 02 D0 80
			39 00 00 40 00 00 04 FF 5A A5 08
			39 00 00 40 00 00 02 C8 62
			39 00 00 40 00 00 04 FF 5A A5 21
			39 00 00 40 00 00 02 A4 38
			39 00 00 40 00 00 04 FF 5A A5 23
			39 00 00 40 00 00 02 85 15
			39 00 00 40 00 00 04 FF 5A A5 00
			39 00 00 40 00 00 02 5E 01
			39 00 00 40 00 00 02 60 00
			39 00 00 40 00 00 02 61 0F
			39 00 00 40 00 00 02 6D 01
			39 00 00 40 00 00 02 35 00
			39 00 00 40 00 00 02 53 20
			39 00 00 40 00 00 03 51 00 00
			39 00 00 40 00 00 04 FF 5A A5 00

			39 00 00 40 00 00 04 FF 5A A5 03 //pcd
			39 00 00 40 00 00 02 BD 91
			39 00 00 40 00 00 04 FF 5A A5 00

			39 00 00 40 00 00 04 FF 5A A5 1E //lhbm
			39 00 00 40 00 00 02 C0 10
			39 00 00 40 00 00 04 C1 70 9C C9
			39 00 00 40 00 00 08 C2 FF FF FF 78 E5 7A F0
			39 00 00 40 00 00 27 C5 44 00 00 44 00 00 44 00 00 44 00 00 44 00 00 42 02 EB 21 23 90 10 08 00 00 00 00 00 00 00 00 00 00 00 00 00 00 00
			39 00 00 40 00 00 27 C7 55 FF FF 55 FF FF 54 10 FF 43 80 80 44 00 00 33 90 6B 32 0C AE 20 50 00 00 00 00 00 00 00 00 00 00 00 00 00 00 00
			39 00 00 40 00 00 09 C8 44 00 00 44 00 00 14 00
			39 00 00 40 00 00 02 C9 00
			39 00 00 40 00 00 1a CA EC EC ED ED EE EF F8 FF FC FC F2 FB FF FF FF FF FF FF FF FF FF FF FF FF FF
			39 00 00 40 00 00 1a CB F0 F0 F0 F1 F1 F2 FA FF FF FE EB F0 F2 FF FE FB FF F9 FF FF FF FF FF FF FF
			39 00 00 40 00 00 1a CC EC EC EC ED EE EF F9 FF FF FE E9 ED EF F1 F4 F5 F4 F4 FF FF FF FF FF FF FF
			39 00 00 40 00 00 04 FF 5A A5 24
			39 00 00 40 00 00 02 80 0E
			39 00 00 40 00 00 02 81 11
			39 00 00 40 00 00 02 84 1F
			39 00 00 40 00 00 04 FF 5A A5 00
			39 00 00 40 00 00 02 95 FF
			39 00 00 40 00 00 02 96 0B
			39 00 00 40 00 00 02 97 40
			39 00 00 40 00 00 02 98 02
			39 00 00 40 00 00 02 99 D0

			39 00 00 40 00 00 04 FF 5A A5 00 //24hz
			39 00 00 40 00 00 02 60 00
			39 00 00 40 00 00 02 53 28 //dimming enable
			39 00 00 40 00 00 04 FF 5A A5 2D
			39 00 00 40 00 00 02 83 04
			39 00 00 40 00 00 02 F2 04 //TE
			39 00 00 40 00 00 02 CD 21 //dimming enable
			39 00 00 40 00 00 04 FF 5A A5 24
			39 00 00 40 00 00 03 85 31 80 //dimming enable
			39 00 00 40 00 00 03 86 31 80 //dimming enable

			39 00 00 40 00 00 04 FF 5A A5 08 //esd check
			39 00 00 40 00 00 02 D2 01
			39 00 00 40 00 00 02 D3 00
			39 00 00 40 00 00 02 D4 00
			39 00 00 40 00 00 09 ED FF FF FF FF FF FF FF FF
			39 00 00 40 00 00 09 EE FF FF FF FF FF FF FF FF
			39 00 00 40 00 00 04 FF 5A A5 00

			39 00 00 40 00 00 04 FF 5A A5 2D //1hz transition frame
                     	39 00 00 40 00 00 02 97 03
                     	39 00 00 40 00 00 02 B1 03
                     	39 00 00 40 00 00 03 98 03 00
                     	39 00 00 40 00 00 03 99 05 00
                     	39 00 00 40 00 00 03 9A 0B 00
                     	39 00 00 40 00 00 03 9B 17 00
                     	39 00 00 40 00 00 03 A0 00 00
                     	39 00 00 40 00 00 03 A1 01 02

			39 00 00 40 00 00 04 FF 5A A5 08 //esd check fail fix
			39 00 00 40 00 00 02 F5 00
			39 00 00 40 00 00 02 F6 00
			39 00 00 40 00 00 02 F7 00

			39 00 00 40 00 00 04 FF 5A A5 2D //DBV DIMMING for low refreshrate
                     	39 00 00 40 00 00 02 CE 55

			39 00 00 40 00 00 04 FF 5A A5 00 //scale enable
			39 00 00 40 00 00 02 4B 01
			39 00 00 40 00 00 04 FF 5A A5 04
			39 00 00 40 00 00 02 CF 00
			39 00 00 40 00 00 02 D0 03
			39 00 00 40 00 00 02 D1 00
			39 00 00 40 00 00 02 D2 04
			39 00 00 40 00 00 02 D4 00
			39 00 00 40 00 00 02 D5 C0
			39 00 00 40 00 00 02 D6 00
			39 00 00 40 00 00 02 E0 04
			39 00 00 40 00 00 02 E1 38
			39 00 00 40 00 00 02 E2 09
			39 00 00 40 00 00 02 E3 48
			39 00 00 40 00 00 12 ED 00 00 04 C0 00 00 04 C0 00 33 00 00 00 00 00 00 00
			39 00 00 00 00 00 04 FF 5A A5 00

			05 00 00 00 78 00 01 11 //Delay 120ms
			05 00 00 00 14 00 01 29];	/* display on */
		qcom,mdss-dsi-off-command = [
			39 00 00 40 00 00 04 FF 5A A5 00
			05 00 00 00 14 00 01 28		/* display_off */
			05 00 00 00 78 00 01 10];	/* enter sleep mode */

		qcom,mdss-dsi-on-command-state = "dsi_lp_mode";
		qcom,mdss-dsi-off-command-state = "dsi_lp_mode";
		qcom,mdss-dsi-timing-switch-command-state = "dsi_lp_mode";
		qcom,compression-mode = "dsc";
		/* Why QCOM doesn't use this, even it used 2 encoder
		 * as for that dsi_sw43404_amoled_cmd, for ex */
		/* qcom,mdss-dsc-encoders = <2>; */
		qcom,mdss-dsc-version = <0x11>;
		qcom,mdss-dsc-slice-height = <18>;
		qcom,mdss-dsc-slice-width = <540>;
		qcom,mdss-dsc-slice-per-pkt = <2>;
		qcom,mdss-dsc-bit-per-component = <10>;
		qcom,mdss-dsc-bit-per-pixel = <8>;
		qcom,mdss-dsc-block-prediction-enable;
		qcom,mdss-dsi-pcd-check-enable-command = [
			39 00 00 00 00 00 04 FF 5A A5 03
			];
		qcom,mdss-dsi-pcd-check-enable-command-state = "dsi_hs_mode";
		qcom,mdss-dsi-pcd-check-disable-command = [
			39 00 00 00 00 00 04 FF 5A A5 00
			];
		qcom,mdss-dsi-pcd-check-disable-command-state = "dsi_hs_mode";
	};
	timing@14{
		qcom,mdss-dsi-cmd-mode;
		qcom,mdss-dsi-panel-framerate = <120>; //actually 10hz
		qcom,mdss-dsi-panel-width = <1080>;
		qcom,mdss-dsi-panel-height = <2376>;
		qcom,mdss-dsi-h-front-porch = <20>;
		qcom,mdss-dsi-h-back-porch = <16>;
		qcom,mdss-dsi-h-pulse-width = <16>;
		qcom,mdss-dsi-h-sync-skew = <0>;
		qcom,mdss-dsi-h-sync-pulse = <0>;
		qcom,mdss-dsi-v-back-porch = <2>;
		qcom,mdss-dsi-v-front-porch = <2>;
		qcom,mdss-dsi-v-pulse-width = <2>;
		qcom,mdss-dsi-h-left-border = <0>;
		qcom,mdss-dsi-h-right-border = <0>;
		qcom,mdss-dsi-v-top-border = <0>;
		qcom,mdss-dsi-v-bottom-border = <0>;
	        qcom,mdss-dsi-panel-jitter = <0x20 0xa>;
	        qcom,mdss-mdp-transfer-time-us = <7933>;
	        qcom,mdss-dsi-timing-switch-command = [
	        	39 00 00 40 00 00 04 FF 5A A5 00 //10hz
			39 00 00 40 00 00 02 60 00
			39 00 00 40 00 00 02 53 20 //dimming disable
			39 00 00 40 00 00 04 FF 5A A5 2D
			39 00 00 40 00 00 02 83 0B
			39 00 00 40 00 00 02 F2 00 //TE
			39 00 00 40 00 00 02 CD 01 //dimming disable
			39 00 00 40 00 00 04 FF 5A A5 24
			39 00 00 40 00 00 03 85 31 00 //dimming disable
			39 00 00 40 00 00 03 86 31 00 //dimming disable
			39 00 00 00 00 00 04 FF 5A A5 00

			39 00 00 40 00 00 04 FF 5A A5 00 //scale enable
			39 00 00 40 00 00 02 4B 01
			39 00 00 40 00 00 04 FF 5A A5 04
			39 00 00 40 00 00 02 CF 00
			39 00 00 40 00 00 02 D0 03
			39 00 00 40 00 00 02 D1 00
			39 00 00 40 00 00 02 D2 04
			39 00 00 40 00 00 02 D4 00
			39 00 00 40 00 00 02 D5 C0
			39 00 00 40 00 00 02 D6 00
			39 00 00 40 00 00 02 E0 04
			39 00 00 40 00 00 02 E1 38
			39 00 00 40 00 00 02 E2 09
			39 00 00 40 00 00 02 E3 48
			39 00 00 40 00 00 12 ED 00 00 04 C0 00 00 04 C0 00 33 00 00 00 00 00 00 00

			39 00 00 40 00 00 04 FF 5A A5 07 //10bit 3.75x
			39 00 00 40 00 00 02 8A 01
			39 00 00 40 00 00 03 8B A0 21
			39 00 00 40 00 00 0B 81 00 00 00 00 00 11 00 00 AB 30
                     	39 00 00 40 00 00 0B FE 80 09 48 04 38 00 12 02 1C 02
                     	39 00 00 40 00 00 0B FE 1C 02 00 02 0E 00 20 01 B6 00
                     	39 00 00 40 00 00 0B FE 07 00 0C 05 A6 05 A7 18 00 10
                     	39 00 00 40 00 00 0B FE F0 07 10 20 00 06 0F 0F 33 0E
                     	39 00 00 40 00 00 0B FE 1C 2A 38 46 54 62 69 70 77 79
                     	39 00 00 40 00 00 0B FE 7B 7D 7E 01 02 22 00 2A 40 2A
                     	39 00 00 40 00 00 0B FE BE 3A FC 3A FA 3A F8 3B 38 3B
                     	39 00 00 40 00 00 0B FE 78 3B B6 4B F6 4C 34 4C 74 5C
                     	39 00 00 40 00 00 0A FE 74 8C F4 00 00 00 00 00 00
			39 00 00 00 00 00 04 FF 5A A5 00
	        ];
		qcom,mdss-dsi-on-command = [
			39 00 00 40 00 00 04 FF 5A A5 07 //10bit 3.75x
			39 00 00 40 00 00 02 8A 01
			39 00 00 40 00 00 03 8B A0 21
			39 00 00 40 00 00 0B 81 00 00 00 00 00 11 00 00 AB 30
                     	39 00 00 40 00 00 0B FE 80 09 48 04 38 00 12 02 1C 02
                     	39 00 00 40 00 00 0B FE 1C 02 00 02 0E 00 20 01 B6 00
                     	39 00 00 40 00 00 0B FE 07 00 0C 05 A6 05 A7 18 00 10
                     	39 00 00 40 00 00 0B FE F0 07 10 20 00 06 0F 0F 33 0E
                     	39 00 00 40 00 00 0B FE 1C 2A 38 46 54 62 69 70 77 79
                     	39 00 00 40 00 00 0B FE 7B 7D 7E 01 02 22 00 2A 40 2A
                     	39 00 00 40 00 00 0B FE BE 3A FC 3A FA 3A F8 3B 38 3B
                     	39 00 00 40 00 00 0B FE 78 3B B6 4B F6 4C 34 4C 74 5C
                     	39 00 00 40 00 00 0A FE 74 8C F4 00 00 00 00 00 00

			39 00 00 40 00 00 04 FF 5A A5 07
			39 00 00 40 00 00 02 8A 01
			39 00 00 40 00 00 03 8B A0 21
			39 00 00 40 00 00 04 FF 5A A5 31
			39 00 00 40 00 00 02 D0 80
			39 00 00 40 00 00 04 FF 5A A5 08
			39 00 00 40 00 00 02 C8 62
			39 00 00 40 00 00 04 FF 5A A5 21
			39 00 00 40 00 00 02 A4 38
			39 00 00 40 00 00 04 FF 5A A5 23
			39 00 00 40 00 00 02 85 15
			39 00 00 40 00 00 04 FF 5A A5 00
			39 00 00 40 00 00 02 5E 01
			39 00 00 40 00 00 02 60 00
			39 00 00 40 00 00 02 61 0F
			39 00 00 40 00 00 02 6D 01
			39 00 00 40 00 00 02 35 00
			39 00 00 40 00 00 02 53 20
			39 00 00 40 00 00 03 51 00 00
			39 00 00 40 00 00 04 FF 5A A5 00

			39 00 00 40 00 00 04 FF 5A A5 03 //pcd
			39 00 00 40 00 00 02 BD 91
			39 00 00 40 00 00 04 FF 5A A5 00

			39 00 00 40 00 00 04 FF 5A A5 1E //lhbm
			39 00 00 40 00 00 02 C0 10
			39 00 00 40 00 00 04 C1 70 9C C9
			39 00 00 40 00 00 08 C2 FF FF FF 78 E5 7A F0
			39 00 00 40 00 00 27 C5 44 00 00 44 00 00 44 00 00 44 00 00 44 00 00 42 02 EB 21 23 90 10 08 00 00 00 00 00 00 00 00 00 00 00 00 00 00 00
			39 00 00 40 00 00 27 C7 55 FF FF 55 FF FF 54 10 FF 43 80 80 44 00 00 33 90 6B 32 0C AE 20 50 00 00 00 00 00 00 00 00 00 00 00 00 00 00 00
			39 00 00 40 00 00 09 C8 44 00 00 44 00 00 14 00
			39 00 00 40 00 00 02 C9 00
			39 00 00 40 00 00 1a CA EC EC ED ED EE EF F8 FF FC FC F2 FB FF FF FF FF FF FF FF FF FF FF FF FF FF
			39 00 00 40 00 00 1a CB F0 F0 F0 F1 F1 F2 FA FF FF FE EB F0 F2 FF FE FB FF F9 FF FF FF FF FF FF FF
			39 00 00 40 00 00 1a CC EC EC EC ED EE EF F9 FF FF FE E9 ED EF F1 F4 F5 F4 F4 FF FF FF FF FF FF FF
			39 00 00 40 00 00 04 FF 5A A5 24
			39 00 00 40 00 00 02 80 0E
			39 00 00 40 00 00 02 81 11
			39 00 00 40 00 00 02 84 1F
			39 00 00 40 00 00 04 FF 5A A5 00
			39 00 00 40 00 00 02 95 FF
			39 00 00 40 00 00 02 96 0B
			39 00 00 40 00 00 02 97 40
			39 00 00 40 00 00 02 98 02
			39 00 00 40 00 00 02 99 D0

			39 00 00 40 00 00 04 FF 5A A5 00 //10hz
			39 00 00 40 00 00 02 60 00
			39 00 00 40 00 00 02 53 20 //dimming disable
			39 00 00 40 00 00 04 FF 5A A5 2D
			39 00 00 40 00 00 02 83 0B
			39 00 00 40 00 00 02 F2 00 //TE
			39 00 00 40 00 00 02 CD 01 //dimming disable
			39 00 00 40 00 00 04 FF 5A A5 24
			39 00 00 40 00 00 03 85 31 00 //dimming disable
			39 00 00 40 00 00 03 86 31 00 //dimming disable

			39 00 00 40 00 00 04 FF 5A A5 08 //esd check
			39 00 00 40 00 00 02 D2 01
			39 00 00 40 00 00 02 D3 00
			39 00 00 40 00 00 02 D4 00
			39 00 00 40 00 00 09 ED FF FF FF FF FF FF FF FF
			39 00 00 40 00 00 09 EE FF FF FF FF FF FF FF FF
			39 00 00 40 00 00 04 FF 5A A5 00

			39 00 00 40 00 00 04 FF 5A A5 2D //1hz transition frame
                     	39 00 00 40 00 00 02 97 03
                     	39 00 00 40 00 00 02 B1 03
                     	39 00 00 40 00 00 03 98 03 00
                     	39 00 00 40 00 00 03 99 05 00
                     	39 00 00 40 00 00 03 9A 0B 00
                     	39 00 00 40 00 00 03 9B 17 00
                     	39 00 00 40 00 00 03 A0 00 00
                     	39 00 00 40 00 00 03 A1 01 02

			39 00 00 40 00 00 04 FF 5A A5 08 //esd check fail fix
			39 00 00 40 00 00 02 F5 00
			39 00 00 40 00 00 02 F6 00
			39 00 00 40 00 00 02 F7 00

			39 00 00 40 00 00 04 FF 5A A5 2D //DBV DIMMING for low refreshrate
                     	39 00 00 40 00 00 02 CE 55

			39 00 00 40 00 00 04 FF 5A A5 00 //scale enable
			39 00 00 40 00 00 02 4B 01
			39 00 00 40 00 00 04 FF 5A A5 04
			39 00 00 40 00 00 02 CF 00
			39 00 00 40 00 00 02 D0 03
			39 00 00 40 00 00 02 D1 00
			39 00 00 40 00 00 02 D2 04
			39 00 00 40 00 00 02 D4 00
			39 00 00 40 00 00 02 D5 C0
			39 00 00 40 00 00 02 D6 00
			39 00 00 40 00 00 02 E0 04
			39 00 00 40 00 00 02 E1 38
			39 00 00 40 00 00 02 E2 09
			39 00 00 40 00 00 02 E3 48
			39 00 00 40 00 00 12 ED 00 00 04 C0 00 00 04 C0 00 33 00 00 00 00 00 00 00
			39 00 00 00 00 00 04 FF 5A A5 00

			05 00 00 00 78 00 01 11 //Delay 120ms
			05 00 00 00 14 00 01 29];	/* display on */
		qcom,mdss-dsi-off-command = [
			39 00 00 40 00 00 04 FF 5A A5 00
			05 00 00 00 14 00 01 28		/* display_off */
			05 00 00 00 78 00 01 10];	/* enter sleep mode */

		qcom,mdss-dsi-on-command-state = "dsi_lp_mode";
		qcom,mdss-dsi-off-command-state = "dsi_lp_mode";
		qcom,mdss-dsi-timing-switch-command-state = "dsi_lp_mode";
		qcom,compression-mode = "dsc";
		/* Why QCOM doesn't use this, even it used 2 encoder
		 * as for that dsi_sw43404_amoled_cmd, for ex */
		/* qcom,mdss-dsc-encoders = <2>; */
		qcom,mdss-dsc-version = <0x11>;
		qcom,mdss-dsc-slice-height = <18>;
		qcom,mdss-dsc-slice-width = <540>;
		qcom,mdss-dsc-slice-per-pkt = <2>;
		qcom,mdss-dsc-bit-per-component = <10>;
		qcom,mdss-dsc-bit-per-pixel = <8>;
		qcom,mdss-dsc-block-prediction-enable;
		qcom,mdss-dsi-pcd-check-enable-command = [
			39 00 00 00 00 00 04 FF 5A A5 03
			];
		qcom,mdss-dsi-pcd-check-enable-command-state = "dsi_hs_mode";
		qcom,mdss-dsi-pcd-check-disable-command = [
			39 00 00 00 00 00 04 FF 5A A5 00
			];
		qcom,mdss-dsi-pcd-check-disable-command-state = "dsi_hs_mode";
	};
	timing@15{
		qcom,mdss-dsi-cmd-mode;
		qcom,mdss-dsi-panel-framerate = <120>; //actually 1hz
		qcom,mdss-dsi-panel-width = <1080>;
		qcom,mdss-dsi-panel-height = <2376>;
		qcom,mdss-dsi-h-front-porch = <12>;
		qcom,mdss-dsi-h-back-porch = <16>;
		qcom,mdss-dsi-h-pulse-width = <16>;
		qcom,mdss-dsi-h-sync-skew = <0>;
		qcom,mdss-dsi-h-sync-pulse = <0>;
		qcom,mdss-dsi-v-back-porch = <2>;
		qcom,mdss-dsi-v-front-porch = <2>;
		qcom,mdss-dsi-v-pulse-width = <2>;
		qcom,mdss-dsi-h-left-border = <0>;
		qcom,mdss-dsi-h-right-border = <0>;
		qcom,mdss-dsi-v-top-border = <0>;
		qcom,mdss-dsi-v-bottom-border = <0>;
	        qcom,mdss-dsi-panel-jitter = <0x20 0xa>;
	        qcom,mdss-mdp-transfer-time-us = <7933>;
	        qcom,mdss-dsi-timing-switch-command = [
	        	39 00 00 40 00 00 04 FF 5A A5 00 //1hz
			39 00 00 40 00 00 02 60 00
			39 00 00 40 00 00 02 53 20 //dimming disable
			39 00 00 40 00 00 04 FF 5A A5 2D
			39 00 00 40 00 00 02 83 77
			39 00 00 40 00 00 02 F2 00 //TE
			39 00 00 40 00 00 02 CD 01 //dimming disable
			39 00 00 40 00 00 04 FF 5A A5 24
			39 00 00 40 00 00 03 85 31 00 //dimming disable
			39 00 00 40 00 00 03 86 31 00 //dimming disable
			39 00 00 00 00 00 04 FF 5A A5 00

			39 00 00 40 00 00 04 FF 5A A5 00 //scale enable
			39 00 00 40 00 00 02 4B 01
			39 00 00 40 00 00 04 FF 5A A5 04
			39 00 00 40 00 00 02 CF 00
			39 00 00 40 00 00 02 D0 03
			39 00 00 40 00 00 02 D1 00
			39 00 00 40 00 00 02 D2 04
			39 00 00 40 00 00 02 D4 00
			39 00 00 40 00 00 02 D5 C0
			39 00 00 40 00 00 02 D6 00
			39 00 00 40 00 00 02 E0 04
			39 00 00 40 00 00 02 E1 38
			39 00 00 40 00 00 02 E2 09
			39 00 00 40 00 00 02 E3 48
			39 00 00 40 00 00 12 ED 00 00 04 C0 00 00 04 C0 00 33 00 00 00 00 00 00 00

			39 00 00 40 00 00 04 FF 5A A5 07 //10bit 3.75x
			39 00 00 40 00 00 02 8A 01
			39 00 00 40 00 00 03 8B A0 21
			39 00 00 40 00 00 0B 81 00 00 00 00 00 11 00 00 AB 30
                     	39 00 00 40 00 00 0B FE 80 09 48 04 38 00 12 02 1C 02
                     	39 00 00 40 00 00 0B FE 1C 02 00 02 0E 00 20 01 B6 00
                     	39 00 00 40 00 00 0B FE 07 00 0C 05 A6 05 A7 18 00 10
                     	39 00 00 40 00 00 0B FE F0 07 10 20 00 06 0F 0F 33 0E
                     	39 00 00 40 00 00 0B FE 1C 2A 38 46 54 62 69 70 77 79
                     	39 00 00 40 00 00 0B FE 7B 7D 7E 01 02 22 00 2A 40 2A
                     	39 00 00 40 00 00 0B FE BE 3A FC 3A FA 3A F8 3B 38 3B
                     	39 00 00 40 00 00 0B FE 78 3B B6 4B F6 4C 34 4C 74 5C
                     	39 00 00 40 00 00 0A FE 74 8C F4 00 00 00 00 00 00
			39 00 00 00 00 00 04 FF 5A A5 00
	        ];
		qcom,mdss-dsi-on-command = [
			39 00 00 40 00 00 04 FF 5A A5 07 //10bit 3.75x
			39 00 00 40 00 00 02 8A 01
			39 00 00 40 00 00 03 8B A0 21
			39 00 00 40 00 00 0B 81 00 00 00 00 00 11 00 00 AB 30
                     	39 00 00 40 00 00 0B FE 80 09 48 04 38 00 12 02 1C 02
                     	39 00 00 40 00 00 0B FE 1C 02 00 02 0E 00 20 01 B6 00
                     	39 00 00 40 00 00 0B FE 07 00 0C 05 A6 05 A7 18 00 10
                     	39 00 00 40 00 00 0B FE F0 07 10 20 00 06 0F 0F 33 0E
                     	39 00 00 40 00 00 0B FE 1C 2A 38 46 54 62 69 70 77 79
                     	39 00 00 40 00 00 0B FE 7B 7D 7E 01 02 22 00 2A 40 2A
                     	39 00 00 40 00 00 0B FE BE 3A FC 3A FA 3A F8 3B 38 3B
                     	39 00 00 40 00 00 0B FE 78 3B B6 4B F6 4C 34 4C 74 5C
                     	39 00 00 40 00 00 0A FE 74 8C F4 00 00 00 00 00 00

			39 00 00 40 00 00 04 FF 5A A5 07
			39 00 00 40 00 00 02 8A 01
			39 00 00 40 00 00 03 8B A0 21
			39 00 00 40 00 00 04 FF 5A A5 31
			39 00 00 40 00 00 02 D0 80
			39 00 00 40 00 00 04 FF 5A A5 08
			39 00 00 40 00 00 02 C8 62
			39 00 00 40 00 00 04 FF 5A A5 21
			39 00 00 40 00 00 02 A4 38
			39 00 00 40 00 00 04 FF 5A A5 23
			39 00 00 40 00 00 02 85 15
			39 00 00 40 00 00 04 FF 5A A5 00
			39 00 00 40 00 00 02 5E 01
			39 00 00 40 00 00 02 60 00
			39 00 00 40 00 00 02 61 0F
			39 00 00 40 00 00 02 6D 01
			39 00 00 40 00 00 02 35 00
			39 00 00 40 00 00 02 53 20
			39 00 00 40 00 00 03 51 00 00
			39 00 00 40 00 00 04 FF 5A A5 00

			39 00 00 40 00 00 04 FF 5A A5 03 //pcd
			39 00 00 40 00 00 02 BD 91
			39 00 00 40 00 00 04 FF 5A A5 00

			39 00 00 40 00 00 04 FF 5A A5 1E //lhbm
			39 00 00 40 00 00 02 C0 10
			39 00 00 40 00 00 04 C1 70 9C C9
			39 00 00 40 00 00 08 C2 FF FF FF 78 E5 7A F0
			39 00 00 40 00 00 27 C5 44 00 00 44 00 00 44 00 00 44 00 00 44 00 00 42 02 EB 21 23 90 10 08 00 00 00 00 00 00 00 00 00 00 00 00 00 00 00
			39 00 00 40 00 00 27 C7 55 FF FF 55 FF FF 54 10 FF 43 80 80 44 00 00 33 90 6B 32 0C AE 20 50 00 00 00 00 00 00 00 00 00 00 00 00 00 00 00
			39 00 00 40 00 00 09 C8 44 00 00 44 00 00 14 00
			39 00 00 40 00 00 02 C9 00
			39 00 00 40 00 00 1a CA EC EC ED ED EE EF F8 FF FC FC F2 FB FF FF FF FF FF FF FF FF FF FF FF FF FF
			39 00 00 40 00 00 1a CB F0 F0 F0 F1 F1 F2 FA FF FF FE EB F0 F2 FF FE FB FF F9 FF FF FF FF FF FF FF
			39 00 00 40 00 00 1a CC EC EC EC ED EE EF F9 FF FF FE E9 ED EF F1 F4 F5 F4 F4 FF FF FF FF FF FF FF
			39 00 00 40 00 00 04 FF 5A A5 24
			39 00 00 40 00 00 02 80 0E
			39 00 00 40 00 00 02 81 11
			39 00 00 40 00 00 02 84 1F
			39 00 00 40 00 00 04 FF 5A A5 00
			39 00 00 40 00 00 02 95 FF
			39 00 00 40 00 00 02 96 0B
			39 00 00 40 00 00 02 97 40
			39 00 00 40 00 00 02 98 02
			39 00 00 40 00 00 02 99 D0

			39 00 00 40 00 00 04 FF 5A A5 00 //1hz
			39 00 00 40 00 00 02 60 00
			39 00 00 40 00 00 02 53 20 //dimming disable
			39 00 00 40 00 00 04 FF 5A A5 2D
			39 00 00 40 00 00 02 83 77
			39 00 00 40 00 00 02 F2 00 //TE
			39 00 00 40 00 00 02 CD 01 //dimming disable
			39 00 00 40 00 00 04 FF 5A A5 24
			39 00 00 40 00 00 03 85 31 00 //dimming disable
			39 00 00 40 00 00 03 86 31 00 //dimming disable

			39 00 00 40 00 00 04 FF 5A A5 08 //esd check
			39 00 00 40 00 00 02 D2 01
			39 00 00 40 00 00 02 D3 00
			39 00 00 40 00 00 02 D4 00
			39 00 00 40 00 00 09 ED FF FF FF FF FF FF FF FF
			39 00 00 40 00 00 09 EE FF FF FF FF FF FF FF FF
			39 00 00 40 00 00 04 FF 5A A5 00

			39 00 00 40 00 00 04 FF 5A A5 2D //1hz transition frame
                     	39 00 00 40 00 00 02 97 03
                     	39 00 00 40 00 00 02 B1 03
                     	39 00 00 40 00 00 03 98 03 00
                     	39 00 00 40 00 00 03 99 05 00
                     	39 00 00 40 00 00 03 9A 0B 00
                     	39 00 00 40 00 00 03 9B 17 00
                     	39 00 00 40 00 00 03 A0 00 00
                     	39 00 00 40 00 00 03 A1 01 02

			39 00 00 40 00 00 04 FF 5A A5 08 //esd check fail fix
			39 00 00 40 00 00 02 F5 00
			39 00 00 40 00 00 02 F6 00
			39 00 00 40 00 00 02 F7 00

			39 00 00 40 00 00 04 FF 5A A5 2D //DBV DIMMING for low refreshrate
                     	39 00 00 40 00 00 02 CE 55

			39 00 00 40 00 00 04 FF 5A A5 00 //scale enable
			39 00 00 40 00 00 02 4B 01
			39 00 00 40 00 00 04 FF 5A A5 04
			39 00 00 40 00 00 02 CF 00
			39 00 00 40 00 00 02 D0 03
			39 00 00 40 00 00 02 D1 00
			39 00 00 40 00 00 02 D2 04
			39 00 00 40 00 00 02 D4 00
			39 00 00 40 00 00 02 D5 C0
			39 00 00 40 00 00 02 D6 00
			39 00 00 40 00 00 02 E0 04
			39 00 00 40 00 00 02 E1 38
			39 00 00 40 00 00 02 E2 09
			39 00 00 40 00 00 02 E3 48
			39 00 00 40 00 00 12 ED 00 00 04 C0 00 00 04 C0 00 33 00 00 00 00 00 00 00
			39 00 00 00 00 00 04 FF 5A A5 00

			05 00 00 00 78 00 01 11 //Delay 120ms
			05 00 00 00 14 00 01 29];	/* display on */
		qcom,mdss-dsi-off-command = [
			39 00 00 40 00 00 04 FF 5A A5 00
			05 00 00 00 14 00 01 28		/* display_off */
			05 00 00 00 78 00 01 10];	/* enter sleep mode */

		qcom,mdss-dsi-on-command-state = "dsi_lp_mode";
		qcom,mdss-dsi-off-command-state = "dsi_lp_mode";
		qcom,mdss-dsi-timing-switch-command-state = "dsi_lp_mode";
		qcom,compression-mode = "dsc";
		/* Why QCOM doesn't use this, even it used 2 encoder
		 * as for that dsi_sw43404_amoled_cmd, for ex */
		/* qcom,mdss-dsc-encoders = <2>; */
		qcom,mdss-dsc-version = <0x11>;
		qcom,mdss-dsc-slice-height = <18>;
		qcom,mdss-dsc-slice-width = <540>;
		qcom,mdss-dsc-slice-per-pkt = <2>;
		qcom,mdss-dsc-bit-per-component = <10>;
		qcom,mdss-dsc-bit-per-pixel = <8>;
		qcom,mdss-dsc-block-prediction-enable;
		qcom,mdss-dsi-pcd-check-enable-command = [
			39 00 00 00 00 00 04 FF 5A A5 03
			];
		qcom,mdss-dsi-pcd-check-enable-command-state = "dsi_hs_mode";
		qcom,mdss-dsi-pcd-check-disable-command = [
			39 00 00 00 00 00 04 FF 5A A5 00
			];
		qcom,mdss-dsi-pcd-check-disable-command-state = "dsi_hs_mode";
	};
};

};

};
